VERSION ""

NS_ :

BS_:

BU_: MPAD CVADAS ADCAM ORC EVCU2 EPS ECM CVPAM CADM BSM2 BSM

BO_ 727 CVPAM_FD_Data2: 64 CVADAS
 SG_ PA_SideSensor_RearRight_Dist : 49|10@0+ (1,0) [0|1022] "cm"  MPAD,CADM
 SG_ PA_SideSensor_RearRight_Conf : 102|2@0+ (1,0) [0|3] "" MPAD,CADM
 SG_ PA_SideSensor_RearLeft_Dist : 33|10@0+ (1,0) [0|1022] "cm"  MPAD,CADM
 SG_ PA_SideSensor_RearLeft_Conf : 100|2@0+ (1,0) [0|3] "" MPAD,CADM
 SG_ PA_SideSensor_FrontRight_Dist : 1|10@0+ (1,0) [0|1022] "cm"  MPAD,CADM
 SG_ PA_SideSensor_FrontRight_Conf : 55|2@0+ (1,0) [0|3] "" MPAD,CADM
 SG_ PA_SideSensor_FrontLeft_Dist : 17|10@0+ (1,0) [0|1022] "cm"  MPAD,CADM
 SG_ PA_SideSensor_FrontLeft_Conf : 98|2@0+ (1,0) [0|3] "" MPAD,CADM
 SG_ PA_Right_Sensor_Det_Health : 23|2@0+ (1,0) [0|2] "" MPAD,CADM
 SG_ PA_Line_RM_Style : 68|4@0+ (1,0) [0|7] "" MPAD,CADM
 SG_ PA_Line_RM_Heading : 96|9@0+ (0.5,-128) [-128|127.5] "deg"  MPAD,CADM
 SG_ PA_Line_RM_Color : 87|3@0+ (1,0) [0|4] "" MPAD,CADM
 SG_ PA_Line_LM_Style : 84|4@0+ (1,0) [0|7] "" MPAD,CADM
 SG_ PA_Line_LM_Heading : 112|9@0+ (0.5,-128) [-128|127.5] "deg"  MPAD,CADM
 SG_ PA_Line_LM_Color : 71|3@0+ (1,0) [0|4] "" MPAD,CADM
 SG_ PA_Left_Sensor_Det_Health : 7|2@0+ (1,0) [0|2] "" MPAD,CADM
 SG_ PA_Lane_Dection_Health : 39|2@0+ (1,0) [0|2] "" MPAD,CADM
 SG_ MessageCounter_CVPAM_FD_Data2 : 435|4@0+ (1,0) [0|15] "-"  MPAD,CADM
 SG_ MAC_CVPAM_FD_Data2 : 471|48@0+ (1,0) [0|0] "-"  MPAD,CADM
 SG_ CRC_CVPAM_FD_Data2 : 447|8@0+ (1,0) [0|255] "-"  MPAD,CADM
 SG_ Cntr_CVPAM_FD_Data2 : 455|16@0+ (1,0) [0|65535] "-"  MPAD,CADM
 SG_ Reserved_for_Functional_Safety_ : 431|12@0+ (0,0) [0|0] "" MPAD,CADM
 SG_ PA_Line_RM_Heading_Conf : 37|4@0+ (1,0) [0|15] "" MPAD,CADM
 SG_ PA_Line_RM_Distance_Conf : 5|4@0+ (1,0) [0|15] "" MPAD,CADM
 SG_ PA_Line_RM_Distance : 64|9@0+ (1,0) [0|511] "cm"  MPAD,CADM
 SG_ PA_Line_LM_Heading_Conf : 53|4@0+ (1,0) [0|15] "" MPAD,CADM
 SG_ PA_Line_LM_Distance_Conf : 21|4@0+ (1,0) [0|15] "" MPAD,CADM
 SG_ PA_Line_LM_Distance : 80|9@0+ (1,0) [0|511] "cm"  MPAD,CADM

BO_ 726 CVPAM_FD_Data: 64 CVADAS
 SG_ PA_Obj6_Type : 372|3@0+ (1,0) [0|7] "" MPAD,CADM
 SG_ PA_Obj6_Range_2 : 401|10@0+ (1,0) [0|1023] "cm"  MPAD,CADM
 SG_ PA_Obj6_Range : 81|10@0+ (1,0) [0|1023] "cm"  MPAD,CADM
 SG_ PA_Obj6_Conf : 115|2@0+ (1,0) [0|3] "" MPAD,CADM
 SG_ PA_Obj6_Angle_2 : 208|9@0+ (1,0) [0|511] "deg"  MPAD,CADM
 SG_ PA_Obj6_Angle : 304|9@0+ (1,0) [0|511] "deg"  MPAD,CADM
 SG_ PA_Obj5_Type : 375|3@0+ (1,0) [0|7] "" MPAD,CADM
 SG_ PA_Obj5_Range_2 : 385|10@0+ (1,0) [0|1023] "cm"  MPAD,CADM
 SG_ PA_Obj5_Range : 65|10@0+ (1,0) [0|1023] "cm"  MPAD,CADM
 SG_ PA_Obj5_Conf : 117|2@0+ (1,0) [0|3] "" MPAD,CADM
 SG_ PA_Obj5_Angle_2 : 192|9@0+ (1,0) [0|511] "deg"  MPAD,CADM
 SG_ PA_Obj5_Angle : 288|9@0+ (1,0) [0|511] "deg"  MPAD,CADM
 SG_ PA_Obj4_Type : 391|3@0+ (1,0) [0|7] "" MPAD,CADM
 SG_ PA_Obj4_Range_2 : 369|10@0+ (1,0) [0|1023] "cm"  MPAD,CADM
 SG_ PA_Obj4_Range : 49|10@0+ (1,0) [0|1023] "cm"  MPAD,CADM
 SG_ PA_Obj4_Conf : 119|2@0+ (1,0) [0|3] "" MPAD,CADM
 SG_ PA_Obj4_Angle_2 : 176|9@0+ (1,0) [0|511] "deg"  MPAD,CADM
 SG_ PA_Obj4_Angle : 272|9@0+ (1,0) [0|511] "deg"  MPAD,CADM
 SG_ PA_Obj3_Type : 388|3@0+ (1,0) [0|7] "" MPAD,CADM
 SG_ PA_Obj3_Range_2 : 353|10@0+ (1,0) [0|1023] "cm"  MPAD,CADM
 SG_ PA_Obj3_Range : 33|10@0+ (1,0) [0|1023] "cm"  MPAD,CADM
 SG_ PA_Obj3_Conf : 87|2@0+ (1,0) [0|3] "" MPAD,CADM
 SG_ PA_Obj3_Angle_2 : 160|9@0+ (1,0) [0|511] "deg"  MPAD,CADM
 SG_ PA_Obj3_Angle : 256|9@0+ (1,0) [0|511] "deg"  MPAD,CADM
 SG_ PA_Obj2_Type : 404|3@0+ (1,0) [0|7] "" MPAD,CADM
 SG_ PA_Obj2_Range_2 : 337|10@0+ (1,0) [0|1023] "cm"  MPAD,CADM
 SG_ PA_Obj2_Range : 17|10@0+ (1,0) [0|1023] "cm"  MPAD,CADM
 SG_ PA_Obj2_Conf : 71|2@0+ (1,0) [0|3] "" MPAD,CADM
 SG_ PA_Obj2_Angle_2 : 144|9@0+ (1,0) [0|511] "deg"  MPAD,CADM
 SG_ PA_Obj2_Angle : 240|9@0+ (1,0) [0|511] "deg"  MPAD,CADM
 SG_ PA_Obj1_Type : 407|3@0+ (1,0) [0|7] "" MPAD,CADM
 SG_ PA_Obj1_Range_2 : 321|10@0+ (1,0) [0|1023] "cm"  MPAD,CADM
 SG_ PA_Obj1_Range : 1|10@0+ (1,0) [0|1023] "cm"  MPAD,CADM
 SG_ PA_Obj1_Conf : 55|2@0+ (1,0) [0|3] "" MPAD,CADM
 SG_ PA_Obj1_Angle_2 : 128|9@0+ (1,0) [0|511] "deg"  MPAD,CADM
 SG_ PA_Obj1_Angle : 224|9@0+ (1,0) [0|511] "deg"  MPAD,CADM
 SG_ PA_Front_Sensor_Det_Health : 437|2@0+ (1,0) [0|2] "" MPAD,CADM
 SG_ MessageCounter_CVPAM_FD_Data : 435|4@0+ (1,0) [0|15] "-"  MPAD,CADM,EPS
 SG_ MAC_CVPAM_FD_Data : 471|48@0+ (1,0) [0|0] "-"  MPAD,CADM
 SG_ CRC_CVPAM_FD_Data : 447|8@0+ (1,0) [0|255] "-"  MPAD,CADM,EPS
 SG_ Cntr_CVPAM_FD_Data : 455|16@0+ (1,0) [0|65535] "-"  MPAD,CADM
 SG_ Reserved_for_functional_safety_2D6 : 417|12@0+ (0,0) [0|0] "" MPAD,CADM

BO_ 1156 BRAKE2_FD_3: 32 BSM2
 SG_ RollsModeAct_B2 : 6|1@0+ (1,0) [0|1] "" ADCAM,MPAD,CADM
 SG_ MessageCounter_BRAKE2_3 : 179|4@0+ (1,0) [0|15] "-"  CADM,ORC
 SG_ CRC_BRAKE2_3 : 191|8@0+ (1,0) [0|255] "-"  CADM,ORC
 SG_ BSM2_FaultSts : 5|1@0+ (1,0) [0|1] "" CADM
 SG_ ABSFailSts_B2 : 7|1@0+ (1,0) [0|1] "" MPAD,CADM

BO_ 280 ADAS_FD_INFO: 32 ADCAM
 SG_ Object_Dist : 127|8@0+ (1,0) [0|255] "m"  EVCU2,BSM,ORC,ECM
 SG_ MessageCounter_ADAS_FD_INFO : 179|4@0+ (1,0) [0|15] "-"  CVADAS,EVCU2,BSM2,CVPAM,BSM,ORC,EPS,ECM
 SG_ CRC_ADAS_FD_INFO : 191|8@0+ (1,0) [0|255] "-"  CVADAS,EVCU2,BSM2,CVPAM,BSM,ORC,EPS,ECM
 SG_ ACC_DsrSpeedKPH : 119|8@0+ (1,0) [0|255] "km/h"  EVCU2,ECM
 SG_ Intervention : 163|12@0+ (0.01,-16) [-16|24.95] "m/s2"  EVCU2,BSM2,BSM,ORC
 SG_ HIS_Req : 89|1@0+ (1,0) [0|1] "-"  BSM2,BSM,ORC
 SG_ GrMax_Rq_ACC : 150|4@0+ (1,0) [0|15] "-"  BSM
 SG_ CIPV_Fused : 101|1@0+ (1,0) [0|1] "-"  ORC
 SG_ Brake_Jerk_Req : 100|1@0+ (1,0) [0|1] "-"  BSM2,BSM
 SG_ ACC_Wheel_Torque_Enabled : 93|1@0+ (1,0) [0|1] "-"  EVCU2
 SG_ ACC_Engine_Torque_Enabled : 111|1@0+ (1,0) [0|1] "-"  EVCU2,BSM
 SG_ ACC_Drive_Cmd : 151|1@0+ (1,0) [0|1] "-"  BSM
 SG_ Prefill_Req : 91|1@0+ (1,0) [0|1] "-"  BSM2,BSM
 SG_ PEB_SystemSts : 90|1@0+ (1,0) [0|1] "-"  ORC
 SG_ MRM_STATUS : 23|3@0+ (1,0) [0|6] "" CVADAS,EVCU2,BSM,ORC
 SG_ LANE_CHANGE_SIDE : 95|2@0+ (1,0) [0|2] "" ORC
 SG_ HAS_Status : 106|2@0+ (1,0) [0|3] "" CVADAS,ADCAM,BSM2,CVPAM,BSM,EPS
 SG_ HAS_OpStat_Prim : 4|3@0+ (1,0) [0|5] "" ORC
 SG_ HAS_LAT_CTRL_RequestSts : 110|2@0+ (1,0) [0|3] "-"  EPS
 SG_ ESCALATION_TYPE : 12|3@0+ (1,0) [0|4] "" ORC
 SG_ DDD_SystemSts : 103|1@0+ (1,0) [0|1] "-"  ORC
 SG_ DDD_Setting_Avail : 102|1@0+ (1,0) [0|1] "-"  Vector__XXX
 SG_ CADM_OpStat : 7|3@0+ (1,0) [0|5] "" CVADAS
 SG_ AEB_Type : 167|4@0+ (1,0) [0|14] "-"  EVCU2,BSM2,BSM,ORC
 SG_ AEB_Systemsts : 99|2@0+ (1,0) [0|2] "-"  ORC
 SG_ AEB_Sensitivity_Setting : 1|2@0+ (1,0) [0|2] "" Vector__XXX
 SG_ ACC_Wheel_Torque : 79|16@0+ (2,-36878) [-36878|94190] "-"  EVCU2
 SG_ ACC_Systemsts : 183|4@0+ (1,0) [0|14] "-"  CVADAS,ADCAM,EVCU2,BSM2,CVPAM,BSM,ORC
 SG_ ACC_StopStart : 97|2@0+ (1,0) [0|2] "-"  ECM
 SG_ SteeringVibration_Type : 67|4@0+ (1,0) [0|14] "-"  EPS
 SG_ SteeringVibration_Rq : 135|1@0+ (1,0) [0|1] "-"  EPS
 SG_ LKA_LAT_CTRL_RequestSts : 108|2@0+ (1,0) [0|3] "-"  EPS
 SG_ LANE_CHANGE_STATUS : 71|4@0+ (1,0) [0|14] "" ADCAM,ORC
 SG_ LC_Jerk : 104|1@0+ (1,0) [0|1] "-"  BSM
 SG_ CADM2_EPSSEC_FAIL : 8|1@0+ (1,0) [0|1] "" EPS
 SG_ TorqueOverlaySteeringReq : 130|11@0+ (0.0048828125,-5) [-5|4.995117188] "-"  ORC,EPS
 SG_ ESASystemSts : 31|3@0+ (1,0) [0|6] "-"  BSM,EPS
 SG_ ESA_TorqueOverlaySteeringReq : 39|32@0+ (0.0048828125,-5) [-5|20971514.9951172] "-"  EPS
 SG_ ESA_LAT_CTRL_RequestSts : 28|2@0+ (1,0) [0|2] "-"  EPS
 SG_ ESA_LaneClear_Status : 26|3@0+ (1,0) [0|6] "-"  BSM
 SG_ ESA_FailSts : 17|1@0+ (1,0) [0|1] "-"  BSM,EPS

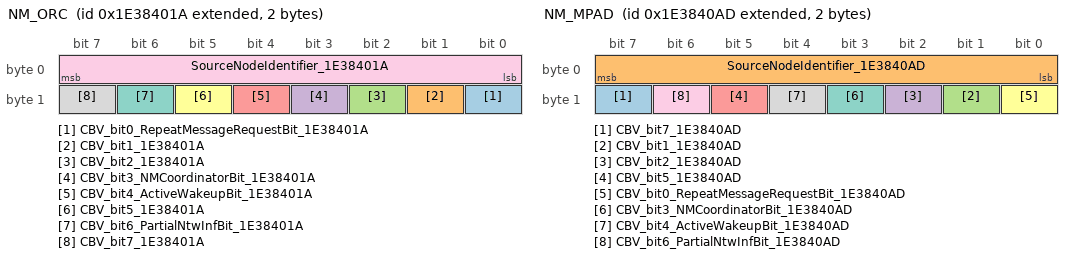
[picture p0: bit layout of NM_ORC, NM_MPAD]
BO_ 2654486554 NM_ORC: 2 ORC
 SG_ CBV_bit0_RepeatMessageRequestBit_1E38401A : 8|1@0+ (1,0) [0|1] "" CVADAS,ADCAM,MPAD,EVCU2,BSM2,CVPAM,CADM,BSM,EPS,ECM
 SG_ CBV_bit1_1E38401A : 9|1@0+ (1,0) [0|1] "" CVADAS,ADCAM,MPAD,EVCU2,BSM2,CVPAM,CADM,BSM,EPS,ECM
 SG_ CBV_bit2_1E38401A : 10|1@0+ (1,0) [0|1] "" CVADAS,ADCAM,MPAD,EVCU2,BSM2,CVPAM,CADM,BSM,EPS,ECM
 SG_ CBV_bit3_NMCoordinatorBit_1E38401A : 11|1@0+ (1,0) [0|1] "" CVADAS,ADCAM,MPAD,EVCU2,BSM2,CVPAM,CADM,BSM,EPS,ECM
 SG_ CBV_bit4_ActiveWakeupBit_1E38401A : 12|1@0+ (1,0) [0|1] "" CVADAS,ADCAM,MPAD,EVCU2,BSM2,CVPAM,CADM,BSM,EPS,ECM
 SG_ CBV_bit5_1E38401A : 13|1@0+ (1,0) [0|1] "" CVADAS,ADCAM,MPAD,EVCU2,BSM2,CVPAM,CADM,BSM,EPS,ECM
 SG_ CBV_bit6_PartialNtwInfBit_1E38401A : 14|1@0+ (1,0) [0|1] "" CVADAS,ADCAM,MPAD,EVCU2,BSM2,CVPAM,CADM,BSM,EPS,ECM
 SG_ CBV_bit7_1E38401A : 15|1@0+ (1,0) [0|1] "" CVADAS,ADCAM,MPAD,EVCU2,BSM2,CVPAM,CADM,BSM,EPS,ECM
 SG_ SourceNodeIdentifier_1E38401A : 7|8@0+ (1,0) [0|255] "-"  CVADAS,ADCAM,MPAD,EVCU2,BSM2,CVPAM,CADM,BSM,EPS,ECM

BO_ 1472 TRSCM_FD_1: 32 CVADAS
 SG_ TRSC_VehicleStop_Req : 36|2@0+ (1,0) [0|2] "" BSM
 SG_ TRSC_STAT : 7|3@0+ (1,0) [0|6] "" EVCU2,BSM,EPS,ECM
 SG_ TRSC_SpeedLimit_Req : 15|4@0+ (1,0) [0|14] "" EVCU2,BSM,ECM
 SG_ THA_STAT : 55|3@0+ (1,0) [0|6] "" EVCU2,BSM,EPS,ECM
 SG_ THA_SpeedLimit_Req : 52|2@0+ (1,0) [0|3] "" EVCU2,BSM,ECM
 SG_ THA_Speed_Limit : 85|5@0+ (1,0) [0|31] "" EVCU2,BSM,EPS,ECM
 SG_ THA_EPB_Req : 95|2@0+ (1,0) [0|3] "" BSM
 SG_ MessageCounter_TRSCM1 : 179|4@0+ (1,0) [0|15] "-"  BSM,EPS,ECM
 SG_ CRC_TRSCM1 : 191|8@0+ (1,0) [0|255] "-"  BSM,EPS,ECM
 SG_ TRSC_SteeringTorqueReq : 11|2@0+ (1,0) [0|2] "" EPS
 SG_ TRSC_SteeringTorqueInfo : 31|11@0+ (0.0078125,-8) [-8|7.9921875] "" EPS
 SG_ TRSC_SteeringDamping : 23|8@0+ (0.78125,0) [0|199.21875] "%"  EPS
 SG_ THA_SteeringTorqueReq : 87|2@0+ (1,0) [0|3] "" EPS
 SG_ THA_SteeringTorqueInfo : 63|11@0+ (0.0078125,-8) [-8|7.9921875] "" EPS
 SG_ THA_SteeringDamping : 79|8@0+ (0.78125,0) [0|199.21875] "%"  EPS

BO_ 205 BRAKE_FD_6: 64 BSM
 SG_ CRC_BRAKE_FD_6 : 447|8@0+ (1,0) [0|255] "-"  EVCU2,ECM
 SG_ MessageCounter_BRAKE_FD_6 : 435|4@0+ (1,0) [0|15] "-"  EVCU2,ECM
 SG_ RearAxle_Min_Rq_BSM : 52|1@0+ (1,0) [0|1] "" EVCU2
 SG_ RearAxle_Max_Rq_BSM : 53|1@0+ (1,0) [0|1] "" EVCU2
 SG_ FrontAxle_Min_Rq_BSM : 54|1@0+ (1,0) [0|1] "" EVCU2
 SG_ FrontAxle_Max_Rq_BSM : 55|1@0+ (1,0) [0|1] "" EVCU2
 SG_ TotalAxle_Min_Rq_BSM : 50|1@0+ (1,0) [0|1] "" ECM
 SG_ TotalAxle_Max_Rq_BSM : 51|1@0+ (1,0) [0|1] "" ECM
 SG_ DrvrIntd_TotalBrk_AxleTorq : 142|15@0+ (2,0) [0|65532] "Nm"  EVCU2
 SG_ DriverReq_AxleTrq_Enabled_BSM : 175|4@0+ (1,0) [0|15] "" CVADAS,EVCU2,ECM
 SG_ Cmnd_TotBrkFrict_AxleTorq : 126|15@0+ (2,0) [0|65532] "Nm"  EVCU2
 SG_ TotalAxle_Rq_BSM : 95|16@0+ (2,-65534) [-65534|65536] "Nm"  ECM
 SG_ DriverRequested_AxleTrq_BSM : 159|16@0+ (2,-65534) [-65534|65536] "Nm"  EVCU2,CVPAM,ECM
 SG_ RearAxle_Rq_BSM : 79|16@0+ (2,-65534) [-65534|65536] "Nm"  EVCU2
 SG_ FrontAxle_Rq_BSM : 63|16@0+ (2,-65534) [-65534|65536] "Nm"  EVCU2

BO_ 204 AXLE_TORQUE_FD_1: 48 EVCU2
 SG_ MessageCounter_AXLE_TORQUE_FD_1 : 307|4@0+ (1,0) [0|15] "-"  ADCAM,CADM,BSM
 SG_ CRC_AXLE_TORQUE_FD_1 : 319|8@0+ (1,0) [0|255] "-"  ADCAM,CADM,BSM
 SG_ Rear_Axle_Regen_Capacity : 197|14@0+ (2,0) [0|32764] "Nm"  BSM
 SG_ Rear_Axle_Est_Regen_Torq : 181|14@0+ (2,0) [0|32764] "Nm"  BSM
 SG_ Front_Axle_Regen_Capacity : 165|14@0+ (2,0) [0|32764] "Nm"  BSM
 SG_ Front_Axle_Est_Regen_Torq : 149|14@0+ (2,0) [0|32764] "Nm"  BSM
 SG_ Total_AxleTorque_Min : 23|16@0+ (2,-65534) [-65534|65536] "Nm"  ADCAM,MPAD,CADM,BSM
 SG_ Total_AxleTorque_Max : 7|16@0+ (2,-65534) [-65534|65536] "Nm"  ADCAM,MPAD,CADM
 SG_ Axle_TorqueStatic_D_TTC : 39|16@0+ (2,-65534) [-65534|65536] "Nm"  ADCAM,MPAD,CADM,BSM
 SG_ Axle_Torque_DrvReqMod : 55|16@0+ (2,-65534) [-65534|65536] "Nm"  ADCAM,MPAD,CADM,BSM
 SG_ Rear_AxleTorque_Min : 119|16@0+ (2,-65534) [-65534|65536] "Nm"  BSM
 SG_ Rear_AxleTorque_Max : 103|16@0+ (2,-65534) [-65534|65536] "Nm"  BSM
 SG_ Front_AxleTorque_Min : 87|16@0+ (2,-65534) [-65534|65536] "Nm"  BSM
 SG_ Front_AxleTorque_Max : 71|16@0+ (2,-65534) [-65534|65536] "Nm"  BSM

BO_ 292 BATTERY_HV_STATUS1: 64 EVCU2
 SG_ BPCM_HV_Trac_Main_Contac_Sts : 181|3@0+ (1,0) [0|7] "" Vector__XXX
 SG_ BPCM_HV_Trac_Bus_Sts : 36|3@0+ (1,0) [0|7] "" ORC
 SG_ BPCM_HV_SOC : 33|10@0+ (0.1,0) [0|102.3] "%"  BSM
 SG_ BPCM_HV_InternalVoltage : 133|14@0+ (0.1,90.9) [90.9|1729.2] "V"  ORC
 SG_ MessageCounter_BATT_HV_STATUS1 : 435|4@0+ (1,0) [0|15] "" ORC,BSM
 SG_ CRC_BATT_HV_STATUS1 : 447|8@0+ (1,0) [0|255] "" ORC,BSM

BO_ 2654486701 NM_MPAD: 2 MPAD
 SG_ CBV_bit7_1E3840AD : 15|1@0+ (1,0) [0|1] "" CVADAS,ADCAM,EVCU2,BSM2,BSM,ORC,EPS
 SG_ SourceNodeIdentifier_1E3840AD : 7|8@0+ (1,0) [0|255] "-"  CVADAS,ADCAM,EVCU2,BSM2,BSM,ORC,EPS
 SG_ CBV_bit1_1E3840AD : 9|1@0+ (1,0) [0|1] "" CVADAS,ADCAM,EVCU2,BSM2,BSM,ORC,EPS
 SG_ CBV_bit2_1E3840AD : 10|1@0+ (1,0) [0|1] "" CVADAS,ADCAM,EVCU2,BSM2,BSM,ORC,EPS
 SG_ CBV_bit5_1E3840AD : 13|1@0+ (1,0) [0|1] "" CVADAS,ADCAM,EVCU2,BSM2,BSM,ORC,EPS
 SG_ CBV_bit0_RepeatMessageRequestBit_1E3840AD : 8|1@0+ (1,0) [0|1] "-"  CVADAS,ADCAM,EVCU2,BSM2,BSM,ORC,EPS
 SG_ CBV_bit3_NMCoordinatorBit_1E3840AD : 11|1@0+ (1,0) [0|1] "-"  CVADAS,ADCAM,EVCU2,BSM2,BSM,ORC,EPS
 SG_ CBV_bit4_ActiveWakeupBit_1E3840AD : 12|1@0+ (1,0) [0|1] "-"  CVADAS,ADCAM,EVCU2,BSM2,BSM,ORC,EPS
 SG_ CBV_bit6_PartialNtwInfBit_1E3840AD : 14|1@0+ (1,0) [0|1] "-"  CVADAS,ADCAM,EVCU2,BSM2,BSM,ORC,EPS

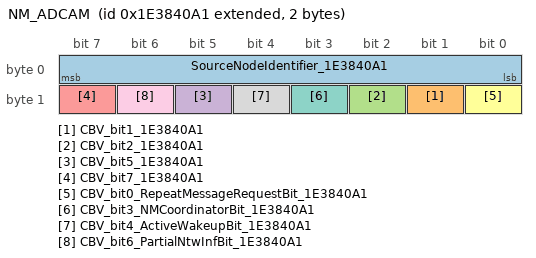
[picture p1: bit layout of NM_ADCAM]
BO_ 2654486689 NM_ADCAM: 2 ADCAM
 SG_ SourceNodeIdentifier_1E3840A1 : 7|8@0+ (1,0) [0|255] "-"  CVADAS,MPAD,EVCU2,BSM2,BSM,ORC,EPS,ECM
 SG_ CBV_bit1_1E3840A1 : 9|1@0+ (1,0) [0|1] "" CVADAS,MPAD,EVCU2,BSM2,BSM,ORC,EPS,ECM
 SG_ CBV_bit2_1E3840A1 : 10|1@0+ (1,0) [0|1] "" CVADAS,MPAD,EVCU2,BSM2,BSM,ORC,EPS,ECM
 SG_ CBV_bit5_1E3840A1 : 13|1@0+ (1,0) [0|1] "" CVADAS,MPAD,EVCU2,BSM2,BSM,ORC,EPS,ECM
 SG_ CBV_bit7_1E3840A1 : 15|1@0+ (1,0) [0|1] "" CVADAS,MPAD,EVCU2,BSM2,BSM,ORC,EPS,ECM
 SG_ CBV_bit0_RepeatMessageRequestBit_1E3840A1 : 8|1@0+ (1,0) [0|1] "-"  CVADAS,MPAD,EVCU2,BSM2,BSM,ORC,EPS,ECM
 SG_ CBV_bit3_NMCoordinatorBit_1E3840A1 : 11|1@0+ (1,0) [0|1] "-"  CVADAS,MPAD,EVCU2,BSM2,BSM,ORC,EPS,ECM
 SG_ CBV_bit4_ActiveWakeupBit_1E3840A1 : 12|1@0+ (1,0) [0|1] "-"  CVADAS,MPAD,EVCU2,BSM2,BSM,ORC,EPS,ECM
 SG_ CBV_bit6_PartialNtwInfBit_1E3840A1 : 14|1@0+ (1,0) [0|1] "-"  CVADAS,MPAD,EVCU2,BSM2,BSM,ORC,EPS,ECM

BO_TX_BU_ 727 : CVADAS,CVPAM;
BO_TX_BU_ 726 : CVADAS,CVPAM;
BO_TX_BU_ 280 : ADCAM,MPAD,CADM;
BO_TX_BU_ 1472 : CVADAS,CVPAM;
BO_TX_BU_ 204 : EVCU2,ECM;
CM_ SG_ 280 Object_Dist "It indicates the distance to the recognized object";
CM_ SG_ 280 MessageCounter_ADAS_FD_INFO "This signal is a counter used for safety checks strategies. This counter is incremented of 1 (one) unit at each frame transmission.";
CM_ SG_ 280 CRC_ADAS_FD_INFO "CRC according to SAE J1850 standard at each frame transmission.";
CM_ SG_ 280 ACC_DsrSpeedKPH "Desired speed in kilometers per hour";
CM_ SG_ 280 Intervention "Request to set target acceleration/deceleration for any feature";
CM_ SG_ 280 HIS_Req "Used to command Stop during Stop and Go ACC and FSFCW+";
CM_ SG_ 280 GrMax_Rq_ACC "Used to request Max Gear from TCM";
CM_ SG_ 280 CIPV_Fused "Closest in-path vehicle is fused True = 1";
CM_ SG_ 280 Brake_Jerk_Req "Request from DASM to perform Jerk Warning";
CM_ SG_ 280 ACC_Wheel_Torque_Enabled "An enable bit that Torque commands should be followed";
CM_ SG_ 280 ACC_Engine_Torque_Enabled "An enable bit that Torque commands should be followed";
CM_ SG_ 280 ACC_Drive_Cmd "ACC Drive Command";
CM_ SG_ 280 Prefill_Req "Prefill command of Brake System by DASM";
CM_ SG_ 280 PEB_SystemSts "PEB System Status";
CM_ SG_ 280 MRM_STATUS "Status of the minimum risk maneuver to handle system faults or driver abuse as understood by primary controller";
CM_ SG_ 280 LANE_CHANGE_SIDE "Direction of the currently in-progress lane change from a vehicle perspective";
CM_ SG_ 280 HAS_Status "Highway Assist System Status as reported by the main controller";
CM_ SG_ 280 HAS_OpStat_Prim "Capability of the primary controller to perform sensing, computing, and actuation";
CM_ SG_ 280 HAS_LAT_CTRL_RequestSts "HAS_LAT_CTRL_RequestSts";
CM_ SG_ 280 ESCALATION_TYPE "Type of HMI escalation to be provided to driver from primary controller";
CM_ SG_ 280 DDD_SystemSts "DDD System Status";
CM_ SG_ 280 DDD_Setting_Avail "DDD_Setting Av Status";
CM_ SG_ 280 CADM_OpStat "Capability of primary controller to sense and compute a valid trajectory path based on external data dependencies and internal failures";
CM_ SG_ 280 AEB_Type "AEB Type";
CM_ SG_ 280 AEB_Systemsts "AEB System Status";
CM_ SG_ 280 AEB_Sensitivity_Setting "AEB sensitivity status";
CM_ SG_ 280 ACC_Wheel_Torque "It indicates the requested wheel torque value of ACC function";
CM_ SG_ 280 ACC_Systemsts "ACC System Status";
CM_ SG_ 280 ACC_StopStart "Allows StopStart when ACC is engaged";
CM_ SG_ 727 PA_SideSensor_RearRight_Dist "PA SideSensor RearRight Dist";
CM_ SG_ 727 PA_SideSensor_RearRight_Conf "PA SideSensor RearRight Conf";
CM_ SG_ 727 PA_SideSensor_RearLeft_Dist "PA SideSensor RearLeft Dist";
CM_ SG_ 727 PA_SideSensor_RearLeft_Conf "PA SideSensor RearLeft Conf";
CM_ SG_ 727 PA_SideSensor_FrontRight_Dist "PA SideSensor FrontRight Dist";
CM_ SG_ 727 PA_SideSensor_FrontRight_Conf "PA SideSensor FrontRight Conf";
CM_ SG_ 727 PA_SideSensor_FrontLeft_Dist "PA SideSensor FrontLeft Dist";
CM_ SG_ 727 PA_SideSensor_FrontLeft_Conf "PA SideSensor FrontLeft Conf";
CM_ SG_ 727 PA_Right_Sensor_Det_Health "PA Right Sensor Det Health";
CM_ SG_ 727 PA_Line_RM_Style "PA Line RM Style";
CM_ SG_ 727 PA_Line_RM_Heading "PA Line RM Heading";
CM_ SG_ 727 PA_Line_RM_Color "PA Line RM Color";
CM_ SG_ 727 PA_Line_LM_Style "PA Line LM Style";
CM_ SG_ 727 PA_Line_LM_Heading "PA Line LM Heading";
CM_ SG_ 727 PA_Line_LM_Color "PA Line LM Color";
CM_ SG_ 727 PA_Left_Sensor_Det_Health "PA Left Sensor Det Health";
CM_ SG_ 727 PA_Lane_Dection_Health "PA Lane Dection Health";
CM_ SG_ 727 MessageCounter_CVPAM_FD_Data2 "This signal is a counter used for safety checks strategies. This counter is incremented of 1 (one) unit at each frame transmission.";
CM_ SG_ 727 MAC_CVPAM_FD_Data2 "-";
CM_ SG_ 727 CRC_CVPAM_FD_Data2 "CRC according to SAE J1850 standard at each frame transmission.";
CM_ SG_ 726 PA_Obj6_Type "PA Obj5 Type";
CM_ SG_ 726 PA_Obj6_Range_2 "PA Obj6 Range_2";
CM_ SG_ 726 PA_Obj6_Range "PA Obj6 Range";
CM_ SG_ 726 PA_Obj6_Conf "PA Obj6 Conf";
CM_ SG_ 726 PA_Obj6_Angle_2 "PA Obj6 Angle_2";
CM_ SG_ 726 PA_Obj6_Angle "PA Obj6 Angle";
CM_ SG_ 726 PA_Obj5_Type "PA Obj5 Type";
CM_ SG_ 726 PA_Obj5_Range_2 "PA Obj5 Range_2";
CM_ SG_ 726 PA_Obj5_Range "PA Obj5 Range";
CM_ SG_ 726 PA_Obj5_Conf "PA Obj5 Conf";
CM_ SG_ 726 PA_Obj5_Angle_2 "PA Obj5 Angle_2";
CM_ SG_ 726 PA_Obj5_Angle "PA Obj5 Angle";
CM_ SG_ 726 PA_Obj4_Type "PA Obj4 Type";
CM_ SG_ 726 PA_Obj4_Range_2 "PA Obj4 Range_2";
CM_ SG_ 726 PA_Obj4_Range "PA Obj4 Range";
CM_ SG_ 726 PA_Obj4_Conf "PA Obj4 Conf";
CM_ SG_ 726 PA_Obj4_Angle_2 "PA Obj4 Angle_2";
CM_ SG_ 726 PA_Obj4_Angle "PA Obj4 Angle";
CM_ SG_ 726 PA_Obj3_Type "PA Obj3 Type";
CM_ SG_ 726 PA_Obj3_Range_2 "PA Obj3 Range_2";
CM_ SG_ 726 PA_Obj3_Range "PA Obj3 Range";
CM_ SG_ 726 PA_Obj3_Conf "PA Obj3 Conf";
CM_ SG_ 726 PA_Obj3_Angle_2 "PA Obj3 Angle_2";
CM_ SG_ 726 PA_Obj3_Angle "PA Obj3 Angle";
CM_ SG_ 726 PA_Obj2_Type "PA Obj2 Type";
CM_ SG_ 726 PA_Obj2_Range_2 "PA Obj2 Range_2";
CM_ SG_ 726 PA_Obj2_Range "PA Obj2 Range";
CM_ SG_ 726 PA_Obj2_Conf "PA Obj2 Conf";
CM_ SG_ 726 PA_Obj2_Angle_2 "PA Obj2 Angle_2";
CM_ SG_ 726 PA_Obj2_Angle "PA Obj2 Angle";
CM_ SG_ 726 PA_Obj1_Type "PA Obj1 Type";
CM_ SG_ 726 PA_Obj1_Range_2 "PA Obj1 Range_2";
CM_ SG_ 726 PA_Obj1_Range "PA Obj1 Range";
CM_ SG_ 726 PA_Obj1_Conf "PA Obj1 Conf";
CM_ SG_ 726 PA_Obj1_Angle_2 "PA Obj1 Angle_2";
CM_ SG_ 726 PA_Obj1_Angle "PA Obj1 Angle";
CM_ SG_ 726 PA_Front_Sensor_Det_Health "PA Front Sensor Det Health";
CM_ SG_ 726 MessageCounter_CVPAM_FD_Data "This signal is a counter used for safety checks strategies. This counter is incremented of 1 (one) unit at each frame transmission.";
CM_ SG_ 726 MAC_CVPAM_FD_Data "-";
CM_ SG_ 726 CRC_CVPAM_FD_Data "CRC according to SAE J1850 standard at each frame transmission.";
CM_ SG_ 1156 RollsModeAct_B2 "RollsModeAct_B2";
CM_ SG_ 1156 MessageCounter_BRAKE2_3 "This signal is a counter used for safety checks strategies. This counter is incremented of 1 (one) unit at each frame transmission.";
CM_ SG_ 1156 CRC_BRAKE2_3 "CRC according to SAE J1850 standard at each frame transmission.";
CM_ SG_ 1156 BSM2_FaultSts "BSM2 FaultSts";
CM_ SG_ 1156 ABSFailSts_B2 "ABSFailSts_B2";
CM_ SG_ 280 SteeringVibration_Type "Type of Steering Wheel Vibration Request";
CM_ SG_ 280 SteeringVibration_Rq "Request to activate Steering Wheel Vibration";
CM_ SG_ 280 LKA_LAT_CTRL_RequestSts "LKA_LAT_CTRL_RequestSts";
CM_ SG_ 280 LANE_CHANGE_STATUS "Status of assisted lane change maneuver";
CM_ SG_ 280 LC_Jerk "Lane Centering request for brake jerk";
CM_ SG_ 280 CADM2_EPSSEC_FAIL "CADM2 detection of failure to communicate to EPS";
CM_ SG_ 1472 TRSC_VehicleStop_Req "TRSC break activation request";
CM_ SG_ 1472 TRSC_STAT "Trailer Reverse steering status signal";
CM_ SG_ 1472 TRSC_SpeedLimit_Req "TRSC ECM Speed limit request";
CM_ SG_ 1472 THA_STAT "Current trailer hitch assist maneuver state";
CM_ SG_ 205 CRC_BRAKE_FD_6 "CRC according to SAE J1850 standard at each frame transmission.";
CM_ SG_ 205 MessageCounter_BRAKE_FD_6 "This signal is a counter used for safety checks strategies. This counter is incremented of 1 (one) unit at each frame transmission.";
CM_ SG_ 205 RearAxle_Min_Rq_BSM "Rear axle traction torque min limit  flag. Active = [1]";
CM_ SG_ 205 RearAxle_Max_Rq_BSM "Rear axle traction torque max limit  flag. Active = [1]";
CM_ SG_ 205 FrontAxle_Min_Rq_BSM "Front axle traction torque min limit flag. Active = [1]";
CM_ SG_ 205 FrontAxle_Max_Rq_BSM "Front axle traction torque max limit flag. Active = [1]";
CM_ SG_ 205 TotalAxle_Min_Rq_BSM "Combined axle traction torque min limit flag. Active = [1]";
CM_ SG_ 205 TotalAxle_Max_Rq_BSM "Combined axle traction torque max limit flag. Active = [1]";
CM_ SG_ 205 DrvrIntd_TotalBrk_AxleTorq "Total Brake Torque in Axle domain";
CM_ SG_ 205 DriverReq_AxleTrq_Enabled_BSM "It indicates the request to enable virtual driver torque interface for BSM driver functions";
CM_ SG_ 205 Cmnd_TotBrkFrict_AxleTorq "Commanded Total Brake Friction torque in Axle domain";
CM_ SG_ 204 MessageCounter_AXLE_TORQUE_FD_1 "This signal is a counter used for safety checks strategies. This counter is incremented of 1 (one) unit at each frame transmission.";
CM_ SG_ 204 CRC_AXLE_TORQUE_FD_1 "CRC according to SAE J1850 standard at each frame transmission.";
CM_ SG_ 204 Rear_Axle_Regen_Capacity "Regenerative Braking rear Axle Torque Capability";
CM_ SG_ 204 Rear_Axle_Est_Regen_Torq "Estimated regen Braking Torque at the Rear axle";
CM_ SG_ 204 Front_Axle_Regen_Capacity "Regenerative Braking front Axle Torque Capability";
CM_ SG_ 204 Front_Axle_Est_Regen_Torq "Estimated regen Braking Torque at the Front axle";
CM_ SG_ 292 BPCM_HV_Trac_Main_Contac_Sts "Traction main contactor physical relay status";
CM_ SG_ 1472 THA_SpeedLimit_Req "THA requested speed limit";
CM_ SG_ 1472 THA_Speed_Limit "THA Speed Limiter Threshold";
CM_ SG_ 1472 THA_EPB_Req "THA EPB securement request";
CM_ SG_ 1472 MessageCounter_TRSCM1 "This signal is a counter used for safety checks strategies. This counter is incremented of 1 (one) unit at each frame transmission.";
CM_ SG_ 1472 CRC_TRSCM1 "CRC according to SAE J1850 standard at each frame transmission.";
CM_ SG_ 205 TotalAxle_Rq_BSM "Combined axle traction torque request";
CM_ SG_ 205 DriverRequested_AxleTrq_BSM "Virtual driver torque request from BSM";
CM_ SG_ 204 Total_AxleTorque_Min "Minimum total Axle torque";
CM_ SG_ 204 Total_AxleTorque_Max "Maximum total Axle torque";
CM_ SG_ 204 Axle_TorqueStatic_D_TTC "Driver requested Axle torque (filtered/ torque shaped)";
CM_ SG_ 204 Axle_Torque_DrvReqMod "Driver requested Axle torque raw (no torque shaping)";
CM_ SG_ 280 TorqueOverlaySteeringReq "TorqueOverlaySteeringReq";
CM_ SG_ 292 BPCM_HV_SOC "State of Charge";
CM_ SG_ 292 BPCM_HV_InternalVoltage "Battery internal voltage.";
CM_ SG_ 292 CRC_BATT_HV_STATUS1 "CRC according to SAE J1850 standard at each frame transmission.";
CM_ SG_ 292 MessageCounter_BATT_HV_STATUS1 "This signal is a counter used for safety checks strategies. This counter is incremented of 1 (one) unit at each frame transmission.";
CM_ SG_ 205 RearAxle_Rq_BSM "Rear axle traction control torque request";
CM_ SG_ 205 FrontAxle_Rq_BSM "Front axle traction control torque request";
CM_ SG_ 204 Rear_AxleTorque_Min "Minimum rear Axle torque";
CM_ SG_ 204 Rear_AxleTorque_Max "Maximum rear Axle torque";
CM_ SG_ 204 Front_AxleTorque_Min "Minimum front Axle torque";
CM_ SG_ 204 Front_AxleTorque_Max "Maximum front Axle torque";
CM_ SG_ 280 ESASystemSts "ESA System Status";
CM_ SG_ 280 ESA_TorqueOverlaySteeringReq "ESA Steering Torque Overlay Request";
CM_ SG_ 280 ESA_LAT_CTRL_RequestSts "ESA Lateral Control Request Status";
CM_ SG_ 280 ESA_LaneClear_Status "Lane Clear Information";
CM_ SG_ 280 ESA_FailSts "ESA Failure Status";
CM_ SG_ 1472 TRSC_SteeringTorqueReq "TRSC steering torque overlay activation request";
CM_ SG_ 1472 TRSC_SteeringTorqueInfo "TRSC Steering Torque";
CM_ SG_ 1472 TRSC_SteeringDamping "TRSC Steering damping percentage";
CM_ SG_ 727 PA_Line_RM_Heading_Conf "PA Line RM Heading Conf";
CM_ SG_ 727 PA_Line_RM_Distance_Conf "PA Line RM Distance Conf";
CM_ SG_ 727 PA_Line_RM_Distance "PA Line RM Distance";
CM_ SG_ 727 PA_Line_LM_Heading_Conf "PA Line LM Heading Conf";
CM_ SG_ 727 PA_Line_LM_Distance_Conf "PA Line LM Distance Conf";
CM_ SG_ 727 PA_Line_LM_Distance "PA Line LM Distance";
CM_ SG_ 1472 THA_SteeringTorqueReq "Trailer Hitch Assist steering torque request";
CM_ SG_ 1472 THA_SteeringTorqueInfo "THA Steering Torque";
CM_ SG_ 1472 THA_SteeringDamping "THA Steering Damping";
CM_ SG_ 2654486701 SourceNodeIdentifier_1E3840AD "Source Node Identifier";
CM_ SG_ 2654486701 CBV_bit0_RepeatMessageRequestBit_1E3840AD "Repeat Message Request Bit";
CM_ SG_ 2654486701 CBV_bit3_NMCoordinatorBit_1E3840AD "NM Coordinator Sleep Bit";
CM_ SG_ 2654486701 CBV_bit4_ActiveWakeupBit_1E3840AD "Active Wakeup Bit";
CM_ SG_ 2654486701 CBV_bit6_PartialNtwInfBit_1E3840AD "Partial Network Information Bit (PNI)";
CM_ SG_ 2654486689 SourceNodeIdentifier_1E3840A1 "Source Node Identifier";
CM_ SG_ 2654486689 CBV_bit0_RepeatMessageRequestBit_1E3840A1 "Repeat Message Request Bit";
CM_ SG_ 2654486689 CBV_bit3_NMCoordinatorBit_1E3840A1 "NM Coordinator Sleep Bit";
CM_ SG_ 2654486689 CBV_bit4_ActiveWakeupBit_1E3840A1 "Active Wakeup Bit";
CM_ SG_ 2654486689 CBV_bit6_PartialNtwInfBit_1E3840A1 "Partial Network Information Bit (PNI)";
CM_ SG_ 2654486554 CBV_bit0_RepeatMessageRequestBit_1E38401A "Repeat Message Request Bit";
CM_ SG_ 2654486554 CBV_bit3_NMCoordinatorBit_1E38401A "NM Coordinator Sleep Bit";
CM_ SG_ 2654486554 CBV_bit4_ActiveWakeupBit_1E38401A "Active Wakeup Bit";
CM_ SG_ 2654486554 CBV_bit6_PartialNtwInfBit_1E38401A "Partial Network Information Bit (PNI)";
CM_ SG_ 2654486554 SourceNodeIdentifier_1E38401A "Source Node Identifier";
BA_DEF_ SG_ "GenSigTimeoutTime_MPAD" INT 0 65535;
BA_DEF_ SG_ "GenSigTimeoutTime_ADCAM" INT 0 65535;
BA_DEF_ SG_ "GenSigTimeoutTime_CVADAS" INT 0 65535;
BA_DEF_ SG_ "GenSigTimeoutTime_VDCM" INT 0 65535;
BA_DEF_ SG_ "GenSigStartValue" INT 0 2147483647;
BA_DEF_ SG_ "GenSigInactiveValue" INT 0 2147483647;
BA_DEF_ SG_ "GenSigSendType" ENUM "NotUsed","OnWrite","OnWriteWithRepetition","OnChange","OnChangeWithRepetition","IfActive","IfActiveWithRepetition","NoSigSendType";
BA_DEF_ SG_ "SystemSignalLongSymbol" STRING ;
BA_DEF_ SG_ "GenSigTimeoutTime_BSM" INT 0 65535;
BA_DEF_ SG_ "GenSigTimeoutTime_BSM2" INT 0 65535;
BA_DEF_ SG_ "GenSigTimeoutTime_CADM" INT 0 65535;
BA_DEF_ SG_ "GenSigTimeoutTime_CVPAM" INT 0 65535;
BA_DEF_ SG_ "GenSigTimeoutTime_ECM" INT 0 65535;
BA_DEF_ SG_ "GenSigTimeoutTime_EPS" INT 0 65535;
BA_DEF_ SG_ "GenSigTimeoutTime_EVCU2" INT 0 65535;
BA_DEF_ SG_ "GenSigTimeoutTime_ORC" INT 0 65535;
BA_DEF_ BO_ "DiagRequest" ENUM "No","Yes";
BA_DEF_ BO_ "Type" ENUM "P","C","PE","COC","PE_Cntrl","E","E_Cntrl","OC","S","BAF","DC","EM","MM","ISO-TP","-";
BA_DEF_ BO_ "DiagResponse" ENUM "No","Yes";
BA_DEF_ BO_ "NmMessage" ENUM "No","Yes";
BA_DEF_ BO_ "GenMsgSendType" ENUM "Cyclic","NotUsed","NotUsed","NotUsed","NotUsed","NotUsed","NotUsed","NotUsed","NoMsgSendType";
BA_DEF_ BO_ "GenMsgNrOfRepetition" INT 0 255;
BA_DEF_ BO_ "GenMsgILSupport" ENUM "No","Yes";
BA_DEF_ BO_ "GenMsgStartDelayTime" INT 0 65535;
BA_DEF_ BO_ "GenMsgCycleTimeFast" INT 0 65535;
BA_DEF_ BO_ "GenMsgCycleTime" INT 0 65535;
BA_DEF_ BO_ "GenMsgDelayTime" INT 0 65535;
BA_DEF_ BO_ "NmAsrMessage" ENUM "No","Yes";
BA_DEF_ BO_ "DiagState" ENUM "No","Yes";
BA_DEF_ BO_ "DiagConnection" HEX 0 65535;
BA_DEF_ BO_ "VFrameFormat" ENUM "StandardCAN","ExtendedCAN","reserved","reserved","reserved","reserved","reserved","reserved","reserved","reserved","reserved","reserved","reserved","reserved","StandardCAN_FD","ExtendedCAN_FD";
BA_DEF_ BO_ "CANFD_BRS" ENUM "0","1";
BA_DEF_DEF_ "GenSigTimeoutTime_MPAD" 2500;
BA_DEF_DEF_ "GenSigTimeoutTime_ADCAM" 2500;
BA_DEF_DEF_ "GenSigTimeoutTime_CVADAS" 2500;
BA_DEF_DEF_ "GenSigTimeoutTime_VDCM" 2500;
BA_DEF_DEF_ "GenSigStartValue" 0;
BA_DEF_DEF_ "GenSigInactiveValue" 0;
BA_DEF_DEF_ "GenSigSendType" "NoSigSendType";
BA_DEF_DEF_ "SystemSignalLongSymbol" "";
BA_DEF_DEF_ "GenSigTimeoutTime_BSM" 2500;
BA_DEF_DEF_ "GenSigTimeoutTime_BSM2" 2500;
BA_DEF_DEF_ "GenSigTimeoutTime_CADM" 2500;
BA_DEF_DEF_ "GenSigTimeoutTime_CVPAM" 2500;
BA_DEF_DEF_ "GenSigTimeoutTime_ECM" 2500;
BA_DEF_DEF_ "GenSigTimeoutTime_EPS" 2500;
BA_DEF_DEF_ "GenSigTimeoutTime_EVCU2" 2500;
BA_DEF_DEF_ "GenSigTimeoutTime_ORC" 2500;
BA_DEF_DEF_ "DiagRequest" "No";
BA_DEF_DEF_ "Type" "-";
BA_DEF_DEF_ "DiagResponse" "No";
BA_DEF_DEF_ "NmMessage" "No";
BA_DEF_DEF_ "GenMsgSendType" "NoMsgSendType";
BA_DEF_DEF_ "GenMsgNrOfRepetition" 0;
BA_DEF_DEF_ "GenMsgILSupport" "No";
BA_DEF_DEF_ "GenMsgStartDelayTime" 0;
BA_DEF_DEF_ "GenMsgCycleTimeFast" 0;
BA_DEF_DEF_ "GenMsgCycleTime" 0;
BA_DEF_DEF_ "GenMsgDelayTime" 0;
BA_DEF_DEF_ "NmAsrMessage" "No";
BA_DEF_DEF_ "DiagState" "No";
BA_DEF_DEF_ "DiagConnection" 0;
BA_DEF_DEF_ "VFrameFormat" "StandardCAN_FD";
BA_DEF_DEF_ "CANFD_BRS" "0";
BA_ "Type" BO_ 727 1;
BA_ "GenMsgSendType" BO_ 727 0;
BA_ "GenMsgILSupport" BO_ 727 1;
BA_ "GenMsgCycleTime" BO_ 727 40;
BA_ "CANFD_BRS" BO_ 727 1;
BA_ "GenMsgSendType" BO_ 726 0;
BA_ "GenMsgILSupport" BO_ 726 1;
BA_ "GenMsgCycleTime" BO_ 726 40;
BA_ "CANFD_BRS" BO_ 726 1;
BA_ "Type" BO_ 726 1;
BA_ "Type" BO_ 1156 3;
BA_ "GenMsgSendType" BO_ 1156 0;
BA_ "GenMsgNrOfRepetition" BO_ 1156 2;
BA_ "GenMsgILSupport" BO_ 1156 1;
BA_ "GenMsgCycleTimeFast" BO_ 1156 20;
BA_ "GenMsgCycleTime" BO_ 1156 500;
BA_ "GenMsgDelayTime" BO_ 1156 20;
BA_ "CANFD_BRS" BO_ 1156 1;
BA_ "Type" BO_ 280 1;
BA_ "GenMsgSendType" BO_ 280 0;
BA_ "GenMsgILSupport" BO_ 280 1;
BA_ "GenMsgCycleTime" BO_ 280 10;
BA_ "CANFD_BRS" BO_ 280 1;
BA_ "Type" BO_ 2654486554 8;
BA_ "NmMessage" BO_ 2654486554 1;
BA_ "NmAsrMessage" BO_ 2654486554 1;
BA_ "VFrameFormat" BO_ 2654486554 15;
BA_ "CANFD_BRS" BO_ 2654486554 1;
BA_ "Type" BO_ 1472 3;
BA_ "GenMsgSendType" BO_ 1472 0;
BA_ "GenMsgILSupport" BO_ 1472 1;
BA_ "GenMsgCycleTime" BO_ 1472 1000;
BA_ "GenMsgDelayTime" BO_ 1472 20;
BA_ "CANFD_BRS" BO_ 1472 1;
BA_ "Type" BO_ 205 1;
BA_ "GenMsgSendType" BO_ 205 0;
BA_ "GenMsgILSupport" BO_ 205 1;
BA_ "GenMsgCycleTime" BO_ 205 10;
BA_ "CANFD_BRS" BO_ 205 1;
BA_ "Type" BO_ 204 1;
BA_ "GenMsgSendType" BO_ 204 0;
BA_ "GenMsgILSupport" BO_ 204 1;
BA_ "GenMsgCycleTime" BO_ 204 10;
BA_ "CANFD_BRS" BO_ 204 1;
BA_ "Type" BO_ 292 1;
BA_ "GenMsgSendType" BO_ 292 0;
BA_ "GenMsgILSupport" BO_ 292 1;
BA_ "GenMsgCycleTime" BO_ 292 10;
BA_ "CANFD_BRS" BO_ 292 1;
BA_ "Type" BO_ 2654486701 8;
BA_ "NmMessage" BO_ 2654486701 1;
BA_ "NmAsrMessage" BO_ 2654486701 1;
BA_ "VFrameFormat" BO_ 2654486701 15;
BA_ "CANFD_BRS" BO_ 2654486701 1;
BA_ "Type" BO_ 2654486689 8;
BA_ "NmMessage" BO_ 2654486689 1;
BA_ "NmAsrMessage" BO_ 2654486689 1;
BA_ "VFrameFormat" BO_ 2654486689 15;
BA_ "CANFD_BRS" BO_ 2654486689 1;
BA_ "GenSigTimeoutTime_ADCAM" SG_ 727 PA_SideSensor_RearRight_Dist 0;
BA_ "GenSigTimeoutTime_CVADAS" SG_ 727 PA_SideSensor_RearRight_Dist 0;
BA_ "GenSigTimeoutTime_ADCAM" SG_ 727 PA_SideSensor_RearRight_Conf 0;
BA_ "GenSigTimeoutTime_CVADAS" SG_ 727 PA_SideSensor_RearRight_Conf 0;
BA_ "GenSigTimeoutTime_ADCAM" SG_ 727 PA_SideSensor_RearLeft_Dist 0;
BA_ "GenSigTimeoutTime_CVADAS" SG_ 727 PA_SideSensor_RearLeft_Dist 0;
BA_ "GenSigTimeoutTime_ADCAM" SG_ 727 PA_SideSensor_RearLeft_Conf 0;
BA_ "GenSigTimeoutTime_CVADAS" SG_ 727 PA_SideSensor_RearLeft_Conf 0;
BA_ "GenSigTimeoutTime_ADCAM" SG_ 727 PA_SideSensor_FrontRight_Dist 0;
BA_ "GenSigTimeoutTime_CVADAS" SG_ 727 PA_SideSensor_FrontRight_Dist 0;
BA_ "GenSigTimeoutTime_BSM" SG_ 727 PA_SideSensor_FrontRight_Conf 0;
BA_ "GenSigTimeoutTime_BSM2" SG_ 727 PA_SideSensor_FrontRight_Conf 0;
BA_ "GenSigTimeoutTime_CVPAM" SG_ 727 PA_SideSensor_FrontRight_Conf 0;
BA_ "GenSigTimeoutTime_ECM" SG_ 727 PA_SideSensor_FrontRight_Conf 0;
BA_ "GenSigTimeoutTime_EPS" SG_ 727 PA_SideSensor_FrontRight_Conf 0;
BA_ "GenSigTimeoutTime_ADCAM" SG_ 727 PA_SideSensor_FrontRight_Conf 0;
BA_ "GenSigTimeoutTime_CVADAS" SG_ 727 PA_SideSensor_FrontRight_Conf 0;
BA_ "GenSigTimeoutTime_ADCAM" SG_ 727 PA_SideSensor_FrontLeft_Dist 0;
BA_ "GenSigTimeoutTime_CVADAS" SG_ 727 PA_SideSensor_FrontLeft_Dist 0;
BA_ "GenSigStartValue" SG_ 727 PA_SideSensor_FrontLeft_Dist 1023;
BA_ "GenSigTimeoutTime_BSM" SG_ 727 PA_SideSensor_FrontLeft_Dist 0;
BA_ "GenSigTimeoutTime_BSM2" SG_ 727 PA_SideSensor_FrontLeft_Dist 0;
BA_ "GenSigTimeoutTime_CVPAM" SG_ 727 PA_SideSensor_FrontLeft_Dist 0;
BA_ "GenSigTimeoutTime_ECM" SG_ 727 PA_SideSensor_FrontLeft_Dist 0;
BA_ "GenSigTimeoutTime_EPS" SG_ 727 PA_SideSensor_FrontLeft_Dist 0;
BA_ "GenSigTimeoutTime_EVCU2" SG_ 727 PA_SideSensor_FrontLeft_Dist 0;
BA_ "GenSigTimeoutTime_ORC" SG_ 727 PA_SideSensor_FrontLeft_Dist 0;
BA_ "GenSigTimeoutTime_ADCAM" SG_ 727 PA_SideSensor_FrontLeft_Conf 0;
BA_ "GenSigTimeoutTime_CVADAS" SG_ 727 PA_SideSensor_FrontLeft_Conf 0;
BA_ "GenSigTimeoutTime_BSM" SG_ 727 PA_SideSensor_FrontLeft_Conf 0;
BA_ "GenSigTimeoutTime_BSM2" SG_ 727 PA_SideSensor_FrontLeft_Conf 0;
BA_ "GenSigTimeoutTime_CVPAM" SG_ 727 PA_SideSensor_FrontLeft_Conf 0;
BA_ "GenSigTimeoutTime_ECM" SG_ 727 PA_SideSensor_FrontLeft_Conf 0;
BA_ "GenSigTimeoutTime_EPS" SG_ 727 PA_SideSensor_FrontLeft_Conf 0;
BA_ "GenSigTimeoutTime_EVCU2" SG_ 727 PA_SideSensor_FrontLeft_Conf 0;
BA_ "GenSigTimeoutTime_ORC" SG_ 727 PA_SideSensor_FrontLeft_Conf 0;
BA_ "GenSigTimeoutTime_ADCAM" SG_ 727 PA_Right_Sensor_Det_Health 0;
BA_ "GenSigTimeoutTime_CVADAS" SG_ 727 PA_Right_Sensor_Det_Health 0;
BA_ "GenSigTimeoutTime_BSM" SG_ 727 PA_Right_Sensor_Det_Health 0;
BA_ "GenSigTimeoutTime_BSM2" SG_ 727 PA_Right_Sensor_Det_Health 0;
BA_ "GenSigTimeoutTime_CVPAM" SG_ 727 PA_Right_Sensor_Det_Health 0;
BA_ "GenSigTimeoutTime_ECM" SG_ 727 PA_Right_Sensor_Det_Health 0;
BA_ "GenSigTimeoutTime_EPS" SG_ 727 PA_Right_Sensor_Det_Health 0;
BA_ "GenSigTimeoutTime_EVCU2" SG_ 727 PA_Right_Sensor_Det_Health 0;
BA_ "GenSigTimeoutTime_ORC" SG_ 727 PA_Right_Sensor_Det_Health 0;
BA_ "GenSigTimeoutTime_ADCAM" SG_ 727 PA_Line_RM_Style 0;
BA_ "GenSigTimeoutTime_CVADAS" SG_ 727 PA_Line_RM_Style 0;
BA_ "GenSigTimeoutTime_BSM" SG_ 727 PA_Line_RM_Style 0;
BA_ "GenSigTimeoutTime_BSM2" SG_ 727 PA_Line_RM_Style 0;
BA_ "GenSigTimeoutTime_CVPAM" SG_ 727 PA_Line_RM_Style 0;
BA_ "GenSigTimeoutTime_ECM" SG_ 727 PA_Line_RM_Style 0;
BA_ "GenSigTimeoutTime_EPS" SG_ 727 PA_Line_RM_Style 0;
BA_ "GenSigTimeoutTime_EVCU2" SG_ 727 PA_Line_RM_Style 0;
BA_ "GenSigTimeoutTime_ORC" SG_ 727 PA_Line_RM_Style 0;
BA_ "GenSigTimeoutTime_ADCAM" SG_ 727 PA_Line_RM_Heading 0;
BA_ "GenSigTimeoutTime_CVADAS" SG_ 727 PA_Line_RM_Heading 0;
BA_ "GenSigTimeoutTime_BSM" SG_ 727 PA_Line_RM_Heading 0;
BA_ "GenSigTimeoutTime_BSM2" SG_ 727 PA_Line_RM_Heading 0;
BA_ "GenSigTimeoutTime_CVPAM" SG_ 727 PA_Line_RM_Heading 0;
BA_ "GenSigTimeoutTime_ECM" SG_ 727 PA_Line_RM_Heading 0;
BA_ "GenSigTimeoutTime_EPS" SG_ 727 PA_Line_RM_Heading 0;
BA_ "GenSigTimeoutTime_EVCU2" SG_ 727 PA_Line_RM_Heading 0;
BA_ "GenSigTimeoutTime_ORC" SG_ 727 PA_Line_RM_Heading 0;
BA_ "GenSigTimeoutTime_ADCAM" SG_ 727 PA_Line_RM_Color 0;
BA_ "GenSigTimeoutTime_CVADAS" SG_ 727 PA_Line_RM_Color 0;
BA_ "GenSigTimeoutTime_BSM" SG_ 727 PA_Line_RM_Color 0;
BA_ "GenSigTimeoutTime_BSM2" SG_ 727 PA_Line_RM_Color 0;
BA_ "GenSigTimeoutTime_CVPAM" SG_ 727 PA_Line_RM_Color 0;
BA_ "GenSigTimeoutTime_ECM" SG_ 727 PA_Line_RM_Color 0;
BA_ "GenSigTimeoutTime_EPS" SG_ 727 PA_Line_RM_Color 0;
BA_ "GenSigTimeoutTime_EVCU2" SG_ 727 PA_Line_RM_Color 0;
BA_ "GenSigTimeoutTime_ORC" SG_ 727 PA_Line_RM_Color 0;
BA_ "GenSigTimeoutTime_ADCAM" SG_ 727 PA_Line_LM_Style 0;
BA_ "GenSigTimeoutTime_CVADAS" SG_ 727 PA_Line_LM_Style 0;
BA_ "GenSigTimeoutTime_BSM" SG_ 727 PA_Line_LM_Style 0;
BA_ "GenSigTimeoutTime_BSM2" SG_ 727 PA_Line_LM_Style 0;
BA_ "GenSigTimeoutTime_CVPAM" SG_ 727 PA_Line_LM_Style 0;
BA_ "GenSigTimeoutTime_ECM" SG_ 727 PA_Line_LM_Style 0;
BA_ "GenSigTimeoutTime_EPS" SG_ 727 PA_Line_LM_Style 0;
BA_ "GenSigTimeoutTime_EVCU2" SG_ 727 PA_Line_LM_Style 0;
BA_ "GenSigTimeoutTime_ORC" SG_ 727 PA_Line_LM_Style 0;
BA_ "GenSigTimeoutTime_ADCAM" SG_ 727 PA_Line_LM_Heading 0;
BA_ "GenSigTimeoutTime_CVADAS" SG_ 727 PA_Line_LM_Heading 0;
BA_ "GenSigTimeoutTime_BSM" SG_ 727 PA_Line_LM_Heading 0;
BA_ "GenSigTimeoutTime_BSM2" SG_ 727 PA_Line_LM_Heading 0;
BA_ "GenSigTimeoutTime_CVPAM" SG_ 727 PA_Line_LM_Heading 0;
BA_ "GenSigTimeoutTime_ECM" SG_ 727 PA_Line_LM_Heading 0;
BA_ "GenSigTimeoutTime_EPS" SG_ 727 PA_Line_LM_Heading 0;
BA_ "GenSigTimeoutTime_EVCU2" SG_ 727 PA_Line_LM_Heading 0;
BA_ "GenSigTimeoutTime_ORC" SG_ 727 PA_Line_LM_Heading 0;
BA_ "GenSigTimeoutTime_ADCAM" SG_ 727 PA_Line_LM_Color 0;
BA_ "GenSigTimeoutTime_CVADAS" SG_ 727 PA_Line_LM_Color 0;
BA_ "GenSigTimeoutTime_BSM" SG_ 727 PA_Line_LM_Color 0;
BA_ "GenSigTimeoutTime_BSM2" SG_ 727 PA_Line_LM_Color 0;
BA_ "GenSigTimeoutTime_CVPAM" SG_ 727 PA_Line_LM_Color 0;
BA_ "GenSigTimeoutTime_ECM" SG_ 727 PA_Line_LM_Color 0;
BA_ "GenSigTimeoutTime_EPS" SG_ 727 PA_Line_LM_Color 0;
BA_ "GenSigTimeoutTime_EVCU2" SG_ 727 PA_Line_LM_Color 0;
BA_ "GenSigTimeoutTime_ORC" SG_ 727 PA_Line_LM_Color 0;
BA_ "GenSigTimeoutTime_ADCAM" SG_ 727 PA_Left_Sensor_Det_Health 0;
BA_ "GenSigTimeoutTime_CVADAS" SG_ 727 PA_Left_Sensor_Det_Health 0;
BA_ "GenSigTimeoutTime_BSM" SG_ 727 PA_Left_Sensor_Det_Health 0;
BA_ "GenSigTimeoutTime_BSM2" SG_ 727 PA_Left_Sensor_Det_Health 0;
BA_ "GenSigTimeoutTime_CVPAM" SG_ 727 PA_Left_Sensor_Det_Health 0;
BA_ "GenSigTimeoutTime_ECM" SG_ 727 PA_Left_Sensor_Det_Health 0;
BA_ "GenSigTimeoutTime_EPS" SG_ 727 PA_Left_Sensor_Det_Health 0;
BA_ "GenSigTimeoutTime_EVCU2" SG_ 727 PA_Left_Sensor_Det_Health 0;
BA_ "GenSigTimeoutTime_ORC" SG_ 727 PA_Left_Sensor_Det_Health 0;
BA_ "GenSigTimeoutTime_ADCAM" SG_ 727 PA_Lane_Dection_Health 0;
BA_ "GenSigTimeoutTime_CVADAS" SG_ 727 PA_Lane_Dection_Health 0;
BA_ "GenSigTimeoutTime_BSM" SG_ 727 PA_Lane_Dection_Health 0;
BA_ "GenSigTimeoutTime_BSM2" SG_ 727 PA_Lane_Dection_Health 0;
BA_ "GenSigTimeoutTime_CVPAM" SG_ 727 PA_Lane_Dection_Health 0;
BA_ "GenSigTimeoutTime_ECM" SG_ 727 PA_Lane_Dection_Health 0;
BA_ "GenSigTimeoutTime_EPS" SG_ 727 PA_Lane_Dection_Health 0;
BA_ "GenSigTimeoutTime_EVCU2" SG_ 727 PA_Lane_Dection_Health 0;
BA_ "GenSigTimeoutTime_ORC" SG_ 727 PA_Lane_Dection_Health 0;
BA_ "GenSigTimeoutTime_ADCAM" SG_ 727 MessageCounter_CVPAM_FD_Data2 0;
BA_ "GenSigTimeoutTime_CVADAS" SG_ 727 MessageCounter_CVPAM_FD_Data2 0;
BA_ "GenSigTimeoutTime_BSM" SG_ 727 MessageCounter_CVPAM_FD_Data2 0;
BA_ "GenSigTimeoutTime_BSM2" SG_ 727 MessageCounter_CVPAM_FD_Data2 0;
BA_ "GenSigTimeoutTime_CVPAM" SG_ 727 MessageCounter_CVPAM_FD_Data2 0;
BA_ "GenSigTimeoutTime_ECM" SG_ 727 MessageCounter_CVPAM_FD_Data2 0;
BA_ "GenSigTimeoutTime_EPS" SG_ 727 MessageCounter_CVPAM_FD_Data2 0;
BA_ "GenSigTimeoutTime_EVCU2" SG_ 727 MessageCounter_CVPAM_FD_Data2 0;
BA_ "GenSigTimeoutTime_ORC" SG_ 727 MessageCounter_CVPAM_FD_Data2 0;
BA_ "GenSigTimeoutTime_ADCAM" SG_ 727 MAC_CVPAM_FD_Data2 0;
BA_ "GenSigTimeoutTime_CVADAS" SG_ 727 MAC_CVPAM_FD_Data2 0;
BA_ "GenSigTimeoutTime_BSM" SG_ 727 MAC_CVPAM_FD_Data2 0;
BA_ "GenSigTimeoutTime_BSM2" SG_ 727 MAC_CVPAM_FD_Data2 0;
BA_ "GenSigTimeoutTime_CVPAM" SG_ 727 MAC_CVPAM_FD_Data2 0;
BA_ "GenSigTimeoutTime_ECM" SG_ 727 MAC_CVPAM_FD_Data2 0;
BA_ "GenSigTimeoutTime_EPS" SG_ 727 MAC_CVPAM_FD_Data2 0;
BA_ "GenSigTimeoutTime_EVCU2" SG_ 727 MAC_CVPAM_FD_Data2 0;
BA_ "GenSigTimeoutTime_ORC" SG_ 727 MAC_CVPAM_FD_Data2 0;
BA_ "GenSigTimeoutTime_ADCAM" SG_ 727 CRC_CVPAM_FD_Data2 0;
BA_ "GenSigTimeoutTime_CVADAS" SG_ 727 CRC_CVPAM_FD_Data2 0;
BA_ "GenSigTimeoutTime_BSM" SG_ 727 CRC_CVPAM_FD_Data2 0;
BA_ "GenSigTimeoutTime_BSM2" SG_ 727 CRC_CVPAM_FD_Data2 0;
BA_ "GenSigTimeoutTime_CVPAM" SG_ 727 CRC_CVPAM_FD_Data2 0;
BA_ "GenSigTimeoutTime_ECM" SG_ 727 CRC_CVPAM_FD_Data2 0;
BA_ "GenSigTimeoutTime_EPS" SG_ 727 CRC_CVPAM_FD_Data2 0;
BA_ "GenSigTimeoutTime_EVCU2" SG_ 727 CRC_CVPAM_FD_Data2 0;
BA_ "GenSigTimeoutTime_ORC" SG_ 727 CRC_CVPAM_FD_Data2 0;
BA_ "GenSigTimeoutTime_BSM" SG_ 726 PA_Obj6_Type 0;
BA_ "GenSigTimeoutTime_BSM2" SG_ 726 PA_Obj6_Type 0;
BA_ "GenSigTimeoutTime_CVPAM" SG_ 726 PA_Obj6_Type 0;
BA_ "GenSigTimeoutTime_ECM" SG_ 726 PA_Obj6_Type 0;
BA_ "GenSigTimeoutTime_EPS" SG_ 726 PA_Obj6_Type 0;
BA_ "GenSigTimeoutTime_EVCU2" SG_ 726 PA_Obj6_Type 0;
BA_ "GenSigTimeoutTime_ORC" SG_ 726 PA_Obj6_Type 0;
BA_ "GenSigTimeoutTime_ADCAM" SG_ 727 Cntr_CVPAM_FD_Data2 0;
BA_ "GenSigTimeoutTime_CVADAS" SG_ 727 Cntr_CVPAM_FD_Data2 0;
BA_ "GenSigTimeoutTime_BSM" SG_ 727 Cntr_CVPAM_FD_Data2 0;
BA_ "GenSigTimeoutTime_BSM2" SG_ 727 Cntr_CVPAM_FD_Data2 0;
BA_ "GenSigTimeoutTime_CVPAM" SG_ 727 Cntr_CVPAM_FD_Data2 0;
BA_ "GenSigTimeoutTime_ECM" SG_ 727 Cntr_CVPAM_FD_Data2 0;
BA_ "GenSigTimeoutTime_EPS" SG_ 727 Cntr_CVPAM_FD_Data2 0;
BA_ "GenSigTimeoutTime_EVCU2" SG_ 727 Cntr_CVPAM_FD_Data2 0;
BA_ "GenSigTimeoutTime_ORC" SG_ 727 Cntr_CVPAM_FD_Data2 0;
BA_ "GenSigTimeoutTime_ADCAM" SG_ 727 Reserved_for_Functional_Safety_ 0;
BA_ "GenSigTimeoutTime_CVADAS" SG_ 727 Reserved_for_Functional_Safety_ 0;
BA_ "SystemSignalLongSymbol" SG_ 727 Reserved_for_Functional_Safety_ "Reserved_for_Functional_Safety_CRC";
BA_ "GenSigTimeoutTime_BSM" SG_ 727 Reserved_for_Functional_Safety_ 0;
BA_ "GenSigTimeoutTime_BSM2" SG_ 727 Reserved_for_Functional_Safety_ 0;
BA_ "GenSigTimeoutTime_CVPAM" SG_ 727 Reserved_for_Functional_Safety_ 0;
BA_ "GenSigTimeoutTime_ECM" SG_ 727 Reserved_for_Functional_Safety_ 0;
BA_ "GenSigTimeoutTime_EPS" SG_ 727 Reserved_for_Functional_Safety_ 0;
BA_ "GenSigTimeoutTime_EVCU2" SG_ 727 Reserved_for_Functional_Safety_ 0;
BA_ "GenSigTimeoutTime_ORC" SG_ 727 Reserved_for_Functional_Safety_ 0;
BA_ "GenSigTimeoutTime_ADCAM" SG_ 727 PA_Line_RM_Heading_Conf 0;
BA_ "GenSigTimeoutTime_CVADAS" SG_ 727 PA_Line_RM_Heading_Conf 0;
BA_ "GenSigTimeoutTime_BSM" SG_ 727 PA_Line_RM_Heading_Conf 0;
BA_ "GenSigTimeoutTime_BSM2" SG_ 727 PA_Line_RM_Heading_Conf 0;
BA_ "GenSigTimeoutTime_CVPAM" SG_ 727 PA_Line_RM_Heading_Conf 0;
BA_ "GenSigTimeoutTime_ECM" SG_ 727 PA_Line_RM_Heading_Conf 0;
BA_ "GenSigTimeoutTime_EPS" SG_ 727 PA_Line_RM_Heading_Conf 0;
BA_ "GenSigTimeoutTime_EVCU2" SG_ 727 PA_Line_RM_Heading_Conf 0;
BA_ "GenSigTimeoutTime_ORC" SG_ 727 PA_Line_RM_Heading_Conf 0;
BA_ "GenSigTimeoutTime_ADCAM" SG_ 727 PA_Line_RM_Distance_Conf 0;
BA_ "GenSigTimeoutTime_CVADAS" SG_ 727 PA_Line_RM_Distance_Conf 0;
BA_ "GenSigTimeoutTime_BSM" SG_ 727 PA_Line_RM_Distance_Conf 0;
BA_ "GenSigTimeoutTime_BSM2" SG_ 727 PA_Line_RM_Distance_Conf 0;
BA_ "GenSigTimeoutTime_CVPAM" SG_ 727 PA_Line_RM_Distance_Conf 0;
BA_ "GenSigTimeoutTime_ECM" SG_ 727 PA_Line_RM_Distance_Conf 0;
BA_ "GenSigTimeoutTime_EPS" SG_ 727 PA_Line_RM_Distance_Conf 0;
BA_ "GenSigTimeoutTime_EVCU2" SG_ 727 PA_Line_RM_Distance_Conf 0;
BA_ "GenSigTimeoutTime_ORC" SG_ 727 PA_Line_RM_Distance_Conf 0;
BA_ "GenSigTimeoutTime_BSM" SG_ 727 PA_Line_RM_Distance 0;
BA_ "GenSigTimeoutTime_BSM2" SG_ 727 PA_Line_RM_Distance 0;
BA_ "GenSigTimeoutTime_CVPAM" SG_ 727 PA_Line_RM_Distance 0;
BA_ "GenSigTimeoutTime_ECM" SG_ 727 PA_Line_RM_Distance 0;
BA_ "GenSigTimeoutTime_EPS" SG_ 727 PA_Line_RM_Distance 0;
BA_ "GenSigTimeoutTime_EVCU2" SG_ 727 PA_Line_RM_Distance 0;
BA_ "GenSigTimeoutTime_ORC" SG_ 727 PA_Line_RM_Distance 0;
BA_ "GenSigTimeoutTime_ADCAM" SG_ 727 PA_Line_RM_Distance 0;
BA_ "GenSigTimeoutTime_CVADAS" SG_ 727 PA_Line_RM_Distance 0;
BA_ "GenSigTimeoutTime_BSM" SG_ 727 PA_Line_LM_Heading_Conf 0;
BA_ "GenSigTimeoutTime_BSM2" SG_ 727 PA_Line_LM_Heading_Conf 0;
BA_ "GenSigTimeoutTime_CVPAM" SG_ 727 PA_Line_LM_Heading_Conf 0;
BA_ "GenSigTimeoutTime_ECM" SG_ 727 PA_Line_LM_Heading_Conf 0;
BA_ "GenSigTimeoutTime_EPS" SG_ 727 PA_Line_LM_Heading_Conf 0;
BA_ "GenSigTimeoutTime_EVCU2" SG_ 727 PA_Line_LM_Heading_Conf 0;
BA_ "GenSigTimeoutTime_ORC" SG_ 727 PA_Line_LM_Heading_Conf 0;
BA_ "GenSigTimeoutTime_ADCAM" SG_ 727 PA_Line_LM_Heading_Conf 0;
BA_ "GenSigTimeoutTime_CVADAS" SG_ 727 PA_Line_LM_Heading_Conf 0;
BA_ "GenSigTimeoutTime_BSM" SG_ 727 PA_Line_LM_Distance_Conf 0;
BA_ "GenSigTimeoutTime_BSM2" SG_ 727 PA_Line_LM_Distance_Conf 0;
BA_ "GenSigTimeoutTime_CVPAM" SG_ 727 PA_Line_LM_Distance_Conf 0;
BA_ "GenSigTimeoutTime_ECM" SG_ 727 PA_Line_LM_Distance_Conf 0;
BA_ "GenSigTimeoutTime_EPS" SG_ 727 PA_Line_LM_Distance_Conf 0;
BA_ "GenSigTimeoutTime_EVCU2" SG_ 727 PA_Line_LM_Distance_Conf 0;
BA_ "GenSigTimeoutTime_ORC" SG_ 727 PA_Line_LM_Distance_Conf 0;
BA_ "GenSigTimeoutTime_ADCAM" SG_ 727 PA_Line_LM_Distance_Conf 0;
BA_ "GenSigTimeoutTime_CVADAS" SG_ 727 PA_Line_LM_Distance_Conf 0;
BA_ "GenSigTimeoutTime_ORC" SG_ 727 PA_Line_LM_Distance 0;
BA_ "GenSigTimeoutTime_ADCAM" SG_ 727 PA_Line_LM_Distance 0;
BA_ "GenSigTimeoutTime_CVADAS" SG_ 727 PA_Line_LM_Distance 0;
BA_ "GenSigTimeoutTime_BSM" SG_ 727 PA_Line_LM_Distance 0;
BA_ "GenSigTimeoutTime_BSM2" SG_ 727 PA_Line_LM_Distance 0;
BA_ "GenSigTimeoutTime_CVPAM" SG_ 727 PA_Line_LM_Distance 0;
BA_ "GenSigTimeoutTime_ECM" SG_ 727 PA_Line_LM_Distance 0;
BA_ "GenSigTimeoutTime_EPS" SG_ 727 PA_Line_LM_Distance 0;
BA_ "GenSigTimeoutTime_EVCU2" SG_ 727 PA_Line_LM_Distance 0;
BA_ "GenSigTimeoutTime_MPAD" SG_ 2654486554 CBV_bit7_1E38401A 0;
BA_ "GenSigTimeoutTime_ADCAM" SG_ 2654486554 CBV_bit7_1E38401A 0;
BA_ "GenSigTimeoutTime_CVADAS" SG_ 2654486554 CBV_bit7_1E38401A 0;
BA_ "GenSigTimeoutTime_VDCM" SG_ 2654486554 CBV_bit7_1E38401A 0;
BA_ "GenSigTimeoutTime_BSM" SG_ 2654486554 CBV_bit7_1E38401A 0;
BA_ "GenSigTimeoutTime_BSM2" SG_ 2654486554 CBV_bit7_1E38401A 0;
BA_ "GenSigTimeoutTime_CADM" SG_ 2654486554 CBV_bit7_1E38401A 0;
BA_ "GenSigTimeoutTime_CVPAM" SG_ 2654486554 CBV_bit7_1E38401A 0;
BA_ "GenSigTimeoutTime_ECM" SG_ 2654486554 CBV_bit7_1E38401A 0;
BA_ "GenSigTimeoutTime_EPS" SG_ 2654486554 CBV_bit7_1E38401A 0;
BA_ "GenSigTimeoutTime_EVCU2" SG_ 2654486554 CBV_bit7_1E38401A 0;
BA_ "GenSigTimeoutTime_ORC" SG_ 2654486554 CBV_bit7_1E38401A 0;
BA_ "GenSigTimeoutTime_MPAD" SG_ 2654486554 SourceNodeIdentifier_1E38401A 0;
BA_ "GenSigTimeoutTime_ADCAM" SG_ 2654486554 SourceNodeIdentifier_1E38401A 0;
BA_ "GenSigTimeoutTime_CVADAS" SG_ 2654486554 SourceNodeIdentifier_1E38401A 0;
BA_ "GenSigTimeoutTime_VDCM" SG_ 2654486554 SourceNodeIdentifier_1E38401A 0;
BA_ "GenSigTimeoutTime_BSM" SG_ 2654486554 SourceNodeIdentifier_1E38401A 0;
BA_ "GenSigTimeoutTime_BSM2" SG_ 2654486554 SourceNodeIdentifier_1E38401A 0;
BA_ "GenSigTimeoutTime_CADM" SG_ 2654486554 SourceNodeIdentifier_1E38401A 0;
BA_ "GenSigTimeoutTime_CVPAM" SG_ 2654486554 SourceNodeIdentifier_1E38401A 0;
BA_ "GenSigTimeoutTime_ECM" SG_ 2654486554 SourceNodeIdentifier_1E38401A 0;
BA_ "GenSigTimeoutTime_EPS" SG_ 2654486554 SourceNodeIdentifier_1E38401A 0;
BA_ "GenSigTimeoutTime_EVCU2" SG_ 2654486554 SourceNodeIdentifier_1E38401A 0;
BA_ "GenSigTimeoutTime_ORC" SG_ 2654486554 SourceNodeIdentifier_1E38401A 0;
BA_ "GenSigTimeoutTime_BSM" SG_ 2654486554 CBV_bit0_RepeatMessageRequestBit_1E38401A 0;
BA_ "GenSigTimeoutTime_BSM2" SG_ 2654486554 CBV_bit0_RepeatMessageRequestBit_1E38401A 0;
BA_ "GenSigTimeoutTime_CADM" SG_ 2654486554 CBV_bit0_RepeatMessageRequestBit_1E38401A 0;
BA_ "GenSigTimeoutTime_CVPAM" SG_ 2654486554 CBV_bit0_RepeatMessageRequestBit_1E38401A 0;
BA_ "GenSigTimeoutTime_ECM" SG_ 2654486554 CBV_bit0_RepeatMessageRequestBit_1E38401A 0;
BA_ "GenSigTimeoutTime_EPS" SG_ 2654486554 CBV_bit0_RepeatMessageRequestBit_1E38401A 0;
BA_ "GenSigTimeoutTime_EVCU2" SG_ 2654486554 CBV_bit0_RepeatMessageRequestBit_1E38401A 0;
BA_ "GenSigTimeoutTime_ORC" SG_ 2654486554 CBV_bit0_RepeatMessageRequestBit_1E38401A 0;
BA_ "GenSigTimeoutTime_BSM" SG_ 2654486554 CBV_bit1_1E38401A 0;
BA_ "GenSigTimeoutTime_BSM2" SG_ 2654486554 CBV_bit1_1E38401A 0;
BA_ "GenSigTimeoutTime_CADM" SG_ 2654486554 CBV_bit1_1E38401A 0;
BA_ "GenSigTimeoutTime_CVPAM" SG_ 2654486554 CBV_bit1_1E38401A 0;
BA_ "GenSigTimeoutTime_ECM" SG_ 2654486554 CBV_bit1_1E38401A 0;
BA_ "GenSigTimeoutTime_EPS" SG_ 2654486554 CBV_bit1_1E38401A 0;
BA_ "GenSigTimeoutTime_EVCU2" SG_ 2654486554 CBV_bit1_1E38401A 0;
BA_ "GenSigTimeoutTime_ORC" SG_ 2654486554 CBV_bit1_1E38401A 0;
BA_ "GenSigTimeoutTime_BSM" SG_ 2654486554 CBV_bit2_1E38401A 0;
BA_ "GenSigTimeoutTime_BSM2" SG_ 2654486554 CBV_bit2_1E38401A 0;
BA_ "GenSigTimeoutTime_CADM" SG_ 2654486554 CBV_bit2_1E38401A 0;
BA_ "GenSigTimeoutTime_CVPAM" SG_ 2654486554 CBV_bit2_1E38401A 0;
BA_ "GenSigTimeoutTime_ECM" SG_ 2654486554 CBV_bit2_1E38401A 0;
BA_ "GenSigTimeoutTime_EPS" SG_ 2654486554 CBV_bit2_1E38401A 0;
BA_ "GenSigTimeoutTime_EVCU2" SG_ 2654486554 CBV_bit2_1E38401A 0;
BA_ "GenSigTimeoutTime_ORC" SG_ 2654486554 CBV_bit2_1E38401A 0;
BA_ "GenSigTimeoutTime_BSM" SG_ 2654486554 CBV_bit3_NMCoordinatorBit_1E38401A 0;
BA_ "GenSigTimeoutTime_BSM2" SG_ 2654486554 CBV_bit3_NMCoordinatorBit_1E38401A 0;
BA_ "GenSigTimeoutTime_CADM" SG_ 2654486554 CBV_bit3_NMCoordinatorBit_1E38401A 0;
BA_ "GenSigTimeoutTime_CVPAM" SG_ 2654486554 CBV_bit3_NMCoordinatorBit_1E38401A 0;
BA_ "GenSigTimeoutTime_ECM" SG_ 2654486554 CBV_bit3_NMCoordinatorBit_1E38401A 0;
BA_ "GenSigTimeoutTime_EPS" SG_ 2654486554 CBV_bit3_NMCoordinatorBit_1E38401A 0;
BA_ "GenSigTimeoutTime_EVCU2" SG_ 2654486554 CBV_bit3_NMCoordinatorBit_1E38401A 0;
BA_ "GenSigTimeoutTime_ORC" SG_ 2654486554 CBV_bit3_NMCoordinatorBit_1E38401A 0;
BA_ "GenSigTimeoutTime_BSM" SG_ 2654486554 CBV_bit4_ActiveWakeupBit_1E38401A 0;
BA_ "GenSigTimeoutTime_BSM2" SG_ 2654486554 CBV_bit4_ActiveWakeupBit_1E38401A 0;
BA_ "GenSigTimeoutTime_CADM" SG_ 2654486554 CBV_bit4_ActiveWakeupBit_1E38401A 0;
BA_ "GenSigTimeoutTime_CVPAM" SG_ 2654486554 CBV_bit4_ActiveWakeupBit_1E38401A 0;
BA_ "GenSigTimeoutTime_ECM" SG_ 2654486554 CBV_bit4_ActiveWakeupBit_1E38401A 0;
BA_ "GenSigTimeoutTime_EPS" SG_ 2654486554 CBV_bit4_ActiveWakeupBit_1E38401A 0;
BA_ "GenSigTimeoutTime_EVCU2" SG_ 2654486554 CBV_bit4_ActiveWakeupBit_1E38401A 0;
BA_ "GenSigTimeoutTime_ORC" SG_ 2654486554 CBV_bit4_ActiveWakeupBit_1E38401A 0;
BA_ "GenSigTimeoutTime_MPAD" SG_ 2654486554 CBV_bit5_1E38401A 0;
BA_ "GenSigTimeoutTime_ADCAM" SG_ 2654486554 CBV_bit5_1E38401A 0;
BA_ "GenSigTimeoutTime_CVADAS" SG_ 2654486554 CBV_bit5_1E38401A 0;
BA_ "GenSigTimeoutTime_VDCM" SG_ 2654486554 CBV_bit5_1E38401A 0;
BA_ "GenSigTimeoutTime_BSM" SG_ 2654486554 CBV_bit5_1E38401A 0;
BA_ "GenSigTimeoutTime_BSM2" SG_ 2654486554 CBV_bit5_1E38401A 0;
BA_ "GenSigTimeoutTime_CADM" SG_ 2654486554 CBV_bit5_1E38401A 0;
BA_ "GenSigTimeoutTime_CVPAM" SG_ 2654486554 CBV_bit5_1E38401A 0;
BA_ "GenSigTimeoutTime_ECM" SG_ 2654486554 CBV_bit5_1E38401A 0;
BA_ "GenSigTimeoutTime_EPS" SG_ 2654486554 CBV_bit5_1E38401A 0;
BA_ "GenSigTimeoutTime_EVCU2" SG_ 2654486554 CBV_bit5_1E38401A 0;
BA_ "GenSigTimeoutTime_ORC" SG_ 2654486554 CBV_bit5_1E38401A 0;
BA_ "GenSigTimeoutTime_MPAD" SG_ 2654486554 CBV_bit6_PartialNtwInfBit_1E38401A 0;
BA_ "GenSigTimeoutTime_ADCAM" SG_ 2654486554 CBV_bit6_PartialNtwInfBit_1E38401A 0;
BA_ "GenSigTimeoutTime_CVADAS" SG_ 2654486554 CBV_bit6_PartialNtwInfBit_1E38401A 0;
BA_ "GenSigTimeoutTime_VDCM" SG_ 2654486554 CBV_bit6_PartialNtwInfBit_1E38401A 0;
BA_ "GenSigTimeoutTime_BSM" SG_ 2654486554 CBV_bit6_PartialNtwInfBit_1E38401A 0;
BA_ "GenSigTimeoutTime_BSM2" SG_ 2654486554 CBV_bit6_PartialNtwInfBit_1E38401A 0;
BA_ "GenSigTimeoutTime_CADM" SG_ 2654486554 CBV_bit6_PartialNtwInfBit_1E38401A 0;
BA_ "GenSigTimeoutTime_CVPAM" SG_ 2654486554 CBV_bit6_PartialNtwInfBit_1E38401A 0;
BA_ "GenSigTimeoutTime_ECM" SG_ 2654486554 CBV_bit6_PartialNtwInfBit_1E38401A 0;
BA_ "GenSigTimeoutTime_EPS" SG_ 2654486554 CBV_bit6_PartialNtwInfBit_1E38401A 0;
BA_ "GenSigTimeoutTime_EVCU2" SG_ 2654486554 CBV_bit6_PartialNtwInfBit_1E38401A 0;
BA_ "GenSigTimeoutTime_ORC" SG_ 2654486554 CBV_bit6_PartialNtwInfBit_1E38401A 0;
BA_ "GenSigTimeoutTime_CVADAS" SG_ 280 ESASystemSts 0;
BA_ "GenSigTimeoutTime_BSM2" SG_ 280 ESASystemSts 0;
BA_ "GenSigTimeoutTime_CADM" SG_ 280 ESASystemSts 0;
BA_ "GenSigTimeoutTime_ECM" SG_ 280 ESASystemSts 0;
BA_ "GenSigTimeoutTime_EVCU2" SG_ 280 ESASystemSts 0;
BA_ "GenSigTimeoutTime_ORC" SG_ 280 ESASystemSts 0;
BA_ "GenSigTimeoutTime_MPAD" SG_ 280 TorqueOverlaySteeringReq 0;
BA_ "GenSigTimeoutTime_ADCAM" SG_ 280 TorqueOverlaySteeringReq 0;
BA_ "GenSigTimeoutTime_CVADAS" SG_ 280 TorqueOverlaySteeringReq 0;
BA_ "GenSigTimeoutTime_VDCM" SG_ 280 TorqueOverlaySteeringReq 0;
BA_ "GenSigTimeoutTime_CVADAS" SG_ 280 ESA_TorqueOverlaySteeringReq 0;
BA_ "GenSigStartValue" SG_ 280 ESA_TorqueOverlaySteeringReq 1024;
BA_ "GenSigTimeoutTime_BSM" SG_ 280 ESA_TorqueOverlaySteeringReq 0;
BA_ "GenSigTimeoutTime_BSM2" SG_ 280 ESA_TorqueOverlaySteeringReq 0;
BA_ "GenSigTimeoutTime_CADM" SG_ 280 ESA_TorqueOverlaySteeringReq 0;
BA_ "GenSigTimeoutTime_ECM" SG_ 280 ESA_TorqueOverlaySteeringReq 0;
BA_ "GenSigTimeoutTime_EVCU2" SG_ 280 ESA_TorqueOverlaySteeringReq 0;
BA_ "GenSigTimeoutTime_ORC" SG_ 280 ESA_TorqueOverlaySteeringReq 0;
BA_ "GenSigTimeoutTime_CVADAS" SG_ 280 ESA_LAT_CTRL_RequestSts 0;
BA_ "GenSigTimeoutTime_BSM" SG_ 280 ESA_LAT_CTRL_RequestSts 0;
BA_ "GenSigTimeoutTime_BSM2" SG_ 280 ESA_LAT_CTRL_RequestSts 0;
BA_ "GenSigTimeoutTime_CADM" SG_ 280 ESA_LAT_CTRL_RequestSts 0;
BA_ "GenSigTimeoutTime_ECM" SG_ 280 ESA_LAT_CTRL_RequestSts 0;
BA_ "GenSigTimeoutTime_EVCU2" SG_ 280 ESA_LAT_CTRL_RequestSts 0;
BA_ "GenSigTimeoutTime_ORC" SG_ 280 ESA_LAT_CTRL_RequestSts 0;
BA_ "GenSigTimeoutTime_CVADAS" SG_ 280 ESA_FailSts 0;
BA_ "GenSigTimeoutTime_BSM2" SG_ 280 ESA_FailSts 0;
BA_ "GenSigTimeoutTime_CADM" SG_ 280 ESA_FailSts 0;
BA_ "GenSigTimeoutTime_ECM" SG_ 280 ESA_FailSts 0;
BA_ "GenSigTimeoutTime_EVCU2" SG_ 280 ESA_FailSts 0;
BA_ "GenSigTimeoutTime_ORC" SG_ 280 ESA_FailSts 0;
BA_ "GenSigTimeoutTime_CVADAS" SG_ 280 ESA_LaneClear_Status 0;
BA_ "GenSigSendType" SG_ 280 ESA_LaneClear_Status 3;
BA_ "GenSigTimeoutTime_BSM2" SG_ 280 ESA_LaneClear_Status 0;
BA_ "GenSigTimeoutTime_CADM" SG_ 280 ESA_LaneClear_Status 0;
BA_ "GenSigTimeoutTime_ECM" SG_ 280 ESA_LaneClear_Status 0;
BA_ "GenSigTimeoutTime_EPS" SG_ 280 ESA_LaneClear_Status 0;
BA_ "GenSigTimeoutTime_EVCU2" SG_ 280 ESA_LaneClear_Status 0;
BA_ "GenSigTimeoutTime_ORC" SG_ 280 ESA_LaneClear_Status 0;
BA_ "GenSigTimeoutTime_ADCAM" SG_ 280 ACC_StopStart 0;
BA_ "GenSigTimeoutTime_CVADAS" SG_ 280 ACC_StopStart 0;
BA_ "GenSigTimeoutTime_VDCM" SG_ 280 ACC_StopStart 0;
BA_ "GenSigTimeoutTime_MPAD" SG_ 280 Prefill_Req 0;
BA_ "GenSigTimeoutTime_ADCAM" SG_ 280 Prefill_Req 0;
BA_ "GenSigTimeoutTime_CVADAS" SG_ 280 Prefill_Req 0;
BA_ "GenSigTimeoutTime_VDCM" SG_ 280 Prefill_Req 0;
BA_ "GenSigTimeoutTime_BSM2" SG_ 280 Prefill_Req 0;
BA_ "GenSigTimeoutTime_MPAD" SG_ 280 MRM_STATUS 0;
BA_ "GenSigTimeoutTime_ADCAM" SG_ 280 MRM_STATUS 0;
BA_ "GenSigTimeoutTime_CVADAS" SG_ 280 MRM_STATUS 0;
BA_ "GenSigTimeoutTime_VDCM" SG_ 280 MRM_STATUS 0;
BA_ "GenSigTimeoutTime_EVCU2" SG_ 280 MRM_STATUS 0;
BA_ "GenSigTimeoutTime_MPAD" SG_ 280 PEB_SystemSts 0;
BA_ "GenSigTimeoutTime_ADCAM" SG_ 280 PEB_SystemSts 0;
BA_ "GenSigTimeoutTime_CVADAS" SG_ 280 PEB_SystemSts 0;
BA_ "GenSigTimeoutTime_VDCM" SG_ 280 PEB_SystemSts 0;
BA_ "GenSigTimeoutTime_MPAD" SG_ 280 LANE_CHANGE_SIDE 0;
BA_ "GenSigTimeoutTime_ADCAM" SG_ 280 LANE_CHANGE_SIDE 0;
BA_ "GenSigTimeoutTime_CVADAS" SG_ 280 LANE_CHANGE_SIDE 0;
BA_ "GenSigTimeoutTime_MPAD" SG_ 280 HAS_Status 0;
BA_ "GenSigTimeoutTime_ADCAM" SG_ 280 HAS_Status 0;
BA_ "GenSigTimeoutTime_CVADAS" SG_ 280 HAS_Status 0;
BA_ "GenSigTimeoutTime_VDCM" SG_ 280 HAS_Status 0;
BA_ "GenSigTimeoutTime_BSM" SG_ 280 HAS_Status 0;
BA_ "GenSigTimeoutTime_EPS" SG_ 280 HAS_Status 0;
BA_ "GenSigTimeoutTime_MPAD" SG_ 280 HAS_OpStat_Prim 0;
BA_ "GenSigTimeoutTime_ADCAM" SG_ 280 HAS_OpStat_Prim 0;
BA_ "GenSigTimeoutTime_CVADAS" SG_ 280 HAS_OpStat_Prim 0;
BA_ "GenSigTimeoutTime_MPAD" SG_ 280 HAS_LAT_CTRL_RequestSts 0;
BA_ "GenSigTimeoutTime_ADCAM" SG_ 280 HAS_LAT_CTRL_RequestSts 0;
BA_ "GenSigTimeoutTime_CVADAS" SG_ 280 HAS_LAT_CTRL_RequestSts 0;
BA_ "GenSigTimeoutTime_VDCM" SG_ 280 HAS_LAT_CTRL_RequestSts 0;
BA_ "GenSigTimeoutTime_MPAD" SG_ 280 DDD_SystemSts 0;
BA_ "GenSigTimeoutTime_ADCAM" SG_ 280 DDD_SystemSts 0;
BA_ "GenSigTimeoutTime_CVADAS" SG_ 280 DDD_SystemSts 0;
BA_ "GenSigTimeoutTime_VDCM" SG_ 280 DDD_SystemSts 0;
BA_ "GenSigTimeoutTime_MPAD" SG_ 280 DDD_Setting_Avail 0;
BA_ "GenSigTimeoutTime_ADCAM" SG_ 280 DDD_Setting_Avail 0;
BA_ "GenSigTimeoutTime_CVADAS" SG_ 280 DDD_Setting_Avail 0;
BA_ "GenSigTimeoutTime_VDCM" SG_ 280 DDD_Setting_Avail 0;
BA_ "GenSigTimeoutTime_MPAD" SG_ 280 ESCALATION_TYPE 0;
BA_ "GenSigTimeoutTime_ADCAM" SG_ 280 ESCALATION_TYPE 0;
BA_ "GenSigTimeoutTime_CVADAS" SG_ 280 ESCALATION_TYPE 0;
BA_ "GenSigTimeoutTime_ADCAM" SG_ 280 CADM_OpStat 0;
BA_ "GenSigTimeoutTime_CVADAS" SG_ 280 CADM_OpStat 0;
BA_ "GenSigTimeoutTime_MPAD" SG_ 280 CADM_OpStat 0;
BA_ "GenSigTimeoutTime_MPAD" SG_ 280 AEB_Systemsts 0;
BA_ "GenSigTimeoutTime_ADCAM" SG_ 280 AEB_Systemsts 0;
BA_ "GenSigTimeoutTime_CVADAS" SG_ 280 AEB_Systemsts 0;
BA_ "GenSigTimeoutTime_VDCM" SG_ 280 AEB_Systemsts 0;
BA_ "GenSigTimeoutTime_MPAD" SG_ 280 ACC_Wheel_Torque 0;
BA_ "GenSigTimeoutTime_ADCAM" SG_ 280 ACC_Wheel_Torque 0;
BA_ "GenSigTimeoutTime_CVADAS" SG_ 280 ACC_Wheel_Torque 0;
BA_ "GenSigTimeoutTime_BSM" SG_ 280 ACC_Wheel_Torque 0;
BA_ "GenSigTimeoutTime_BSM2" SG_ 280 ACC_Wheel_Torque 0;
BA_ "GenSigTimeoutTime_EPS" SG_ 280 ACC_Wheel_Torque 0;
BA_ "GenSigTimeoutTime_ORC" SG_ 280 ACC_Wheel_Torque 0;
BA_ "GenSigTimeoutTime_MPAD" SG_ 280 AEB_Type 0;
BA_ "GenSigTimeoutTime_ADCAM" SG_ 280 AEB_Type 0;
BA_ "GenSigTimeoutTime_CVADAS" SG_ 280 AEB_Type 0;
BA_ "GenSigTimeoutTime_VDCM" SG_ 280 AEB_Type 0;
BA_ "GenSigTimeoutTime_MPAD" SG_ 280 ACC_Systemsts 0;
BA_ "GenSigTimeoutTime_ADCAM" SG_ 280 ACC_Systemsts 0;
BA_ "GenSigTimeoutTime_CVADAS" SG_ 280 ACC_Systemsts 0;
BA_ "GenSigTimeoutTime_VDCM" SG_ 280 ACC_Systemsts 0;
BA_ "GenSigTimeoutTime_MPAD" SG_ 280 ACC_Wheel_Torque_Enabled 0;
BA_ "GenSigTimeoutTime_ADCAM" SG_ 280 ACC_Wheel_Torque_Enabled 0;
BA_ "GenSigTimeoutTime_CVADAS" SG_ 280 ACC_Wheel_Torque_Enabled 0;
BA_ "GenSigTimeoutTime_BSM" SG_ 280 ACC_Wheel_Torque_Enabled 0;
BA_ "GenSigTimeoutTime_BSM2" SG_ 280 ACC_Wheel_Torque_Enabled 0;
BA_ "GenSigTimeoutTime_EPS" SG_ 280 ACC_Wheel_Torque_Enabled 0;
BA_ "GenSigTimeoutTime_ORC" SG_ 280 ACC_Wheel_Torque_Enabled 0;
BA_ "GenSigTimeoutTime_MPAD" SG_ 280 GrMax_Rq_ACC 0;
BA_ "GenSigTimeoutTime_ADCAM" SG_ 280 GrMax_Rq_ACC 0;
BA_ "GenSigTimeoutTime_CVADAS" SG_ 280 GrMax_Rq_ACC 0;
BA_ "GenSigTimeoutTime_VDCM" SG_ 280 GrMax_Rq_ACC 0;
BA_ "GenSigTimeoutTime_MPAD" SG_ 280 CIPV_Fused 0;
BA_ "GenSigTimeoutTime_ADCAM" SG_ 280 CIPV_Fused 0;
BA_ "GenSigTimeoutTime_CVADAS" SG_ 280 CIPV_Fused 0;
BA_ "GenSigTimeoutTime_VDCM" SG_ 280 CIPV_Fused 0;
BA_ "GenSigTimeoutTime_MPAD" SG_ 280 Brake_Jerk_Req 0;
BA_ "GenSigTimeoutTime_ADCAM" SG_ 280 Brake_Jerk_Req 0;
BA_ "GenSigTimeoutTime_CVADAS" SG_ 280 Brake_Jerk_Req 0;
BA_ "GenSigTimeoutTime_VDCM" SG_ 280 Brake_Jerk_Req 0;
BA_ "GenSigTimeoutTime_BSM2" SG_ 280 Brake_Jerk_Req 0;
BA_ "GenSigTimeoutTime_MPAD" SG_ 280 ACC_Engine_Torque_Enabled 0;
BA_ "GenSigTimeoutTime_ADCAM" SG_ 280 ACC_Engine_Torque_Enabled 0;
BA_ "GenSigTimeoutTime_CVADAS" SG_ 280 ACC_Engine_Torque_Enabled 0;
BA_ "GenSigTimeoutTime_BSM2" SG_ 280 ACC_Engine_Torque_Enabled 0;
BA_ "GenSigTimeoutTime_EPS" SG_ 280 ACC_Engine_Torque_Enabled 0;
BA_ "GenSigTimeoutTime_EVCU2" SG_ 280 ACC_Engine_Torque_Enabled 0;
BA_ "GenSigTimeoutTime_ORC" SG_ 280 ACC_Engine_Torque_Enabled 0;
BA_ "GenSigTimeoutTime_MPAD" SG_ 280 ACC_Drive_Cmd 0;
BA_ "GenSigTimeoutTime_ADCAM" SG_ 280 ACC_Drive_Cmd 0;
BA_ "GenSigTimeoutTime_CVADAS" SG_ 280 ACC_Drive_Cmd 0;
BA_ "GenSigTimeoutTime_VDCM" SG_ 280 ACC_Drive_Cmd 0;
BA_ "GenSigTimeoutTime_MPAD" SG_ 280 LKA_LAT_CTRL_RequestSts 0;
BA_ "GenSigTimeoutTime_ADCAM" SG_ 280 LKA_LAT_CTRL_RequestSts 0;
BA_ "GenSigTimeoutTime_CVADAS" SG_ 280 LKA_LAT_CTRL_RequestSts 0;
BA_ "GenSigTimeoutTime_VDCM" SG_ 280 LKA_LAT_CTRL_RequestSts 0;
BA_ "GenSigTimeoutTime_MPAD" SG_ 280 SteeringVibration_Type 0;
BA_ "GenSigTimeoutTime_ADCAM" SG_ 280 SteeringVibration_Type 0;
BA_ "GenSigTimeoutTime_CVADAS" SG_ 280 SteeringVibration_Type 0;
BA_ "GenSigTimeoutTime_VDCM" SG_ 280 SteeringVibration_Type 0;
BA_ "GenSigTimeoutTime_MPAD" SG_ 280 SteeringVibration_Rq 0;
BA_ "GenSigTimeoutTime_ADCAM" SG_ 280 SteeringVibration_Rq 0;
BA_ "GenSigTimeoutTime_CVADAS" SG_ 280 SteeringVibration_Rq 0;
BA_ "GenSigTimeoutTime_VDCM" SG_ 280 SteeringVibration_Rq 0;
BA_ "GenSigTimeoutTime_MPAD" SG_ 280 AEB_Sensitivity_Setting 0;
BA_ "GenSigTimeoutTime_ADCAM" SG_ 280 AEB_Sensitivity_Setting 0;
BA_ "GenSigTimeoutTime_CVADAS" SG_ 280 AEB_Sensitivity_Setting 0;
BA_ "GenSigTimeoutTime_VDCM" SG_ 280 AEB_Sensitivity_Setting 0;
BA_ "GenSigTimeoutTime_MPAD" SG_ 280 LC_Jerk 0;
BA_ "GenSigTimeoutTime_MPAD" SG_ 280 LANE_CHANGE_STATUS 0;
BA_ "GenSigTimeoutTime_ADCAM" SG_ 280 LANE_CHANGE_STATUS 0;
BA_ "GenSigTimeoutTime_CVADAS" SG_ 280 LANE_CHANGE_STATUS 0;
BA_ "GenSigTimeoutTime_MPAD" SG_ 280 CADM2_EPSSEC_FAIL 0;
BA_ "GenSigTimeoutTime_ADCAM" SG_ 280 CADM2_EPSSEC_FAIL 0;
BA_ "GenSigTimeoutTime_CVADAS" SG_ 280 CADM2_EPSSEC_FAIL 0;
BA_ "GenSigTimeoutTime_MPAD" SG_ 2654486689 CBV_bit0_RepeatMessageRequestBit_1E3840A1 0;
BA_ "GenSigTimeoutTime_BSM2" SG_ 2654486689 CBV_bit0_RepeatMessageRequestBit_1E3840A1 0;
BA_ "GenSigTimeoutTime_ADCAM" SG_ 2654486689 CBV_bit0_RepeatMessageRequestBit_1E3840A1 0;
BA_ "GenSigTimeoutTime_CVADAS" SG_ 2654486689 CBV_bit0_RepeatMessageRequestBit_1E3840A1 0;
BA_ "GenSigTimeoutTime_MPAD" SG_ 2654486701 CBV_bit6_PartialNtwInfBit_1E3840AD 0;
BA_ "GenSigTimeoutTime_ADCAM" SG_ 2654486701 CBV_bit6_PartialNtwInfBit_1E3840AD 0;
BA_ "GenSigTimeoutTime_CVADAS" SG_ 2654486701 CBV_bit6_PartialNtwInfBit_1E3840AD 0;
BA_ "GenSigTimeoutTime_BSM" SG_ 2654486701 CBV_bit6_PartialNtwInfBit_1E3840AD 0;
BA_ "GenSigTimeoutTime_BSM2" SG_ 2654486701 CBV_bit6_PartialNtwInfBit_1E3840AD 0;
BA_ "GenSigTimeoutTime_EPS" SG_ 2654486701 CBV_bit6_PartialNtwInfBit_1E3840AD 0;
BA_ "GenSigTimeoutTime_EVCU2" SG_ 2654486701 CBV_bit6_PartialNtwInfBit_1E3840AD 0;
BA_ "GenSigTimeoutTime_ORC" SG_ 2654486701 CBV_bit6_PartialNtwInfBit_1E3840AD 0;
BA_ "GenSigTimeoutTime_MPAD" SG_ 2654486701 CBV_bit4_ActiveWakeupBit_1E3840AD 0;
BA_ "GenSigTimeoutTime_ADCAM" SG_ 2654486701 CBV_bit4_ActiveWakeupBit_1E3840AD 0;
BA_ "GenSigTimeoutTime_CVADAS" SG_ 2654486701 CBV_bit4_ActiveWakeupBit_1E3840AD 0;
BA_ "GenSigTimeoutTime_BSM" SG_ 2654486701 CBV_bit4_ActiveWakeupBit_1E3840AD 0;
BA_ "GenSigTimeoutTime_BSM2" SG_ 2654486701 CBV_bit4_ActiveWakeupBit_1E3840AD 0;
BA_ "GenSigTimeoutTime_EPS" SG_ 2654486701 CBV_bit4_ActiveWakeupBit_1E3840AD 0;
BA_ "GenSigTimeoutTime_EVCU2" SG_ 2654486701 CBV_bit4_ActiveWakeupBit_1E3840AD 0;
BA_ "GenSigTimeoutTime_ORC" SG_ 2654486701 CBV_bit4_ActiveWakeupBit_1E3840AD 0;
BA_ "GenSigTimeoutTime_MPAD" SG_ 2654486701 CBV_bit7_1E3840AD 0;
BA_ "GenSigTimeoutTime_ADCAM" SG_ 2654486701 CBV_bit7_1E3840AD 0;
BA_ "GenSigTimeoutTime_CVADAS" SG_ 2654486701 CBV_bit7_1E3840AD 0;
BA_ "GenSigTimeoutTime_BSM" SG_ 2654486701 CBV_bit7_1E3840AD 0;
BA_ "GenSigTimeoutTime_BSM2" SG_ 2654486701 CBV_bit7_1E3840AD 0;
BA_ "GenSigTimeoutTime_EPS" SG_ 2654486701 CBV_bit7_1E3840AD 0;
BA_ "GenSigTimeoutTime_EVCU2" SG_ 2654486701 CBV_bit7_1E3840AD 0;
BA_ "GenSigTimeoutTime_ORC" SG_ 2654486701 CBV_bit7_1E3840AD 0;
BA_ "GenSigTimeoutTime_MPAD" SG_ 2654486701 CBV_bit1_1E3840AD 0;
BA_ "GenSigTimeoutTime_ADCAM" SG_ 2654486701 CBV_bit1_1E3840AD 0;
BA_ "GenSigTimeoutTime_CVADAS" SG_ 2654486701 CBV_bit1_1E3840AD 0;
BA_ "GenSigTimeoutTime_BSM" SG_ 2654486701 CBV_bit1_1E3840AD 0;
BA_ "GenSigTimeoutTime_BSM2" SG_ 2654486701 CBV_bit1_1E3840AD 0;
BA_ "GenSigTimeoutTime_EPS" SG_ 2654486701 CBV_bit1_1E3840AD 0;
BA_ "GenSigTimeoutTime_EVCU2" SG_ 2654486701 CBV_bit1_1E3840AD 0;
BA_ "GenSigTimeoutTime_ORC" SG_ 2654486701 CBV_bit1_1E3840AD 0;
BA_ "GenSigTimeoutTime_MPAD" SG_ 2654486701 SourceNodeIdentifier_1E3840AD 0;
BA_ "GenSigTimeoutTime_ADCAM" SG_ 2654486701 SourceNodeIdentifier_1E3840AD 0;
BA_ "GenSigTimeoutTime_CVADAS" SG_ 2654486701 SourceNodeIdentifier_1E3840AD 0;
BA_ "GenSigTimeoutTime_BSM" SG_ 2654486701 SourceNodeIdentifier_1E3840AD 0;
BA_ "GenSigTimeoutTime_BSM2" SG_ 2654486701 SourceNodeIdentifier_1E3840AD 0;
BA_ "GenSigTimeoutTime_EPS" SG_ 2654486701 SourceNodeIdentifier_1E3840AD 0;
BA_ "GenSigTimeoutTime_EVCU2" SG_ 2654486701 SourceNodeIdentifier_1E3840AD 0;
BA_ "GenSigTimeoutTime_ORC" SG_ 2654486701 SourceNodeIdentifier_1E3840AD 0;
BA_ "GenSigTimeoutTime_MPAD" SG_ 2654486701 CBV_bit3_NMCoordinatorBit_1E3840AD 0;
BA_ "GenSigTimeoutTime_ADCAM" SG_ 2654486701 CBV_bit3_NMCoordinatorBit_1E3840AD 0;
BA_ "GenSigTimeoutTime_CVADAS" SG_ 2654486701 CBV_bit3_NMCoordinatorBit_1E3840AD 0;
BA_ "GenSigTimeoutTime_BSM" SG_ 2654486701 CBV_bit3_NMCoordinatorBit_1E3840AD 0;
BA_ "GenSigTimeoutTime_BSM2" SG_ 2654486701 CBV_bit3_NMCoordinatorBit_1E3840AD 0;
BA_ "GenSigTimeoutTime_EPS" SG_ 2654486701 CBV_bit3_NMCoordinatorBit_1E3840AD 0;
BA_ "GenSigTimeoutTime_EVCU2" SG_ 2654486701 CBV_bit3_NMCoordinatorBit_1E3840AD 0;
BA_ "GenSigTimeoutTime_ORC" SG_ 2654486701 CBV_bit3_NMCoordinatorBit_1E3840AD 0;
BA_ "GenSigTimeoutTime_MPAD" SG_ 2654486701 CBV_bit0_RepeatMessageRequestBit_1E3840AD 0;
BA_ "GenSigTimeoutTime_ADCAM" SG_ 2654486701 CBV_bit0_RepeatMessageRequestBit_1E3840AD 0;
BA_ "GenSigTimeoutTime_CVADAS" SG_ 2654486701 CBV_bit0_RepeatMessageRequestBit_1E3840AD 0;
BA_ "GenSigTimeoutTime_BSM" SG_ 2654486701 CBV_bit0_RepeatMessageRequestBit_1E3840AD 0;
BA_ "GenSigTimeoutTime_BSM2" SG_ 2654486701 CBV_bit0_RepeatMessageRequestBit_1E3840AD 0;
BA_ "GenSigTimeoutTime_EPS" SG_ 2654486701 CBV_bit0_RepeatMessageRequestBit_1E3840AD 0;
BA_ "GenSigTimeoutTime_EVCU2" SG_ 2654486701 CBV_bit0_RepeatMessageRequestBit_1E3840AD 0;
BA_ "GenSigTimeoutTime_ORC" SG_ 2654486701 CBV_bit0_RepeatMessageRequestBit_1E3840AD 0;
BA_ "GenSigTimeoutTime_MPAD" SG_ 2654486701 CBV_bit5_1E3840AD 0;
BA_ "GenSigTimeoutTime_ADCAM" SG_ 2654486701 CBV_bit5_1E3840AD 0;
BA_ "GenSigTimeoutTime_CVADAS" SG_ 2654486701 CBV_bit5_1E3840AD 0;
BA_ "GenSigTimeoutTime_BSM" SG_ 2654486701 CBV_bit5_1E3840AD 0;
BA_ "GenSigTimeoutTime_BSM2" SG_ 2654486701 CBV_bit5_1E3840AD 0;
BA_ "GenSigTimeoutTime_EPS" SG_ 2654486701 CBV_bit5_1E3840AD 0;
BA_ "GenSigTimeoutTime_EVCU2" SG_ 2654486701 CBV_bit5_1E3840AD 0;
BA_ "GenSigTimeoutTime_ORC" SG_ 2654486701 CBV_bit5_1E3840AD 0;
BA_ "GenSigTimeoutTime_EPS" SG_ 2654486701 CBV_bit2_1E3840AD 0;
BA_ "GenSigTimeoutTime_EVCU2" SG_ 2654486701 CBV_bit2_1E3840AD 0;
BA_ "GenSigTimeoutTime_ORC" SG_ 2654486701 CBV_bit2_1E3840AD 0;
BA_ "GenSigTimeoutTime_MPAD" SG_ 2654486701 CBV_bit2_1E3840AD 0;
BA_ "GenSigTimeoutTime_ADCAM" SG_ 2654486701 CBV_bit2_1E3840AD 0;
BA_ "GenSigTimeoutTime_CVADAS" SG_ 2654486701 CBV_bit2_1E3840AD 0;
BA_ "GenSigTimeoutTime_BSM" SG_ 2654486701 CBV_bit2_1E3840AD 0;
BA_ "GenSigTimeoutTime_BSM2" SG_ 2654486701 CBV_bit2_1E3840AD 0;
BA_ "GenSigTimeoutTime_VDCM" SG_ 2654486689 CBV_bit0_RepeatMessageRequestBit_1E3840A1 0;
BA_ "GenSigTimeoutTime_BSM" SG_ 2654486689 CBV_bit0_RepeatMessageRequestBit_1E3840A1 0;
BA_ "GenSigTimeoutTime_ECM" SG_ 2654486689 CBV_bit0_RepeatMessageRequestBit_1E3840A1 0;
BA_ "GenSigTimeoutTime_EPS" SG_ 2654486689 CBV_bit0_RepeatMessageRequestBit_1E3840A1 0;
BA_ "GenSigTimeoutTime_EVCU2" SG_ 2654486689 CBV_bit0_RepeatMessageRequestBit_1E3840A1 0;
BA_ "GenSigTimeoutTime_ORC" SG_ 2654486689 CBV_bit0_RepeatMessageRequestBit_1E3840A1 0;
BA_ "GenSigTimeoutTime_MPAD" SG_ 2654486689 CBV_bit7_1E3840A1 0;
BA_ "GenSigTimeoutTime_BSM2" SG_ 2654486689 CBV_bit7_1E3840A1 0;
BA_ "GenSigTimeoutTime_ADCAM" SG_ 2654486689 CBV_bit7_1E3840A1 0;
BA_ "GenSigTimeoutTime_CVADAS" SG_ 2654486689 CBV_bit7_1E3840A1 0;
BA_ "GenSigTimeoutTime_VDCM" SG_ 2654486689 CBV_bit7_1E3840A1 0;
BA_ "GenSigTimeoutTime_BSM" SG_ 2654486689 CBV_bit7_1E3840A1 0;
BA_ "GenSigTimeoutTime_ECM" SG_ 2654486689 CBV_bit7_1E3840A1 0;
BA_ "GenSigTimeoutTime_EPS" SG_ 2654486689 CBV_bit7_1E3840A1 0;
BA_ "GenSigTimeoutTime_EVCU2" SG_ 2654486689 CBV_bit7_1E3840A1 0;
BA_ "GenSigTimeoutTime_ORC" SG_ 2654486689 CBV_bit7_1E3840A1 0;
BA_ "GenSigTimeoutTime_MPAD" SG_ 2654486689 CBV_bit4_ActiveWakeupBit_1E3840A1 0;
BA_ "GenSigTimeoutTime_BSM2" SG_ 2654486689 CBV_bit4_ActiveWakeupBit_1E3840A1 0;
BA_ "GenSigTimeoutTime_ADCAM" SG_ 2654486689 CBV_bit4_ActiveWakeupBit_1E3840A1 0;
BA_ "GenSigTimeoutTime_CVADAS" SG_ 2654486689 CBV_bit4_ActiveWakeupBit_1E3840A1 0;
BA_ "GenSigTimeoutTime_VDCM" SG_ 2654486689 CBV_bit4_ActiveWakeupBit_1E3840A1 0;
BA_ "GenSigTimeoutTime_BSM" SG_ 2654486689 CBV_bit4_ActiveWakeupBit_1E3840A1 0;
BA_ "GenSigTimeoutTime_ECM" SG_ 2654486689 CBV_bit4_ActiveWakeupBit_1E3840A1 0;
BA_ "GenSigTimeoutTime_EPS" SG_ 2654486689 CBV_bit4_ActiveWakeupBit_1E3840A1 0;
BA_ "GenSigTimeoutTime_EVCU2" SG_ 2654486689 CBV_bit4_ActiveWakeupBit_1E3840A1 0;
BA_ "GenSigTimeoutTime_ORC" SG_ 2654486689 CBV_bit4_ActiveWakeupBit_1E3840A1 0;
BA_ "GenSigTimeoutTime_MPAD" SG_ 2654486689 CBV_bit3_NMCoordinatorBit_1E3840A1 0;
BA_ "GenSigTimeoutTime_BSM2" SG_ 2654486689 CBV_bit3_NMCoordinatorBit_1E3840A1 0;
BA_ "GenSigTimeoutTime_ADCAM" SG_ 2654486689 CBV_bit3_NMCoordinatorBit_1E3840A1 0;
BA_ "GenSigTimeoutTime_CVADAS" SG_ 2654486689 CBV_bit3_NMCoordinatorBit_1E3840A1 0;
BA_ "GenSigTimeoutTime_VDCM" SG_ 2654486689 CBV_bit3_NMCoordinatorBit_1E3840A1 0;
BA_ "GenSigTimeoutTime_BSM" SG_ 2654486689 CBV_bit3_NMCoordinatorBit_1E3840A1 0;
BA_ "GenSigTimeoutTime_ECM" SG_ 2654486689 CBV_bit3_NMCoordinatorBit_1E3840A1 0;
BA_ "GenSigTimeoutTime_EPS" SG_ 2654486689 CBV_bit3_NMCoordinatorBit_1E3840A1 0;
BA_ "GenSigTimeoutTime_EVCU2" SG_ 2654486689 CBV_bit3_NMCoordinatorBit_1E3840A1 0;
BA_ "GenSigTimeoutTime_ORC" SG_ 2654486689 CBV_bit3_NMCoordinatorBit_1E3840A1 0;
BA_ "GenSigTimeoutTime_MPAD" SG_ 2654486689 CBV_bit6_PartialNtwInfBit_1E3840A1 0;
BA_ "GenSigTimeoutTime_BSM2" SG_ 2654486689 CBV_bit6_PartialNtwInfBit_1E3840A1 0;
BA_ "GenSigTimeoutTime_ADCAM" SG_ 2654486689 CBV_bit6_PartialNtwInfBit_1E3840A1 0;
BA_ "GenSigTimeoutTime_CVADAS" SG_ 2654486689 CBV_bit6_PartialNtwInfBit_1E3840A1 0;
BA_ "GenSigTimeoutTime_VDCM" SG_ 2654486689 CBV_bit6_PartialNtwInfBit_1E3840A1 0;
BA_ "GenSigTimeoutTime_BSM" SG_ 2654486689 CBV_bit6_PartialNtwInfBit_1E3840A1 0;
BA_ "GenSigTimeoutTime_ECM" SG_ 2654486689 CBV_bit6_PartialNtwInfBit_1E3840A1 0;
BA_ "GenSigTimeoutTime_EPS" SG_ 2654486689 CBV_bit6_PartialNtwInfBit_1E3840A1 0;
BA_ "GenSigTimeoutTime_EVCU2" SG_ 2654486689 CBV_bit6_PartialNtwInfBit_1E3840A1 0;
BA_ "GenSigTimeoutTime_ORC" SG_ 2654486689 CBV_bit6_PartialNtwInfBit_1E3840A1 0;
BA_ "GenSigTimeoutTime_MPAD" SG_ 2654486689 SourceNodeIdentifier_1E3840A1 0;
BA_ "GenSigTimeoutTime_BSM2" SG_ 2654486689 SourceNodeIdentifier_1E3840A1 0;
BA_ "GenSigTimeoutTime_ADCAM" SG_ 2654486689 SourceNodeIdentifier_1E3840A1 0;
BA_ "GenSigTimeoutTime_CVADAS" SG_ 2654486689 SourceNodeIdentifier_1E3840A1 0;
BA_ "GenSigTimeoutTime_VDCM" SG_ 2654486689 SourceNodeIdentifier_1E3840A1 0;
BA_ "GenSigTimeoutTime_BSM" SG_ 2654486689 SourceNodeIdentifier_1E3840A1 0;
BA_ "GenSigTimeoutTime_ECM" SG_ 2654486689 SourceNodeIdentifier_1E3840A1 0;
BA_ "GenSigTimeoutTime_EPS" SG_ 2654486689 SourceNodeIdentifier_1E3840A1 0;
BA_ "GenSigTimeoutTime_EVCU2" SG_ 2654486689 SourceNodeIdentifier_1E3840A1 0;
BA_ "GenSigTimeoutTime_ORC" SG_ 2654486689 SourceNodeIdentifier_1E3840A1 0;
BA_ "GenSigTimeoutTime_MPAD" SG_ 2654486689 CBV_bit1_1E3840A1 0;
BA_ "GenSigTimeoutTime_BSM2" SG_ 2654486689 CBV_bit1_1E3840A1 0;
BA_ "GenSigTimeoutTime_ADCAM" SG_ 2654486689 CBV_bit1_1E3840A1 0;
BA_ "GenSigTimeoutTime_CVADAS" SG_ 2654486689 CBV_bit1_1E3840A1 0;
BA_ "GenSigTimeoutTime_VDCM" SG_ 2654486689 CBV_bit1_1E3840A1 0;
BA_ "GenSigTimeoutTime_BSM" SG_ 2654486689 CBV_bit1_1E3840A1 0;
BA_ "GenSigTimeoutTime_ECM" SG_ 2654486689 CBV_bit1_1E3840A1 0;
BA_ "GenSigTimeoutTime_EPS" SG_ 2654486689 CBV_bit1_1E3840A1 0;
BA_ "GenSigTimeoutTime_EVCU2" SG_ 2654486689 CBV_bit1_1E3840A1 0;
BA_ "GenSigTimeoutTime_ORC" SG_ 2654486689 CBV_bit1_1E3840A1 0;
BA_ "GenSigTimeoutTime_MPAD" SG_ 2654486689 CBV_bit5_1E3840A1 0;
BA_ "GenSigTimeoutTime_BSM2" SG_ 2654486689 CBV_bit5_1E3840A1 0;
BA_ "GenSigTimeoutTime_ADCAM" SG_ 2654486689 CBV_bit5_1E3840A1 0;
BA_ "GenSigTimeoutTime_CVADAS" SG_ 2654486689 CBV_bit5_1E3840A1 0;
BA_ "GenSigTimeoutTime_VDCM" SG_ 2654486689 CBV_bit5_1E3840A1 0;
BA_ "GenSigTimeoutTime_BSM" SG_ 2654486689 CBV_bit5_1E3840A1 0;
BA_ "GenSigTimeoutTime_ECM" SG_ 2654486689 CBV_bit5_1E3840A1 0;
BA_ "GenSigTimeoutTime_EPS" SG_ 2654486689 CBV_bit5_1E3840A1 0;
BA_ "GenSigTimeoutTime_EVCU2" SG_ 2654486689 CBV_bit5_1E3840A1 0;
BA_ "GenSigTimeoutTime_ORC" SG_ 2654486689 CBV_bit5_1E3840A1 0;
BA_ "GenSigTimeoutTime_MPAD" SG_ 2654486689 CBV_bit2_1E3840A1 0;
BA_ "GenSigTimeoutTime_BSM2" SG_ 2654486689 CBV_bit2_1E3840A1 0;
BA_ "GenSigTimeoutTime_ADCAM" SG_ 2654486689 CBV_bit2_1E3840A1 0;
BA_ "GenSigTimeoutTime_CVADAS" SG_ 2654486689 CBV_bit2_1E3840A1 0;
BA_ "GenSigTimeoutTime_VDCM" SG_ 2654486689 CBV_bit2_1E3840A1 0;
BA_ "GenSigTimeoutTime_BSM" SG_ 2654486689 CBV_bit2_1E3840A1 0;
BA_ "GenSigTimeoutTime_ECM" SG_ 2654486689 CBV_bit2_1E3840A1 0;
BA_ "GenSigTimeoutTime_EPS" SG_ 2654486689 CBV_bit2_1E3840A1 0;
BA_ "GenSigTimeoutTime_EVCU2" SG_ 2654486689 CBV_bit2_1E3840A1 0;
BA_ "GenSigTimeoutTime_ORC" SG_ 2654486689 CBV_bit2_1E3840A1 0;
BA_ "GenSigTimeoutTime_MPAD" SG_ 292 BPCM_HV_Trac_Main_Contac_Sts 0;
BA_ "GenSigTimeoutTime_ADCAM" SG_ 292 BPCM_HV_Trac_Main_Contac_Sts 0;
BA_ "GenSigTimeoutTime_CVADAS" SG_ 292 BPCM_HV_Trac_Main_Contac_Sts 0;
BA_ "GenSigTimeoutTime_VDCM" SG_ 292 BPCM_HV_Trac_Main_Contac_Sts 0;
BA_ "GenSigTimeoutTime_MPAD" SG_ 292 BPCM_HV_Trac_Bus_Sts 0;
BA_ "GenSigTimeoutTime_ADCAM" SG_ 292 BPCM_HV_Trac_Bus_Sts 0;
BA_ "GenSigTimeoutTime_CVADAS" SG_ 292 BPCM_HV_Trac_Bus_Sts 0;
BA_ "GenSigTimeoutTime_VDCM" SG_ 292 BPCM_HV_Trac_Bus_Sts 0;
BA_ "GenSigTimeoutTime_MPAD" SG_ 292 BPCM_HV_InternalVoltage 0;
BA_ "GenSigTimeoutTime_ADCAM" SG_ 292 BPCM_HV_InternalVoltage 0;
BA_ "GenSigTimeoutTime_CVADAS" SG_ 292 BPCM_HV_InternalVoltage 0;
BA_ "GenSigTimeoutTime_VDCM" SG_ 292 BPCM_HV_InternalVoltage 0;
BA_ "GenSigTimeoutTime_BSM" SG_ 292 BPCM_HV_InternalVoltage 0;
BA_ "GenSigTimeoutTime_BSM2" SG_ 292 BPCM_HV_InternalVoltage 0;
BA_ "GenSigTimeoutTime_CADM" SG_ 292 BPCM_HV_InternalVoltage 0;
BA_ "GenSigTimeoutTime_CVPAM" SG_ 292 BPCM_HV_InternalVoltage 0;
BA_ "GenSigTimeoutTime_ECM" SG_ 292 BPCM_HV_InternalVoltage 0;
BA_ "GenSigTimeoutTime_EPS" SG_ 292 BPCM_HV_InternalVoltage 0;
BA_ "GenSigTimeoutTime_EVCU2" SG_ 292 BPCM_HV_InternalVoltage 0;
BA_ "GenSigTimeoutTime_ORC" SG_ 292 BPCM_HV_InternalVoltage 0;
BA_ "GenSigTimeoutTime_MPAD" SG_ 292 BPCM_HV_SOC 0;
BA_ "GenSigTimeoutTime_ADCAM" SG_ 292 BPCM_HV_SOC 0;
BA_ "GenSigTimeoutTime_CVADAS" SG_ 292 BPCM_HV_SOC 0;
BA_ "GenSigTimeoutTime_VDCM" SG_ 292 BPCM_HV_SOC 0;
BA_ "GenSigTimeoutTime_BSM2" SG_ 292 BPCM_HV_SOC 0;
BA_ "GenSigTimeoutTime_CADM" SG_ 292 BPCM_HV_SOC 0;
BA_ "GenSigTimeoutTime_CVPAM" SG_ 292 BPCM_HV_SOC 0;
BA_ "GenSigTimeoutTime_ECM" SG_ 292 BPCM_HV_SOC 0;
BA_ "GenSigTimeoutTime_EPS" SG_ 292 BPCM_HV_SOC 0;
BA_ "GenSigTimeoutTime_EVCU2" SG_ 292 BPCM_HV_SOC 0;
BA_ "GenSigTimeoutTime_ORC" SG_ 292 BPCM_HV_SOC 0;
BA_ "GenSigTimeoutTime_CVADAS" SG_ 204 Axle_TorqueStatic_D_TTC 0;
BA_ "GenSigTimeoutTime_VDCM" SG_ 204 Axle_TorqueStatic_D_TTC 0;
BA_ "GenSigStartValue" SG_ 204 Axle_TorqueStatic_D_TTC 32767;
BA_ "GenSigTimeoutTime_BSM" SG_ 204 Axle_TorqueStatic_D_TTC 0;
BA_ "GenSigTimeoutTime_BSM2" SG_ 204 Axle_TorqueStatic_D_TTC 0;
BA_ "GenSigTimeoutTime_CVPAM" SG_ 204 Axle_TorqueStatic_D_TTC 0;
BA_ "GenSigTimeoutTime_ECM" SG_ 204 Axle_TorqueStatic_D_TTC 0;
BA_ "GenSigTimeoutTime_EPS" SG_ 204 Axle_TorqueStatic_D_TTC 0;
BA_ "GenSigTimeoutTime_EVCU2" SG_ 204 Axle_TorqueStatic_D_TTC 0;
BA_ "GenSigTimeoutTime_ORC" SG_ 204 Axle_TorqueStatic_D_TTC 0;
BA_ "GenSigTimeoutTime_CVADAS" SG_ 204 Axle_Torque_DrvReqMod 0;
BA_ "GenSigTimeoutTime_VDCM" SG_ 204 Axle_Torque_DrvReqMod 0;
BA_ "GenSigStartValue" SG_ 204 Axle_Torque_DrvReqMod 32768;
BA_ "GenSigTimeoutTime_BSM" SG_ 204 Axle_Torque_DrvReqMod 0;
BA_ "GenSigTimeoutTime_BSM2" SG_ 204 Axle_Torque_DrvReqMod 0;
BA_ "GenSigTimeoutTime_CVPAM" SG_ 204 Axle_Torque_DrvReqMod 0;
BA_ "GenSigTimeoutTime_ECM" SG_ 204 Axle_Torque_DrvReqMod 0;
BA_ "GenSigTimeoutTime_EPS" SG_ 204 Axle_Torque_DrvReqMod 0;
BA_ "GenSigTimeoutTime_EVCU2" SG_ 204 Axle_Torque_DrvReqMod 0;
BA_ "GenSigTimeoutTime_ORC" SG_ 204 Axle_Torque_DrvReqMod 0;
BA_ "GenSigTimeoutTime_CVADAS" SG_ 204 Total_AxleTorque_Max 0;
BA_ "GenSigTimeoutTime_VDCM" SG_ 204 Total_AxleTorque_Max 0;
BA_ "GenSigStartValue" SG_ 204 Total_AxleTorque_Max 32767;
BA_ "GenSigTimeoutTime_BSM" SG_ 204 Total_AxleTorque_Max 0;
BA_ "GenSigTimeoutTime_BSM2" SG_ 204 Total_AxleTorque_Max 0;
BA_ "GenSigTimeoutTime_CVPAM" SG_ 204 Total_AxleTorque_Max 0;
BA_ "GenSigTimeoutTime_ECM" SG_ 204 Total_AxleTorque_Max 0;
BA_ "GenSigTimeoutTime_EPS" SG_ 204 Total_AxleTorque_Max 0;
BA_ "GenSigTimeoutTime_EVCU2" SG_ 204 Total_AxleTorque_Max 0;
BA_ "GenSigTimeoutTime_ORC" SG_ 204 Total_AxleTorque_Max 0;
BA_ "GenSigTimeoutTime_CVADAS" SG_ 204 Total_AxleTorque_Min 0;
BA_ "GenSigTimeoutTime_VDCM" SG_ 204 Total_AxleTorque_Min 0;
BA_ "GenSigStartValue" SG_ 204 Total_AxleTorque_Min 32767;
BA_ "GenSigTimeoutTime_BSM" SG_ 204 Total_AxleTorque_Min 0;
BA_ "GenSigTimeoutTime_BSM2" SG_ 204 Total_AxleTorque_Min 0;
BA_ "GenSigTimeoutTime_CVPAM" SG_ 204 Total_AxleTorque_Min 0;
BA_ "GenSigTimeoutTime_ECM" SG_ 204 Total_AxleTorque_Min 0;
BA_ "GenSigTimeoutTime_EPS" SG_ 204 Total_AxleTorque_Min 0;
BA_ "GenSigTimeoutTime_EVCU2" SG_ 204 Total_AxleTorque_Min 0;
BA_ "GenSigTimeoutTime_ORC" SG_ 204 Total_AxleTorque_Min 0;
BA_ "GenSigTimeoutTime_MPAD" SG_ 205 DriverRequested_AxleTrq_BSM 0;
BA_ "GenSigTimeoutTime_ADCAM" SG_ 205 DriverRequested_AxleTrq_BSM 0;
BA_ "GenSigTimeoutTime_CVADAS" SG_ 205 DriverRequested_AxleTrq_BSM 0;
BA_ "GenSigTimeoutTime_VDCM" SG_ 205 DriverRequested_AxleTrq_BSM 0;
BA_ "GenSigStartValue" SG_ 205 TotalAxle_Rq_BSM 32767;
BA_ "GenSigTimeoutTime_BSM" SG_ 205 TotalAxle_Rq_BSM 0;
BA_ "GenSigTimeoutTime_BSM2" SG_ 205 TotalAxle_Rq_BSM 0;
BA_ "GenSigTimeoutTime_CADM" SG_ 205 TotalAxle_Rq_BSM 0;
BA_ "GenSigTimeoutTime_CVPAM" SG_ 205 TotalAxle_Rq_BSM 0;
BA_ "GenSigTimeoutTime_EPS" SG_ 205 TotalAxle_Rq_BSM 0;
BA_ "GenSigTimeoutTime_EVCU2" SG_ 205 TotalAxle_Rq_BSM 0;
BA_ "GenSigTimeoutTime_ORC" SG_ 205 TotalAxle_Rq_BSM 0;
BA_ "GenSigTimeoutTime_MPAD" SG_ 205 TotalAxle_Rq_BSM 0;
BA_ "GenSigTimeoutTime_ADCAM" SG_ 205 TotalAxle_Rq_BSM 0;
BA_ "GenSigTimeoutTime_CVADAS" SG_ 205 TotalAxle_Rq_BSM 0;
BA_ "GenSigTimeoutTime_VDCM" SG_ 205 TotalAxle_Rq_BSM 0;
BA_ "GenSigTimeoutTime_BSM" SG_ 292 BPCM_HV_Trac_Bus_Sts 0;
BA_ "GenSigTimeoutTime_BSM2" SG_ 292 BPCM_HV_Trac_Bus_Sts 0;
BA_ "GenSigTimeoutTime_CADM" SG_ 292 BPCM_HV_Trac_Bus_Sts 0;
BA_ "GenSigTimeoutTime_CVPAM" SG_ 292 BPCM_HV_Trac_Bus_Sts 0;
BA_ "GenSigTimeoutTime_ECM" SG_ 292 BPCM_HV_Trac_Bus_Sts 0;
BA_ "GenSigTimeoutTime_EPS" SG_ 292 BPCM_HV_Trac_Bus_Sts 0;
BA_ "GenSigTimeoutTime_EVCU2" SG_ 292 BPCM_HV_Trac_Bus_Sts 0;
BA_ "GenSigTimeoutTime_ORC" SG_ 292 BPCM_HV_Trac_Bus_Sts 0;
BA_ "GenSigTimeoutTime_BSM" SG_ 292 BPCM_HV_Trac_Main_Contac_Sts 0;
BA_ "GenSigTimeoutTime_BSM2" SG_ 292 BPCM_HV_Trac_Main_Contac_Sts 0;
BA_ "GenSigTimeoutTime_CADM" SG_ 292 BPCM_HV_Trac_Main_Contac_Sts 0;
BA_ "GenSigTimeoutTime_CVPAM" SG_ 292 BPCM_HV_Trac_Main_Contac_Sts 0;
BA_ "GenSigTimeoutTime_ECM" SG_ 292 BPCM_HV_Trac_Main_Contac_Sts 0;
BA_ "GenSigTimeoutTime_EPS" SG_ 292 BPCM_HV_Trac_Main_Contac_Sts 0;
BA_ "GenSigTimeoutTime_EVCU2" SG_ 292 BPCM_HV_Trac_Main_Contac_Sts 0;
BA_ "GenSigTimeoutTime_ORC" SG_ 292 BPCM_HV_Trac_Main_Contac_Sts 0;
BA_ "GenSigTimeoutTime_MPAD" SG_ 204 Front_Axle_Regen_Capacity 0;
BA_ "GenSigTimeoutTime_ADCAM" SG_ 204 Front_Axle_Regen_Capacity 0;
BA_ "GenSigTimeoutTime_CVADAS" SG_ 204 Front_Axle_Regen_Capacity 0;
BA_ "GenSigTimeoutTime_VDCM" SG_ 204 Front_Axle_Regen_Capacity 0;
BA_ "GenSigTimeoutTime_BSM2" SG_ 204 Front_Axle_Regen_Capacity 0;
BA_ "GenSigTimeoutTime_CADM" SG_ 204 Front_Axle_Regen_Capacity 0;
BA_ "GenSigTimeoutTime_CVPAM" SG_ 204 Front_Axle_Regen_Capacity 0;
BA_ "GenSigTimeoutTime_ECM" SG_ 204 Front_Axle_Regen_Capacity 0;
BA_ "GenSigTimeoutTime_EPS" SG_ 204 Front_Axle_Regen_Capacity 0;
BA_ "GenSigTimeoutTime_EVCU2" SG_ 204 Front_Axle_Regen_Capacity 0;
BA_ "GenSigTimeoutTime_ORC" SG_ 204 Front_Axle_Regen_Capacity 0;
BA_ "GenSigTimeoutTime_MPAD" SG_ 204 Front_Axle_Est_Regen_Torq 0;
BA_ "GenSigTimeoutTime_ADCAM" SG_ 204 Front_Axle_Est_Regen_Torq 0;
BA_ "GenSigTimeoutTime_CVADAS" SG_ 204 Front_Axle_Est_Regen_Torq 0;
BA_ "GenSigTimeoutTime_VDCM" SG_ 204 Front_Axle_Est_Regen_Torq 0;
BA_ "GenSigTimeoutTime_BSM2" SG_ 204 Front_Axle_Est_Regen_Torq 0;
BA_ "GenSigTimeoutTime_CADM" SG_ 204 Front_Axle_Est_Regen_Torq 0;
BA_ "GenSigTimeoutTime_CVPAM" SG_ 204 Front_Axle_Est_Regen_Torq 0;
BA_ "GenSigTimeoutTime_ECM" SG_ 204 Front_Axle_Est_Regen_Torq 0;
BA_ "GenSigTimeoutTime_EPS" SG_ 204 Front_Axle_Est_Regen_Torq 0;
BA_ "GenSigTimeoutTime_EVCU2" SG_ 204 Front_Axle_Est_Regen_Torq 0;
BA_ "GenSigTimeoutTime_ORC" SG_ 204 Front_Axle_Est_Regen_Torq 0;
BA_ "GenSigTimeoutTime_MPAD" SG_ 204 Rear_Axle_Est_Regen_Torq 0;
BA_ "GenSigTimeoutTime_ADCAM" SG_ 204 Rear_Axle_Est_Regen_Torq 0;
BA_ "GenSigTimeoutTime_CVADAS" SG_ 204 Rear_Axle_Est_Regen_Torq 0;
BA_ "GenSigTimeoutTime_VDCM" SG_ 204 Rear_Axle_Est_Regen_Torq 0;
BA_ "GenSigTimeoutTime_BSM2" SG_ 204 Rear_Axle_Est_Regen_Torq 0;
BA_ "GenSigTimeoutTime_CADM" SG_ 204 Rear_Axle_Est_Regen_Torq 0;
BA_ "GenSigTimeoutTime_CVPAM" SG_ 204 Rear_Axle_Est_Regen_Torq 0;
BA_ "GenSigTimeoutTime_ECM" SG_ 204 Rear_Axle_Est_Regen_Torq 0;
BA_ "GenSigTimeoutTime_EPS" SG_ 204 Rear_Axle_Est_Regen_Torq 0;
BA_ "GenSigTimeoutTime_EVCU2" SG_ 204 Rear_Axle_Est_Regen_Torq 0;
BA_ "GenSigTimeoutTime_ORC" SG_ 204 Rear_Axle_Est_Regen_Torq 0;
BA_ "GenSigTimeoutTime_MPAD" SG_ 204 Rear_Axle_Regen_Capacity 0;
BA_ "GenSigTimeoutTime_ADCAM" SG_ 204 Rear_Axle_Regen_Capacity 0;
BA_ "GenSigTimeoutTime_CVADAS" SG_ 204 Rear_Axle_Regen_Capacity 0;
BA_ "GenSigTimeoutTime_VDCM" SG_ 204 Rear_Axle_Regen_Capacity 0;
BA_ "GenSigTimeoutTime_BSM2" SG_ 204 Rear_Axle_Regen_Capacity 0;
BA_ "GenSigTimeoutTime_CADM" SG_ 204 Rear_Axle_Regen_Capacity 0;
BA_ "GenSigTimeoutTime_CVPAM" SG_ 204 Rear_Axle_Regen_Capacity 0;
BA_ "GenSigTimeoutTime_ECM" SG_ 204 Rear_Axle_Regen_Capacity 0;
BA_ "GenSigTimeoutTime_EPS" SG_ 204 Rear_Axle_Regen_Capacity 0;
BA_ "GenSigTimeoutTime_EVCU2" SG_ 204 Rear_Axle_Regen_Capacity 0;
BA_ "GenSigTimeoutTime_ORC" SG_ 204 Rear_Axle_Regen_Capacity 0;
BA_ "GenSigTimeoutTime_ADCAM" SG_ 205 CRC_BRAKE_FD_6 0;
BA_ "GenSigTimeoutTime_CVADAS" SG_ 205 CRC_BRAKE_FD_6 0;
BA_ "GenSigTimeoutTime_VDCM" SG_ 205 CRC_BRAKE_FD_6 0;
BA_ "GenSigTimeoutTime_MPAD" SG_ 205 RearAxle_Min_Rq_BSM 0;
BA_ "GenSigTimeoutTime_ADCAM" SG_ 205 RearAxle_Min_Rq_BSM 0;
BA_ "GenSigTimeoutTime_CVADAS" SG_ 205 RearAxle_Min_Rq_BSM 0;
BA_ "GenSigTimeoutTime_VDCM" SG_ 205 RearAxle_Min_Rq_BSM 0;
BA_ "GenSigTimeoutTime_ADCAM" SG_ 205 MessageCounter_BRAKE_FD_6 0;
BA_ "GenSigTimeoutTime_CVADAS" SG_ 205 MessageCounter_BRAKE_FD_6 0;
BA_ "GenSigTimeoutTime_VDCM" SG_ 205 MessageCounter_BRAKE_FD_6 0;
BA_ "GenSigTimeoutTime_MPAD" SG_ 205 TotalAxle_Min_Rq_BSM 0;
BA_ "GenSigTimeoutTime_ADCAM" SG_ 205 TotalAxle_Min_Rq_BSM 0;
BA_ "GenSigTimeoutTime_CVADAS" SG_ 205 TotalAxle_Min_Rq_BSM 0;
BA_ "GenSigTimeoutTime_VDCM" SG_ 205 TotalAxle_Min_Rq_BSM 0;
BA_ "GenSigTimeoutTime_MPAD" SG_ 205 FrontAxle_Max_Rq_BSM 0;
BA_ "GenSigTimeoutTime_ADCAM" SG_ 205 FrontAxle_Max_Rq_BSM 0;
BA_ "GenSigTimeoutTime_CVADAS" SG_ 205 FrontAxle_Max_Rq_BSM 0;
BA_ "GenSigTimeoutTime_VDCM" SG_ 205 FrontAxle_Max_Rq_BSM 0;
BA_ "GenSigTimeoutTime_MPAD" SG_ 205 FrontAxle_Min_Rq_BSM 0;
BA_ "GenSigTimeoutTime_ADCAM" SG_ 205 FrontAxle_Min_Rq_BSM 0;
BA_ "GenSigTimeoutTime_CVADAS" SG_ 205 FrontAxle_Min_Rq_BSM 0;
BA_ "GenSigTimeoutTime_VDCM" SG_ 205 FrontAxle_Min_Rq_BSM 0;
BA_ "GenSigTimeoutTime_MPAD" SG_ 205 RearAxle_Max_Rq_BSM 0;
BA_ "GenSigTimeoutTime_ADCAM" SG_ 205 RearAxle_Max_Rq_BSM 0;
BA_ "GenSigTimeoutTime_CVADAS" SG_ 205 RearAxle_Max_Rq_BSM 0;
BA_ "GenSigTimeoutTime_VDCM" SG_ 205 RearAxle_Max_Rq_BSM 0;
BA_ "GenSigTimeoutTime_MPAD" SG_ 204 CRC_AXLE_TORQUE_FD_1 0;
BA_ "GenSigTimeoutTime_ADCAM" SG_ 204 CRC_AXLE_TORQUE_FD_1 0;
BA_ "GenSigTimeoutTime_CVADAS" SG_ 204 CRC_AXLE_TORQUE_FD_1 0;
BA_ "GenSigTimeoutTime_VDCM" SG_ 204 CRC_AXLE_TORQUE_FD_1 0;
BA_ "GenSigTimeoutTime_BSM" SG_ 204 CRC_AXLE_TORQUE_FD_1 0;
BA_ "GenSigTimeoutTime_BSM2" SG_ 204 CRC_AXLE_TORQUE_FD_1 0;
BA_ "GenSigTimeoutTime_CADM" SG_ 204 CRC_AXLE_TORQUE_FD_1 0;
BA_ "GenSigTimeoutTime_CVPAM" SG_ 204 CRC_AXLE_TORQUE_FD_1 0;
BA_ "GenSigTimeoutTime_ECM" SG_ 204 CRC_AXLE_TORQUE_FD_1 0;
BA_ "GenSigTimeoutTime_EPS" SG_ 204 CRC_AXLE_TORQUE_FD_1 0;
BA_ "GenSigTimeoutTime_EVCU2" SG_ 204 CRC_AXLE_TORQUE_FD_1 0;
BA_ "GenSigTimeoutTime_ORC" SG_ 204 CRC_AXLE_TORQUE_FD_1 0;
BA_ "GenSigTimeoutTime_MPAD" SG_ 204 MessageCounter_AXLE_TORQUE_FD_1 0;
BA_ "GenSigTimeoutTime_ADCAM" SG_ 204 MessageCounter_AXLE_TORQUE_FD_1 0;
BA_ "GenSigTimeoutTime_CVADAS" SG_ 204 MessageCounter_AXLE_TORQUE_FD_1 0;
BA_ "GenSigTimeoutTime_VDCM" SG_ 204 MessageCounter_AXLE_TORQUE_FD_1 0;
BA_ "GenSigTimeoutTime_BSM" SG_ 204 MessageCounter_AXLE_TORQUE_FD_1 0;
BA_ "GenSigTimeoutTime_BSM2" SG_ 204 MessageCounter_AXLE_TORQUE_FD_1 0;
BA_ "GenSigTimeoutTime_CADM" SG_ 204 MessageCounter_AXLE_TORQUE_FD_1 0;
BA_ "GenSigTimeoutTime_CVPAM" SG_ 204 MessageCounter_AXLE_TORQUE_FD_1 0;
BA_ "GenSigTimeoutTime_ECM" SG_ 204 MessageCounter_AXLE_TORQUE_FD_1 0;
BA_ "GenSigTimeoutTime_EPS" SG_ 204 MessageCounter_AXLE_TORQUE_FD_1 0;
BA_ "GenSigTimeoutTime_EVCU2" SG_ 204 MessageCounter_AXLE_TORQUE_FD_1 0;
BA_ "GenSigTimeoutTime_ORC" SG_ 204 MessageCounter_AXLE_TORQUE_FD_1 0;
BA_ "GenSigTimeoutTime_MPAD" SG_ 205 Cmnd_TotBrkFrict_AxleTorq 0;
BA_ "GenSigTimeoutTime_ADCAM" SG_ 205 Cmnd_TotBrkFrict_AxleTorq 0;
BA_ "GenSigTimeoutTime_CVADAS" SG_ 205 Cmnd_TotBrkFrict_AxleTorq 0;
BA_ "GenSigTimeoutTime_VDCM" SG_ 205 Cmnd_TotBrkFrict_AxleTorq 0;
BA_ "GenSigTimeoutTime_MPAD" SG_ 205 DriverReq_AxleTrq_Enabled_BSM 0;
BA_ "GenSigTimeoutTime_ADCAM" SG_ 205 DriverReq_AxleTrq_Enabled_BSM 0;
BA_ "GenSigTimeoutTime_CVADAS" SG_ 205 DriverReq_AxleTrq_Enabled_BSM 0;
BA_ "GenSigTimeoutTime_VDCM" SG_ 205 DriverReq_AxleTrq_Enabled_BSM 0;
BA_ "GenSigTimeoutTime_MPAD" SG_ 205 DrvrIntd_TotalBrk_AxleTorq 0;
BA_ "GenSigTimeoutTime_ADCAM" SG_ 205 DrvrIntd_TotalBrk_AxleTorq 0;
BA_ "GenSigTimeoutTime_CVADAS" SG_ 205 DrvrIntd_TotalBrk_AxleTorq 0;
BA_ "GenSigTimeoutTime_VDCM" SG_ 205 DrvrIntd_TotalBrk_AxleTorq 0;
BA_ "GenSigTimeoutTime_ADCAM" SG_ 205 TotalAxle_Max_Rq_BSM 0;
BA_ "GenSigTimeoutTime_CVADAS" SG_ 205 TotalAxle_Max_Rq_BSM 0;
BA_ "GenSigTimeoutTime_VDCM" SG_ 205 TotalAxle_Max_Rq_BSM 0;
BA_ "GenSigTimeoutTime_MPAD" SG_ 204 Front_AxleTorque_Max 0;
BA_ "GenSigTimeoutTime_ADCAM" SG_ 204 Front_AxleTorque_Max 0;
BA_ "GenSigTimeoutTime_CVADAS" SG_ 204 Front_AxleTorque_Max 0;
BA_ "GenSigTimeoutTime_VDCM" SG_ 204 Front_AxleTorque_Max 0;
BA_ "GenSigStartValue" SG_ 204 Front_AxleTorque_Max 32767;
BA_ "GenSigTimeoutTime_BSM" SG_ 204 Front_AxleTorque_Max 0;
BA_ "GenSigTimeoutTime_BSM2" SG_ 204 Front_AxleTorque_Max 0;
BA_ "GenSigTimeoutTime_CADM" SG_ 204 Front_AxleTorque_Max 0;
BA_ "GenSigTimeoutTime_CVPAM" SG_ 204 Front_AxleTorque_Max 0;
BA_ "GenSigTimeoutTime_ECM" SG_ 204 Front_AxleTorque_Max 0;
BA_ "GenSigTimeoutTime_EPS" SG_ 204 Front_AxleTorque_Max 0;
BA_ "GenSigTimeoutTime_EVCU2" SG_ 204 Front_AxleTorque_Max 0;
BA_ "GenSigTimeoutTime_ORC" SG_ 204 Front_AxleTorque_Max 0;
BA_ "GenSigTimeoutTime_MPAD" SG_ 204 Front_AxleTorque_Min 0;
BA_ "GenSigTimeoutTime_ADCAM" SG_ 204 Front_AxleTorque_Min 0;
BA_ "GenSigTimeoutTime_CVADAS" SG_ 204 Front_AxleTorque_Min 0;
BA_ "GenSigTimeoutTime_VDCM" SG_ 204 Front_AxleTorque_Min 0;
BA_ "GenSigStartValue" SG_ 204 Front_AxleTorque_Min 32767;
BA_ "GenSigTimeoutTime_BSM" SG_ 204 Front_AxleTorque_Min 0;
BA_ "GenSigTimeoutTime_BSM2" SG_ 204 Front_AxleTorque_Min 0;
BA_ "GenSigTimeoutTime_CADM" SG_ 204 Front_AxleTorque_Min 0;
BA_ "GenSigTimeoutTime_CVPAM" SG_ 204 Front_AxleTorque_Min 0;
BA_ "GenSigTimeoutTime_ECM" SG_ 204 Front_AxleTorque_Min 0;
BA_ "GenSigTimeoutTime_EPS" SG_ 204 Front_AxleTorque_Min 0;
BA_ "GenSigTimeoutTime_EVCU2" SG_ 204 Front_AxleTorque_Min 0;
BA_ "GenSigTimeoutTime_ORC" SG_ 204 Front_AxleTorque_Min 0;
BA_ "GenSigTimeoutTime_MPAD" SG_ 204 Rear_AxleTorque_Max 0;
BA_ "GenSigTimeoutTime_ADCAM" SG_ 204 Rear_AxleTorque_Max 0;
BA_ "GenSigTimeoutTime_CVADAS" SG_ 204 Rear_AxleTorque_Max 0;
BA_ "GenSigTimeoutTime_VDCM" SG_ 204 Rear_AxleTorque_Max 0;
BA_ "GenSigStartValue" SG_ 204 Rear_AxleTorque_Max 32767;
BA_ "GenSigTimeoutTime_BSM" SG_ 204 Rear_AxleTorque_Max 0;
BA_ "GenSigTimeoutTime_BSM2" SG_ 204 Rear_AxleTorque_Max 0;
BA_ "GenSigTimeoutTime_CADM" SG_ 204 Rear_AxleTorque_Max 0;
BA_ "GenSigTimeoutTime_CVPAM" SG_ 204 Rear_AxleTorque_Max 0;
BA_ "GenSigTimeoutTime_ECM" SG_ 204 Rear_AxleTorque_Max 0;
BA_ "GenSigTimeoutTime_EPS" SG_ 204 Rear_AxleTorque_Max 0;
BA_ "GenSigTimeoutTime_EVCU2" SG_ 204 Rear_AxleTorque_Max 0;
BA_ "GenSigTimeoutTime_ORC" SG_ 204 Rear_AxleTorque_Max 0;
BA_ "GenSigTimeoutTime_MPAD" SG_ 204 Rear_AxleTorque_Min 0;
BA_ "GenSigTimeoutTime_ADCAM" SG_ 204 Rear_AxleTorque_Min 0;
BA_ "GenSigTimeoutTime_CVADAS" SG_ 204 Rear_AxleTorque_Min 0;
BA_ "GenSigTimeoutTime_VDCM" SG_ 204 Rear_AxleTorque_Min 0;
BA_ "GenSigStartValue" SG_ 204 Rear_AxleTorque_Min 32767;
BA_ "GenSigTimeoutTime_BSM" SG_ 204 Rear_AxleTorque_Min 0;
BA_ "GenSigTimeoutTime_BSM2" SG_ 204 Rear_AxleTorque_Min 0;
BA_ "GenSigTimeoutTime_CADM" SG_ 204 Rear_AxleTorque_Min 0;
BA_ "GenSigTimeoutTime_CVPAM" SG_ 204 Rear_AxleTorque_Min 0;
BA_ "GenSigTimeoutTime_ECM" SG_ 204 Rear_AxleTorque_Min 0;
BA_ "GenSigTimeoutTime_EPS" SG_ 204 Rear_AxleTorque_Min 0;
BA_ "GenSigTimeoutTime_EVCU2" SG_ 204 Rear_AxleTorque_Min 0;
BA_ "GenSigTimeoutTime_ORC" SG_ 204 Rear_AxleTorque_Min 0;
BA_ "GenSigTimeoutTime_MPAD" SG_ 205 FrontAxle_Rq_BSM 0;
BA_ "GenSigTimeoutTime_ADCAM" SG_ 205 FrontAxle_Rq_BSM 0;
BA_ "GenSigTimeoutTime_CVADAS" SG_ 205 FrontAxle_Rq_BSM 0;
BA_ "GenSigTimeoutTime_VDCM" SG_ 205 FrontAxle_Rq_BSM 0;
BA_ "GenSigTimeoutTime_VDCM" SG_ 205 RearAxle_Rq_BSM 0;
BA_ "GenSigTimeoutTime_MPAD" SG_ 205 RearAxle_Rq_BSM 0;
BA_ "GenSigTimeoutTime_ADCAM" SG_ 205 RearAxle_Rq_BSM 0;
BA_ "GenSigTimeoutTime_CVADAS" SG_ 205 RearAxle_Rq_BSM 0;
BA_ "GenSigStartValue" SG_ 205 RearAxle_Rq_BSM 32767;
BA_ "GenSigTimeoutTime_BSM" SG_ 205 RearAxle_Rq_BSM 0;
BA_ "GenSigTimeoutTime_BSM2" SG_ 205 RearAxle_Rq_BSM 0;
BA_ "GenSigTimeoutTime_CADM" SG_ 205 RearAxle_Rq_BSM 0;
BA_ "GenSigTimeoutTime_CVPAM" SG_ 205 RearAxle_Rq_BSM 0;
BA_ "GenSigTimeoutTime_ECM" SG_ 205 RearAxle_Rq_BSM 0;
BA_ "GenSigTimeoutTime_EPS" SG_ 205 RearAxle_Rq_BSM 0;
BA_ "GenSigTimeoutTime_ORC" SG_ 205 RearAxle_Rq_BSM 0;
BA_ "GenSigStartValue" SG_ 205 FrontAxle_Rq_BSM 32767;
BA_ "GenSigTimeoutTime_BSM" SG_ 205 FrontAxle_Rq_BSM 0;
BA_ "GenSigTimeoutTime_BSM2" SG_ 205 FrontAxle_Rq_BSM 0;
BA_ "GenSigTimeoutTime_CADM" SG_ 205 FrontAxle_Rq_BSM 0;
BA_ "GenSigTimeoutTime_CVPAM" SG_ 205 FrontAxle_Rq_BSM 0;
BA_ "GenSigTimeoutTime_ECM" SG_ 205 FrontAxle_Rq_BSM 0;
BA_ "GenSigTimeoutTime_EPS" SG_ 205 FrontAxle_Rq_BSM 0;
BA_ "GenSigTimeoutTime_ORC" SG_ 205 FrontAxle_Rq_BSM 0;
BA_ "GenSigTimeoutTime_CVADAS" SG_ 1472 TRSC_SteeringDamping 0;
BA_ "GenSigStartValue" SG_ 1472 TRSC_SteeringDamping 100;
BA_ "GenSigTimeoutTime_BSM" SG_ 1472 TRSC_SteeringDamping 0;
BA_ "GenSigTimeoutTime_BSM2" SG_ 1472 TRSC_SteeringDamping 0;
BA_ "GenSigTimeoutTime_CADM" SG_ 1472 TRSC_SteeringDamping 0;
BA_ "GenSigTimeoutTime_CVPAM" SG_ 1472 TRSC_SteeringDamping 0;
BA_ "GenSigTimeoutTime_ECM" SG_ 1472 TRSC_SteeringDamping 0;
BA_ "GenSigTimeoutTime_EVCU2" SG_ 1472 TRSC_SteeringDamping 0;
BA_ "GenSigTimeoutTime_ORC" SG_ 1472 TRSC_SteeringDamping 0;
BA_ "GenSigTimeoutTime_CVADAS" SG_ 1472 TRSC_SteeringTorqueReq 0;
BA_ "GenSigSendType" SG_ 1472 TRSC_SteeringTorqueReq 3;
BA_ "GenSigTimeoutTime_BSM" SG_ 1472 TRSC_SteeringTorqueReq 0;
BA_ "GenSigTimeoutTime_BSM2" SG_ 1472 TRSC_SteeringTorqueReq 0;
BA_ "GenSigTimeoutTime_CADM" SG_ 1472 TRSC_SteeringTorqueReq 0;
BA_ "GenSigTimeoutTime_CVPAM" SG_ 1472 TRSC_SteeringTorqueReq 0;
BA_ "GenSigTimeoutTime_ECM" SG_ 1472 TRSC_SteeringTorqueReq 0;
BA_ "GenSigTimeoutTime_EVCU2" SG_ 1472 TRSC_SteeringTorqueReq 0;
BA_ "GenSigTimeoutTime_ORC" SG_ 1472 TRSC_SteeringTorqueReq 0;
BA_ "GenSigTimeoutTime_CVADAS" SG_ 1472 TRSC_SteeringTorqueInfo 0;
BA_ "GenSigStartValue" SG_ 1472 TRSC_SteeringTorqueInfo 1024;
BA_ "GenSigSendType" SG_ 1472 TRSC_SteeringTorqueInfo 3;
BA_ "GenSigTimeoutTime_BSM" SG_ 1472 TRSC_SteeringTorqueInfo 0;
BA_ "GenSigTimeoutTime_BSM2" SG_ 1472 TRSC_SteeringTorqueInfo 0;
BA_ "GenSigTimeoutTime_CADM" SG_ 1472 TRSC_SteeringTorqueInfo 0;
BA_ "GenSigTimeoutTime_CVPAM" SG_ 1472 TRSC_SteeringTorqueInfo 0;
BA_ "GenSigTimeoutTime_ECM" SG_ 1472 TRSC_SteeringTorqueInfo 0;
BA_ "GenSigTimeoutTime_EVCU2" SG_ 1472 TRSC_SteeringTorqueInfo 0;
BA_ "GenSigTimeoutTime_ORC" SG_ 1472 TRSC_SteeringTorqueInfo 0;
BA_ "GenSigTimeoutTime_CVADAS" SG_ 1472 THA_SteeringTorqueInfo 0;
BA_ "GenSigStartValue" SG_ 1472 THA_SteeringTorqueInfo 1024;
BA_ "GenSigSendType" SG_ 1472 THA_SteeringTorqueInfo 3;
BA_ "GenSigTimeoutTime_BSM" SG_ 1472 THA_SteeringTorqueInfo 0;
BA_ "GenSigTimeoutTime_BSM2" SG_ 1472 THA_SteeringTorqueInfo 0;
BA_ "GenSigTimeoutTime_CADM" SG_ 1472 THA_SteeringTorqueInfo 0;
BA_ "GenSigTimeoutTime_ECM" SG_ 1472 THA_SteeringTorqueInfo 0;
BA_ "GenSigTimeoutTime_EVCU2" SG_ 1472 THA_SteeringTorqueInfo 0;
BA_ "GenSigTimeoutTime_ORC" SG_ 1472 THA_SteeringTorqueInfo 0;
BA_ "GenSigTimeoutTime_CVADAS" SG_ 1472 THA_SteeringTorqueReq 0;
BA_ "GenSigSendType" SG_ 1472 THA_SteeringTorqueReq 4;
BA_ "GenSigTimeoutTime_BSM" SG_ 1472 THA_SteeringTorqueReq 0;
BA_ "GenSigTimeoutTime_BSM2" SG_ 1472 THA_SteeringTorqueReq 0;
BA_ "GenSigTimeoutTime_CADM" SG_ 1472 THA_SteeringTorqueReq 0;
BA_ "GenSigTimeoutTime_ECM" SG_ 1472 THA_SteeringTorqueReq 0;
BA_ "GenSigTimeoutTime_EVCU2" SG_ 1472 THA_SteeringTorqueReq 0;
BA_ "GenSigTimeoutTime_ORC" SG_ 1472 THA_SteeringTorqueReq 0;
BA_ "GenSigTimeoutTime_CVADAS" SG_ 1472 THA_SteeringDamping 0;
BA_ "GenSigStartValue" SG_ 1472 THA_SteeringDamping 100;
BA_ "GenSigSendType" SG_ 1472 THA_SteeringDamping 3;
BA_ "GenSigTimeoutTime_BSM" SG_ 1472 THA_SteeringDamping 0;
BA_ "GenSigTimeoutTime_BSM2" SG_ 1472 THA_SteeringDamping 0;
BA_ "GenSigTimeoutTime_CADM" SG_ 1472 THA_SteeringDamping 0;
BA_ "GenSigTimeoutTime_ECM" SG_ 1472 THA_SteeringDamping 0;
BA_ "GenSigTimeoutTime_EVCU2" SG_ 1472 THA_SteeringDamping 0;
BA_ "GenSigTimeoutTime_ORC" SG_ 1472 THA_SteeringDamping 0;
BA_ "GenSigTimeoutTime_MPAD" SG_ 2654486554 CBV_bit0_RepeatMessageRequestBit_1E38401A 0;
BA_ "GenSigTimeoutTime_ADCAM" SG_ 2654486554 CBV_bit0_RepeatMessageRequestBit_1E38401A 0;
BA_ "GenSigTimeoutTime_CVADAS" SG_ 2654486554 CBV_bit0_RepeatMessageRequestBit_1E38401A 0;
BA_ "GenSigTimeoutTime_VDCM" SG_ 2654486554 CBV_bit0_RepeatMessageRequestBit_1E38401A 0;
BA_ "GenSigTimeoutTime_MPAD" SG_ 2654486554 CBV_bit1_1E38401A 0;
BA_ "GenSigTimeoutTime_ADCAM" SG_ 2654486554 CBV_bit1_1E38401A 0;
BA_ "GenSigTimeoutTime_CVADAS" SG_ 2654486554 CBV_bit1_1E38401A 0;
BA_ "GenSigTimeoutTime_VDCM" SG_ 2654486554 CBV_bit1_1E38401A 0;
BA_ "GenSigTimeoutTime_MPAD" SG_ 2654486554 CBV_bit2_1E38401A 0;
BA_ "GenSigTimeoutTime_ADCAM" SG_ 2654486554 CBV_bit2_1E38401A 0;
BA_ "GenSigTimeoutTime_CVADAS" SG_ 2654486554 CBV_bit2_1E38401A 0;
BA_ "GenSigTimeoutTime_VDCM" SG_ 2654486554 CBV_bit2_1E38401A 0;
BA_ "GenSigTimeoutTime_MPAD" SG_ 2654486554 CBV_bit3_NMCoordinatorBit_1E38401A 0;
BA_ "GenSigTimeoutTime_ADCAM" SG_ 2654486554 CBV_bit3_NMCoordinatorBit_1E38401A 0;
BA_ "GenSigTimeoutTime_CVADAS" SG_ 2654486554 CBV_bit3_NMCoordinatorBit_1E38401A 0;
BA_ "GenSigTimeoutTime_VDCM" SG_ 2654486554 CBV_bit3_NMCoordinatorBit_1E38401A 0;
BA_ "GenSigTimeoutTime_MPAD" SG_ 2654486554 CBV_bit4_ActiveWakeupBit_1E38401A 0;
BA_ "GenSigTimeoutTime_ADCAM" SG_ 2654486554 CBV_bit4_ActiveWakeupBit_1E38401A 0;
BA_ "GenSigTimeoutTime_CVADAS" SG_ 2654486554 CBV_bit4_ActiveWakeupBit_1E38401A 0;
BA_ "GenSigTimeoutTime_VDCM" SG_ 2654486554 CBV_bit4_ActiveWakeupBit_1E38401A 0;
BA_ "GenSigTimeoutTime_BSM" SG_ 205 TotalAxle_Max_Rq_BSM 0;
BA_ "GenSigTimeoutTime_BSM2" SG_ 205 TotalAxle_Max_Rq_BSM 0;
BA_ "GenSigTimeoutTime_CADM" SG_ 205 TotalAxle_Max_Rq_BSM 0;
BA_ "GenSigTimeoutTime_CVPAM" SG_ 205 TotalAxle_Max_Rq_BSM 0;
BA_ "GenSigTimeoutTime_EPS" SG_ 205 TotalAxle_Max_Rq_BSM 0;
BA_ "GenSigTimeoutTime_EVCU2" SG_ 205 TotalAxle_Max_Rq_BSM 0;
BA_ "GenSigTimeoutTime_ORC" SG_ 205 TotalAxle_Max_Rq_BSM 0;
BA_ "GenSigTimeoutTime_BSM" SG_ 205 DrvrIntd_TotalBrk_AxleTorq 0;
BA_ "GenSigTimeoutTime_BSM2" SG_ 205 DrvrIntd_TotalBrk_AxleTorq 0;
BA_ "GenSigTimeoutTime_CADM" SG_ 205 DrvrIntd_TotalBrk_AxleTorq 0;
BA_ "GenSigTimeoutTime_CVPAM" SG_ 205 DrvrIntd_TotalBrk_AxleTorq 0;
BA_ "GenSigTimeoutTime_ECM" SG_ 205 DrvrIntd_TotalBrk_AxleTorq 0;
BA_ "GenSigTimeoutTime_EPS" SG_ 205 DrvrIntd_TotalBrk_AxleTorq 0;
BA_ "GenSigTimeoutTime_ORC" SG_ 205 DrvrIntd_TotalBrk_AxleTorq 0;
BA_ "GenSigTimeoutTime_BSM" SG_ 205 DriverReq_AxleTrq_Enabled_BSM 0;
BA_ "GenSigTimeoutTime_BSM2" SG_ 205 DriverReq_AxleTrq_Enabled_BSM 0;
BA_ "GenSigTimeoutTime_CADM" SG_ 205 DriverReq_AxleTrq_Enabled_BSM 0;
BA_ "GenSigTimeoutTime_CVPAM" SG_ 205 DriverReq_AxleTrq_Enabled_BSM 0;
BA_ "GenSigTimeoutTime_EPS" SG_ 205 DriverReq_AxleTrq_Enabled_BSM 0;
BA_ "GenSigTimeoutTime_ORC" SG_ 205 DriverReq_AxleTrq_Enabled_BSM 0;
BA_ "GenSigTimeoutTime_BSM" SG_ 205 Cmnd_TotBrkFrict_AxleTorq 0;
BA_ "GenSigTimeoutTime_BSM2" SG_ 205 Cmnd_TotBrkFrict_AxleTorq 0;
BA_ "GenSigTimeoutTime_CADM" SG_ 205 Cmnd_TotBrkFrict_AxleTorq 0;
BA_ "GenSigTimeoutTime_CVPAM" SG_ 205 Cmnd_TotBrkFrict_AxleTorq 0;
BA_ "GenSigTimeoutTime_ECM" SG_ 205 Cmnd_TotBrkFrict_AxleTorq 0;
BA_ "GenSigTimeoutTime_EPS" SG_ 205 Cmnd_TotBrkFrict_AxleTorq 0;
BA_ "GenSigTimeoutTime_ORC" SG_ 205 Cmnd_TotBrkFrict_AxleTorq 0;
BA_ "GenSigTimeoutTime_BSM" SG_ 205 RearAxle_Max_Rq_BSM 0;
BA_ "GenSigTimeoutTime_BSM2" SG_ 205 RearAxle_Max_Rq_BSM 0;
BA_ "GenSigTimeoutTime_CADM" SG_ 205 RearAxle_Max_Rq_BSM 0;
BA_ "GenSigTimeoutTime_CVPAM" SG_ 205 RearAxle_Max_Rq_BSM 0;
BA_ "GenSigTimeoutTime_ECM" SG_ 205 RearAxle_Max_Rq_BSM 0;
BA_ "GenSigTimeoutTime_EPS" SG_ 205 RearAxle_Max_Rq_BSM 0;
BA_ "GenSigTimeoutTime_ORC" SG_ 205 RearAxle_Max_Rq_BSM 0;
BA_ "GenSigTimeoutTime_BSM" SG_ 205 FrontAxle_Min_Rq_BSM 0;
BA_ "GenSigTimeoutTime_BSM2" SG_ 205 FrontAxle_Min_Rq_BSM 0;
BA_ "GenSigTimeoutTime_CADM" SG_ 205 FrontAxle_Min_Rq_BSM 0;
BA_ "GenSigTimeoutTime_CVPAM" SG_ 205 FrontAxle_Min_Rq_BSM 0;
BA_ "GenSigTimeoutTime_ECM" SG_ 205 FrontAxle_Min_Rq_BSM 0;
BA_ "GenSigTimeoutTime_EPS" SG_ 205 FrontAxle_Min_Rq_BSM 0;
BA_ "GenSigTimeoutTime_ORC" SG_ 205 FrontAxle_Min_Rq_BSM 0;
BA_ "GenSigTimeoutTime_BSM" SG_ 205 FrontAxle_Max_Rq_BSM 0;
BA_ "GenSigTimeoutTime_BSM2" SG_ 205 FrontAxle_Max_Rq_BSM 0;
BA_ "GenSigTimeoutTime_CADM" SG_ 205 FrontAxle_Max_Rq_BSM 0;
BA_ "GenSigTimeoutTime_CVPAM" SG_ 205 FrontAxle_Max_Rq_BSM 0;
BA_ "GenSigTimeoutTime_ECM" SG_ 205 FrontAxle_Max_Rq_BSM 0;
BA_ "GenSigTimeoutTime_EPS" SG_ 205 FrontAxle_Max_Rq_BSM 0;
BA_ "GenSigTimeoutTime_ORC" SG_ 205 FrontAxle_Max_Rq_BSM 0;
BA_ "GenSigTimeoutTime_BSM" SG_ 205 TotalAxle_Min_Rq_BSM 0;
BA_ "GenSigTimeoutTime_BSM2" SG_ 205 TotalAxle_Min_Rq_BSM 0;
BA_ "GenSigTimeoutTime_CADM" SG_ 205 TotalAxle_Min_Rq_BSM 0;
BA_ "GenSigTimeoutTime_CVPAM" SG_ 205 TotalAxle_Min_Rq_BSM 0;
BA_ "GenSigTimeoutTime_EPS" SG_ 205 TotalAxle_Min_Rq_BSM 0;
BA_ "GenSigTimeoutTime_EVCU2" SG_ 205 TotalAxle_Min_Rq_BSM 0;
BA_ "GenSigTimeoutTime_ORC" SG_ 205 TotalAxle_Min_Rq_BSM 0;
BA_ "GenSigTimeoutTime_BSM" SG_ 205 MessageCounter_BRAKE_FD_6 0;
BA_ "GenSigTimeoutTime_BSM2" SG_ 205 MessageCounter_BRAKE_FD_6 0;
BA_ "GenSigTimeoutTime_CADM" SG_ 205 MessageCounter_BRAKE_FD_6 0;
BA_ "GenSigTimeoutTime_CVPAM" SG_ 205 MessageCounter_BRAKE_FD_6 0;
BA_ "GenSigTimeoutTime_EPS" SG_ 205 MessageCounter_BRAKE_FD_6 0;
BA_ "GenSigTimeoutTime_ORC" SG_ 205 MessageCounter_BRAKE_FD_6 0;
BA_ "GenSigTimeoutTime_BSM" SG_ 205 RearAxle_Min_Rq_BSM 0;
BA_ "GenSigTimeoutTime_BSM2" SG_ 205 RearAxle_Min_Rq_BSM 0;
BA_ "GenSigTimeoutTime_CADM" SG_ 205 RearAxle_Min_Rq_BSM 0;
BA_ "GenSigTimeoutTime_CVPAM" SG_ 205 RearAxle_Min_Rq_BSM 0;
BA_ "GenSigTimeoutTime_ECM" SG_ 205 RearAxle_Min_Rq_BSM 0;
BA_ "GenSigTimeoutTime_EPS" SG_ 205 RearAxle_Min_Rq_BSM 0;
BA_ "GenSigTimeoutTime_ORC" SG_ 205 RearAxle_Min_Rq_BSM 0;
BA_ "GenSigTimeoutTime_BSM" SG_ 205 CRC_BRAKE_FD_6 0;
BA_ "GenSigTimeoutTime_BSM2" SG_ 205 CRC_BRAKE_FD_6 0;
BA_ "GenSigTimeoutTime_CADM" SG_ 205 CRC_BRAKE_FD_6 0;
BA_ "GenSigTimeoutTime_CVPAM" SG_ 205 CRC_BRAKE_FD_6 0;
BA_ "GenSigTimeoutTime_EPS" SG_ 205 CRC_BRAKE_FD_6 0;
BA_ "GenSigTimeoutTime_ORC" SG_ 205 CRC_BRAKE_FD_6 0;
BA_ "GenSigTimeoutTime_EVCU2" SG_ 1472 TRSC_SpeedLimit_Req 0;
BA_ "GenSigTimeoutTime_ORC" SG_ 1472 TRSC_SpeedLimit_Req 0;
BA_ "GenSigTimeoutTime_CVADAS" SG_ 1472 TRSC_SpeedLimit_Req 0;
BA_ "GenSigSendType" SG_ 1472 TRSC_SpeedLimit_Req 3;
BA_ "GenSigTimeoutTime_BSM2" SG_ 1472 TRSC_SpeedLimit_Req 0;
BA_ "GenSigTimeoutTime_CADM" SG_ 1472 TRSC_SpeedLimit_Req 0;
BA_ "GenSigTimeoutTime_CVPAM" SG_ 1472 TRSC_SpeedLimit_Req 0;
BA_ "GenSigTimeoutTime_EPS" SG_ 1472 TRSC_SpeedLimit_Req 0;
BA_ "GenSigTimeoutTime_CVADAS" SG_ 1472 THA_STAT 0;
BA_ "GenSigSendType" SG_ 1472 THA_STAT 4;
BA_ "GenSigTimeoutTime_BSM2" SG_ 1472 THA_STAT 0;
BA_ "GenSigTimeoutTime_CADM" SG_ 1472 THA_STAT 0;
BA_ "GenSigTimeoutTime_ORC" SG_ 1472 THA_STAT 0;
BA_ "GenSigStartValue" SG_ 1472 TRSC_STAT 1;
BA_ "GenSigSendType" SG_ 1472 TRSC_STAT 3;
BA_ "GenSigTimeoutTime_BSM2" SG_ 1472 TRSC_STAT 0;
BA_ "GenSigTimeoutTime_CADM" SG_ 1472 TRSC_STAT 0;
BA_ "GenSigTimeoutTime_CVPAM" SG_ 1472 TRSC_STAT 0;
BA_ "GenSigTimeoutTime_EVCU2" SG_ 1472 TRSC_STAT 0;
BA_ "GenSigTimeoutTime_ORC" SG_ 1472 TRSC_STAT 0;
BA_ "GenSigTimeoutTime_CVADAS" SG_ 1472 TRSC_STAT 0;
BA_ "GenSigStartValue" SG_ 1472 TRSC_VehicleStop_Req 3;
BA_ "GenSigSendType" SG_ 1472 TRSC_VehicleStop_Req 3;
BA_ "GenSigTimeoutTime_BSM2" SG_ 1472 TRSC_VehicleStop_Req 0;
BA_ "GenSigTimeoutTime_CADM" SG_ 1472 TRSC_VehicleStop_Req 0;
BA_ "GenSigTimeoutTime_CVPAM" SG_ 1472 TRSC_VehicleStop_Req 0;
BA_ "GenSigTimeoutTime_ECM" SG_ 1472 TRSC_VehicleStop_Req 0;
BA_ "GenSigTimeoutTime_EPS" SG_ 1472 TRSC_VehicleStop_Req 0;
BA_ "GenSigTimeoutTime_EVCU2" SG_ 1472 TRSC_VehicleStop_Req 0;
BA_ "GenSigTimeoutTime_ORC" SG_ 1472 TRSC_VehicleStop_Req 0;
BA_ "GenSigTimeoutTime_CVADAS" SG_ 1472 TRSC_VehicleStop_Req 0;
BA_ "GenSigTimeoutTime_CVADAS" SG_ 1472 THA_SpeedLimit_Req 0;
BA_ "GenSigSendType" SG_ 1472 THA_SpeedLimit_Req 4;
BA_ "GenSigTimeoutTime_BSM2" SG_ 1472 THA_SpeedLimit_Req 0;
BA_ "GenSigTimeoutTime_CADM" SG_ 1472 THA_SpeedLimit_Req 0;
BA_ "GenSigTimeoutTime_EPS" SG_ 1472 THA_SpeedLimit_Req 0;
BA_ "GenSigTimeoutTime_ORC" SG_ 1472 THA_SpeedLimit_Req 0;
BA_ "GenSigTimeoutTime_CVADAS" SG_ 1472 MessageCounter_TRSCM1 0;
BA_ "GenSigTimeoutTime_BSM2" SG_ 1472 MessageCounter_TRSCM1 0;
BA_ "GenSigTimeoutTime_CADM" SG_ 1472 MessageCounter_TRSCM1 0;
BA_ "GenSigTimeoutTime_CVPAM" SG_ 1472 MessageCounter_TRSCM1 0;
BA_ "GenSigTimeoutTime_EVCU2" SG_ 1472 MessageCounter_TRSCM1 0;
BA_ "GenSigTimeoutTime_ORC" SG_ 1472 MessageCounter_TRSCM1 0;
BA_ "GenSigStartValue" SG_ 205 DriverRequested_AxleTrq_BSM 32767;
BA_ "GenSigTimeoutTime_BSM" SG_ 205 DriverRequested_AxleTrq_BSM 0;
BA_ "GenSigTimeoutTime_BSM2" SG_ 205 DriverRequested_AxleTrq_BSM 0;
BA_ "GenSigTimeoutTime_CADM" SG_ 205 DriverRequested_AxleTrq_BSM 0;
BA_ "GenSigTimeoutTime_EPS" SG_ 205 DriverRequested_AxleTrq_BSM 0;
BA_ "GenSigTimeoutTime_ORC" SG_ 205 DriverRequested_AxleTrq_BSM 0;
BA_ "GenSigTimeoutTime_CVADAS" SG_ 1472 CRC_TRSCM1 0;
BA_ "GenSigTimeoutTime_BSM2" SG_ 1472 CRC_TRSCM1 0;
BA_ "GenSigTimeoutTime_CADM" SG_ 1472 CRC_TRSCM1 0;
BA_ "GenSigTimeoutTime_CVPAM" SG_ 1472 CRC_TRSCM1 0;
BA_ "GenSigTimeoutTime_EVCU2" SG_ 1472 CRC_TRSCM1 0;
BA_ "GenSigTimeoutTime_ORC" SG_ 1472 CRC_TRSCM1 0;
BA_ "GenSigTimeoutTime_CVADAS" SG_ 1472 THA_EPB_Req 0;
BA_ "GenSigSendType" SG_ 1472 THA_EPB_Req 4;
BA_ "GenSigTimeoutTime_BSM2" SG_ 1472 THA_EPB_Req 0;
BA_ "GenSigTimeoutTime_CADM" SG_ 1472 THA_EPB_Req 0;
BA_ "GenSigTimeoutTime_ECM" SG_ 1472 THA_EPB_Req 0;
BA_ "GenSigTimeoutTime_EPS" SG_ 1472 THA_EPB_Req 0;
BA_ "GenSigTimeoutTime_EVCU2" SG_ 1472 THA_EPB_Req 0;
BA_ "GenSigTimeoutTime_ORC" SG_ 1472 THA_EPB_Req 0;
BA_ "GenSigTimeoutTime_CVADAS" SG_ 1472 THA_Speed_Limit 0;
BA_ "GenSigSendType" SG_ 1472 THA_Speed_Limit 4;
BA_ "GenSigTimeoutTime_BSM2" SG_ 1472 THA_Speed_Limit 0;
BA_ "GenSigTimeoutTime_CADM" SG_ 1472 THA_Speed_Limit 0;
BA_ "GenSigTimeoutTime_ORC" SG_ 1472 THA_Speed_Limit 0;
BA_ "GenSigStartValue" SG_ 280 TorqueOverlaySteeringReq 1024;
BA_ "GenSigTimeoutTime_BSM" SG_ 280 TorqueOverlaySteeringReq 0;
BA_ "GenSigTimeoutTime_BSM2" SG_ 280 TorqueOverlaySteeringReq 0;
BA_ "GenSigTimeoutTime_CADM" SG_ 280 TorqueOverlaySteeringReq 0;
BA_ "GenSigTimeoutTime_CVPAM" SG_ 280 TorqueOverlaySteeringReq 0;
BA_ "GenSigTimeoutTime_ECM" SG_ 280 TorqueOverlaySteeringReq 0;
BA_ "GenSigTimeoutTime_EVCU2" SG_ 280 TorqueOverlaySteeringReq 0;
BA_ "GenSigTimeoutTime_BSM" SG_ 280 LANE_CHANGE_STATUS 0;
BA_ "GenSigTimeoutTime_BSM2" SG_ 280 LANE_CHANGE_STATUS 0;
BA_ "GenSigTimeoutTime_CADM" SG_ 280 LANE_CHANGE_STATUS 0;
BA_ "GenSigTimeoutTime_CVPAM" SG_ 280 LANE_CHANGE_STATUS 0;
BA_ "GenSigTimeoutTime_ECM" SG_ 280 LANE_CHANGE_STATUS 0;
BA_ "GenSigTimeoutTime_EPS" SG_ 280 LANE_CHANGE_STATUS 0;
BA_ "GenSigTimeoutTime_EVCU2" SG_ 280 LANE_CHANGE_STATUS 0;
BA_ "GenSigTimeoutTime_ADCAM" SG_ 280 LC_Jerk 0;
BA_ "GenSigTimeoutTime_CVADAS" SG_ 280 LC_Jerk 0;
BA_ "GenSigTimeoutTime_VDCM" SG_ 280 LC_Jerk 0;
BA_ "GenSigTimeoutTime_BSM2" SG_ 280 LC_Jerk 0;
BA_ "GenSigTimeoutTime_CADM" SG_ 280 LC_Jerk 0;
BA_ "GenSigTimeoutTime_CVPAM" SG_ 280 LC_Jerk 0;
BA_ "GenSigTimeoutTime_ECM" SG_ 280 LC_Jerk 0;
BA_ "GenSigTimeoutTime_EPS" SG_ 280 LC_Jerk 0;
BA_ "GenSigTimeoutTime_EVCU2" SG_ 280 LC_Jerk 0;
BA_ "GenSigTimeoutTime_ORC" SG_ 280 LC_Jerk 0;
BA_ "GenSigTimeoutTime_BSM" SG_ 280 CADM2_EPSSEC_FAIL 0;
BA_ "GenSigTimeoutTime_BSM2" SG_ 280 CADM2_EPSSEC_FAIL 0;
BA_ "GenSigTimeoutTime_CADM" SG_ 280 CADM2_EPSSEC_FAIL 0;
BA_ "GenSigTimeoutTime_CVPAM" SG_ 280 CADM2_EPSSEC_FAIL 0;
BA_ "GenSigTimeoutTime_ECM" SG_ 280 CADM2_EPSSEC_FAIL 0;
BA_ "GenSigTimeoutTime_EVCU2" SG_ 280 CADM2_EPSSEC_FAIL 0;
BA_ "GenSigTimeoutTime_ORC" SG_ 280 CADM2_EPSSEC_FAIL 0;
BA_ "GenSigTimeoutTime_BSM" SG_ 280 SteeringVibration_Type 0;
BA_ "GenSigTimeoutTime_BSM2" SG_ 280 SteeringVibration_Type 0;
BA_ "GenSigTimeoutTime_CADM" SG_ 280 SteeringVibration_Type 0;
BA_ "GenSigTimeoutTime_CVPAM" SG_ 280 SteeringVibration_Type 0;
BA_ "GenSigTimeoutTime_ECM" SG_ 280 SteeringVibration_Type 0;
BA_ "GenSigTimeoutTime_EVCU2" SG_ 280 SteeringVibration_Type 0;
BA_ "GenSigTimeoutTime_ORC" SG_ 280 SteeringVibration_Type 0;
BA_ "GenSigTimeoutTime_BSM" SG_ 280 SteeringVibration_Rq 0;
BA_ "GenSigTimeoutTime_BSM2" SG_ 280 SteeringVibration_Rq 0;
BA_ "GenSigTimeoutTime_CADM" SG_ 280 SteeringVibration_Rq 0;
BA_ "GenSigTimeoutTime_CVPAM" SG_ 280 SteeringVibration_Rq 0;
BA_ "GenSigTimeoutTime_ECM" SG_ 280 SteeringVibration_Rq 0;
BA_ "GenSigTimeoutTime_EVCU2" SG_ 280 SteeringVibration_Rq 0;
BA_ "GenSigTimeoutTime_ORC" SG_ 280 SteeringVibration_Rq 0;
BA_ "GenSigTimeoutTime_BSM" SG_ 280 LKA_LAT_CTRL_RequestSts 0;
BA_ "GenSigTimeoutTime_BSM2" SG_ 280 LKA_LAT_CTRL_RequestSts 0;
BA_ "GenSigTimeoutTime_CADM" SG_ 280 LKA_LAT_CTRL_RequestSts 0;
BA_ "GenSigTimeoutTime_CVPAM" SG_ 280 LKA_LAT_CTRL_RequestSts 0;
BA_ "GenSigTimeoutTime_ECM" SG_ 280 LKA_LAT_CTRL_RequestSts 0;
BA_ "GenSigTimeoutTime_EVCU2" SG_ 280 LKA_LAT_CTRL_RequestSts 0;
BA_ "GenSigTimeoutTime_ORC" SG_ 280 LKA_LAT_CTRL_RequestSts 0;
BA_ "GenSigTimeoutTime_MPAD" SG_ 280 Object_Dist 0;
BA_ "GenSigTimeoutTime_ADCAM" SG_ 280 Object_Dist 0;
BA_ "GenSigTimeoutTime_CVADAS" SG_ 280 Object_Dist 0;
BA_ "GenSigTimeoutTime_VDCM" SG_ 280 Object_Dist 0;
BA_ "GenSigTimeoutTime_MPAD" SG_ 280 MessageCounter_ADAS_FD_INFO 0;
BA_ "GenSigTimeoutTime_ADCAM" SG_ 280 MessageCounter_ADAS_FD_INFO 0;
BA_ "GenSigTimeoutTime_CVADAS" SG_ 280 MessageCounter_ADAS_FD_INFO 0;
BA_ "GenSigTimeoutTime_VDCM" SG_ 280 MessageCounter_ADAS_FD_INFO 0;
BA_ "GenSigTimeoutTime_ECM" SG_ 280 MessageCounter_ADAS_FD_INFO 0;
BA_ "GenSigTimeoutTime_MPAD" SG_ 280 ACC_DsrSpeedKPH 0;
BA_ "GenSigTimeoutTime_ADCAM" SG_ 280 ACC_DsrSpeedKPH 0;
BA_ "GenSigTimeoutTime_CVADAS" SG_ 280 ACC_DsrSpeedKPH 0;
BA_ "GenSigTimeoutTime_VDCM" SG_ 280 ACC_DsrSpeedKPH 0;
BA_ "GenSigTimeoutTime_MPAD" SG_ 280 CRC_ADAS_FD_INFO 0;
BA_ "GenSigTimeoutTime_ADCAM" SG_ 280 CRC_ADAS_FD_INFO 0;
BA_ "GenSigTimeoutTime_CVADAS" SG_ 280 CRC_ADAS_FD_INFO 0;
BA_ "GenSigTimeoutTime_VDCM" SG_ 280 CRC_ADAS_FD_INFO 0;
BA_ "GenSigTimeoutTime_ECM" SG_ 280 CRC_ADAS_FD_INFO 0;
BA_ "GenSigTimeoutTime_BSM" SG_ 280 PEB_SystemSts 0;
BA_ "GenSigTimeoutTime_BSM2" SG_ 280 PEB_SystemSts 0;
BA_ "GenSigTimeoutTime_CADM" SG_ 280 PEB_SystemSts 0;
BA_ "GenSigTimeoutTime_CVPAM" SG_ 280 PEB_SystemSts 0;
BA_ "GenSigTimeoutTime_ECM" SG_ 280 PEB_SystemSts 0;
BA_ "GenSigTimeoutTime_EPS" SG_ 280 PEB_SystemSts 0;
BA_ "GenSigTimeoutTime_EVCU2" SG_ 280 PEB_SystemSts 0;
BA_ "GenSigTimeoutTime_CADM" SG_ 280 Prefill_Req 0;
BA_ "GenSigTimeoutTime_CVPAM" SG_ 280 Prefill_Req 0;
BA_ "GenSigTimeoutTime_ECM" SG_ 280 Prefill_Req 0;
BA_ "GenSigTimeoutTime_EPS" SG_ 280 Prefill_Req 0;
BA_ "GenSigTimeoutTime_EVCU2" SG_ 280 Prefill_Req 0;
BA_ "GenSigTimeoutTime_ORC" SG_ 280 Prefill_Req 0;
BA_ "GenSigTimeoutTime_BSM" SG_ 280 LANE_CHANGE_SIDE 0;
BA_ "GenSigTimeoutTime_BSM2" SG_ 280 LANE_CHANGE_SIDE 0;
BA_ "GenSigTimeoutTime_CADM" SG_ 280 LANE_CHANGE_SIDE 0;
BA_ "GenSigTimeoutTime_CVPAM" SG_ 280 LANE_CHANGE_SIDE 0;
BA_ "GenSigTimeoutTime_ECM" SG_ 280 LANE_CHANGE_SIDE 0;
BA_ "GenSigTimeoutTime_EPS" SG_ 280 LANE_CHANGE_SIDE 0;
BA_ "GenSigTimeoutTime_EVCU2" SG_ 280 LANE_CHANGE_SIDE 0;
BA_ "GenSigTimeoutTime_BSM" SG_ 280 MRM_STATUS 0;
BA_ "GenSigTimeoutTime_BSM2" SG_ 280 MRM_STATUS 0;
BA_ "GenSigTimeoutTime_CADM" SG_ 280 MRM_STATUS 0;
BA_ "GenSigTimeoutTime_CVPAM" SG_ 280 MRM_STATUS 0;
BA_ "GenSigTimeoutTime_ECM" SG_ 280 MRM_STATUS 0;
BA_ "GenSigTimeoutTime_EPS" SG_ 280 MRM_STATUS 0;
BA_ "GenSigTimeoutTime_CADM" SG_ 280 HAS_Status 0;
BA_ "GenSigTimeoutTime_ECM" SG_ 280 HAS_Status 0;
BA_ "GenSigTimeoutTime_EVCU2" SG_ 280 HAS_Status 0;
BA_ "GenSigTimeoutTime_ORC" SG_ 280 HAS_Status 0;
BA_ "GenSigTimeoutTime_BSM" SG_ 280 ACC_StopStart 0;
BA_ "GenSigTimeoutTime_BSM2" SG_ 280 ACC_StopStart 0;
BA_ "GenSigTimeoutTime_CADM" SG_ 280 ACC_StopStart 0;
BA_ "GenSigTimeoutTime_CVPAM" SG_ 280 ACC_StopStart 0;
BA_ "GenSigTimeoutTime_EPS" SG_ 280 ACC_StopStart 0;
BA_ "GenSigTimeoutTime_EVCU2" SG_ 280 ACC_StopStart 0;
BA_ "GenSigTimeoutTime_ORC" SG_ 280 ACC_StopStart 0;
BA_ "GenSigTimeoutTime_BSM" SG_ 280 AEB_Systemsts 0;
BA_ "GenSigTimeoutTime_BSM2" SG_ 280 AEB_Systemsts 0;
BA_ "GenSigTimeoutTime_CADM" SG_ 280 AEB_Systemsts 0;
BA_ "GenSigTimeoutTime_CVPAM" SG_ 280 AEB_Systemsts 0;
BA_ "GenSigTimeoutTime_ECM" SG_ 280 AEB_Systemsts 0;
BA_ "GenSigTimeoutTime_EPS" SG_ 280 AEB_Systemsts 0;
BA_ "GenSigTimeoutTime_EVCU2" SG_ 280 AEB_Systemsts 0;
BA_ "GenSigTimeoutTime_CADM" SG_ 280 ACC_Systemsts 0;
BA_ "GenSigTimeoutTime_ECM" SG_ 280 ACC_Systemsts 0;
BA_ "GenSigTimeoutTime_EPS" SG_ 280 ACC_Systemsts 0;
BA_ "GenSigTimeoutTime_EVCU2" SG_ 280 ACC_Systemsts 0;
BA_ "GenSigTimeoutTime_BSM" SG_ 280 DDD_SystemSts 0;
BA_ "GenSigTimeoutTime_BSM2" SG_ 280 DDD_SystemSts 0;
BA_ "GenSigTimeoutTime_CADM" SG_ 280 DDD_SystemSts 0;
BA_ "GenSigTimeoutTime_CVPAM" SG_ 280 DDD_SystemSts 0;
BA_ "GenSigTimeoutTime_ECM" SG_ 280 DDD_SystemSts 0;
BA_ "GenSigTimeoutTime_EPS" SG_ 280 DDD_SystemSts 0;
BA_ "GenSigTimeoutTime_EVCU2" SG_ 280 DDD_SystemSts 0;
BA_ "GenSigTimeoutTime_CADM" SG_ 280 AEB_Type 0;
BA_ "GenSigTimeoutTime_CVPAM" SG_ 280 AEB_Type 0;
BA_ "GenSigTimeoutTime_ECM" SG_ 280 AEB_Type 0;
BA_ "GenSigTimeoutTime_EPS" SG_ 280 AEB_Type 0;
BA_ "GenSigTimeoutTime_EVCU2" SG_ 280 AEB_Type 0;
BA_ "GenSigTimeoutTime_BSM" SG_ 280 AEB_Sensitivity_Setting 0;
BA_ "GenSigTimeoutTime_BSM2" SG_ 280 AEB_Sensitivity_Setting 0;
BA_ "GenSigTimeoutTime_CADM" SG_ 280 AEB_Sensitivity_Setting 0;
BA_ "GenSigTimeoutTime_CVPAM" SG_ 280 AEB_Sensitivity_Setting 0;
BA_ "GenSigTimeoutTime_ECM" SG_ 280 AEB_Sensitivity_Setting 0;
BA_ "GenSigTimeoutTime_EPS" SG_ 280 AEB_Sensitivity_Setting 0;
BA_ "GenSigTimeoutTime_EVCU2" SG_ 280 AEB_Sensitivity_Setting 0;
BA_ "GenSigTimeoutTime_ORC" SG_ 280 AEB_Sensitivity_Setting 0;
BA_ "GenSigTimeoutTime_BSM" SG_ 280 DDD_Setting_Avail 0;
BA_ "GenSigTimeoutTime_BSM2" SG_ 280 DDD_Setting_Avail 0;
BA_ "GenSigTimeoutTime_CADM" SG_ 280 DDD_Setting_Avail 0;
BA_ "GenSigTimeoutTime_CVPAM" SG_ 280 DDD_Setting_Avail 0;
BA_ "GenSigTimeoutTime_ECM" SG_ 280 DDD_Setting_Avail 0;
BA_ "GenSigTimeoutTime_EPS" SG_ 280 DDD_Setting_Avail 0;
BA_ "GenSigTimeoutTime_EVCU2" SG_ 280 DDD_Setting_Avail 0;
BA_ "GenSigTimeoutTime_ORC" SG_ 280 DDD_Setting_Avail 0;
BA_ "GenSigTimeoutTime_BSM" SG_ 280 CADM_OpStat 0;
BA_ "GenSigTimeoutTime_BSM2" SG_ 280 CADM_OpStat 0;
BA_ "GenSigTimeoutTime_CADM" SG_ 280 CADM_OpStat 0;
BA_ "GenSigTimeoutTime_CVPAM" SG_ 280 CADM_OpStat 0;
BA_ "GenSigTimeoutTime_ECM" SG_ 280 CADM_OpStat 0;
BA_ "GenSigTimeoutTime_EPS" SG_ 280 CADM_OpStat 0;
BA_ "GenSigTimeoutTime_EVCU2" SG_ 280 CADM_OpStat 0;
BA_ "GenSigTimeoutTime_ORC" SG_ 280 CADM_OpStat 0;
BA_ "GenSigTimeoutTime_BSM" SG_ 280 HAS_OpStat_Prim 0;
BA_ "GenSigTimeoutTime_BSM2" SG_ 280 HAS_OpStat_Prim 0;
BA_ "GenSigTimeoutTime_CADM" SG_ 280 HAS_OpStat_Prim 0;
BA_ "GenSigTimeoutTime_CVPAM" SG_ 280 HAS_OpStat_Prim 0;
BA_ "GenSigTimeoutTime_ECM" SG_ 280 HAS_OpStat_Prim 0;
BA_ "GenSigTimeoutTime_EPS" SG_ 280 HAS_OpStat_Prim 0;
BA_ "GenSigTimeoutTime_EVCU2" SG_ 280 HAS_OpStat_Prim 0;
BA_ "GenSigTimeoutTime_BSM" SG_ 280 HAS_LAT_CTRL_RequestSts 0;
BA_ "GenSigTimeoutTime_BSM2" SG_ 280 HAS_LAT_CTRL_RequestSts 0;
BA_ "GenSigTimeoutTime_CADM" SG_ 280 HAS_LAT_CTRL_RequestSts 0;
BA_ "GenSigTimeoutTime_CVPAM" SG_ 280 HAS_LAT_CTRL_RequestSts 0;
BA_ "GenSigTimeoutTime_ECM" SG_ 280 HAS_LAT_CTRL_RequestSts 0;
BA_ "GenSigTimeoutTime_EVCU2" SG_ 280 HAS_LAT_CTRL_RequestSts 0;
BA_ "GenSigTimeoutTime_ORC" SG_ 280 HAS_LAT_CTRL_RequestSts 0;
BA_ "GenSigTimeoutTime_BSM" SG_ 280 ESCALATION_TYPE 0;
BA_ "GenSigTimeoutTime_BSM2" SG_ 280 ESCALATION_TYPE 0;
BA_ "GenSigTimeoutTime_CADM" SG_ 280 ESCALATION_TYPE 0;
BA_ "GenSigTimeoutTime_CVPAM" SG_ 280 ESCALATION_TYPE 0;
BA_ "GenSigTimeoutTime_ECM" SG_ 280 ESCALATION_TYPE 0;
BA_ "GenSigTimeoutTime_EPS" SG_ 280 ESCALATION_TYPE 0;
BA_ "GenSigTimeoutTime_EVCU2" SG_ 280 ESCALATION_TYPE 0;
BA_ "GenSigTimeoutTime_MPAD" SG_ 280 Intervention 0;
BA_ "GenSigTimeoutTime_ADCAM" SG_ 280 Intervention 0;
BA_ "GenSigTimeoutTime_CVADAS" SG_ 280 Intervention 0;
BA_ "GenSigTimeoutTime_VDCM" SG_ 280 Intervention 0;
BA_ "GenSigTimeoutTime_MPAD" SG_ 280 HIS_Req 0;
BA_ "GenSigTimeoutTime_ADCAM" SG_ 280 HIS_Req 0;
BA_ "GenSigTimeoutTime_CVADAS" SG_ 280 HIS_Req 0;
BA_ "GenSigTimeoutTime_VDCM" SG_ 280 HIS_Req 0;
BA_ "GenSigTimeoutTime_CADM" SG_ 280 HIS_Req 0;
BA_ "GenSigTimeoutTime_CVPAM" SG_ 280 HIS_Req 0;
BA_ "GenSigTimeoutTime_ECM" SG_ 280 HIS_Req 0;
BA_ "GenSigTimeoutTime_BSM2" SG_ 280 GrMax_Rq_ACC 0;
BA_ "GenSigTimeoutTime_CADM" SG_ 280 GrMax_Rq_ACC 0;
BA_ "GenSigTimeoutTime_CVPAM" SG_ 280 GrMax_Rq_ACC 0;
BA_ "GenSigTimeoutTime_ECM" SG_ 280 GrMax_Rq_ACC 0;
BA_ "GenSigTimeoutTime_EPS" SG_ 280 GrMax_Rq_ACC 0;
BA_ "GenSigTimeoutTime_EVCU2" SG_ 280 GrMax_Rq_ACC 0;
BA_ "GenSigTimeoutTime_ORC" SG_ 280 GrMax_Rq_ACC 0;
BA_ "GenSigTimeoutTime_BSM" SG_ 280 CIPV_Fused 0;
BA_ "GenSigTimeoutTime_BSM2" SG_ 280 CIPV_Fused 0;
BA_ "GenSigTimeoutTime_CADM" SG_ 280 CIPV_Fused 0;
BA_ "GenSigTimeoutTime_CVPAM" SG_ 280 CIPV_Fused 0;
BA_ "GenSigTimeoutTime_ECM" SG_ 280 CIPV_Fused 0;
BA_ "GenSigTimeoutTime_EPS" SG_ 280 CIPV_Fused 0;
BA_ "GenSigTimeoutTime_EVCU2" SG_ 280 CIPV_Fused 0;
BA_ "GenSigTimeoutTime_CADM" SG_ 280 Brake_Jerk_Req 0;
BA_ "GenSigTimeoutTime_CVPAM" SG_ 280 Brake_Jerk_Req 0;
BA_ "GenSigTimeoutTime_ECM" SG_ 280 Brake_Jerk_Req 0;
BA_ "GenSigTimeoutTime_EPS" SG_ 280 Brake_Jerk_Req 0;
BA_ "GenSigTimeoutTime_EVCU2" SG_ 280 Brake_Jerk_Req 0;
BA_ "GenSigTimeoutTime_ORC" SG_ 280 Brake_Jerk_Req 0;
BA_ "GenSigTimeoutTime_BSM2" SG_ 280 ACC_Drive_Cmd 0;
BA_ "GenSigTimeoutTime_CADM" SG_ 280 ACC_Drive_Cmd 0;
BA_ "GenSigTimeoutTime_CVPAM" SG_ 280 ACC_Drive_Cmd 0;
BA_ "GenSigTimeoutTime_ECM" SG_ 280 ACC_Drive_Cmd 0;
BA_ "GenSigTimeoutTime_EPS" SG_ 280 ACC_Drive_Cmd 0;
BA_ "GenSigTimeoutTime_EVCU2" SG_ 280 ACC_Drive_Cmd 0;
BA_ "GenSigTimeoutTime_ORC" SG_ 280 ACC_Drive_Cmd 0;
BA_ "GenSigTimeoutTime_EPS" SG_ 280 HIS_Req 0;
BA_ "GenSigTimeoutTime_EVCU2" SG_ 280 HIS_Req 0;
BA_ "GenSigStartValue" SG_ 280 Intervention 4095;
BA_ "GenSigTimeoutTime_CADM" SG_ 280 Intervention 0;
BA_ "GenSigTimeoutTime_CVPAM" SG_ 280 Intervention 0;
BA_ "GenSigTimeoutTime_ECM" SG_ 280 Intervention 0;
BA_ "GenSigTimeoutTime_EPS" SG_ 280 Intervention 0;
BA_ "GenSigTimeoutTime_EVCU2" SG_ 280 Intervention 0;
BA_ "GenSigTimeoutTime_CADM" SG_ 280 CRC_ADAS_FD_INFO 0;
BA_ "GenSigTimeoutTime_EVCU2" SG_ 280 CRC_ADAS_FD_INFO 0;
BA_ "GenSigTimeoutTime_ORC" SG_ 280 CRC_ADAS_FD_INFO 0;
BA_ "GenSigStartValue" SG_ 280 ACC_DsrSpeedKPH 255;
BA_ "GenSigTimeoutTime_BSM" SG_ 280 ACC_DsrSpeedKPH 0;
BA_ "GenSigTimeoutTime_BSM2" SG_ 280 ACC_DsrSpeedKPH 0;
BA_ "GenSigTimeoutTime_CADM" SG_ 280 ACC_DsrSpeedKPH 0;
BA_ "GenSigTimeoutTime_CVPAM" SG_ 280 ACC_DsrSpeedKPH 0;
BA_ "GenSigTimeoutTime_ECM" SG_ 280 ACC_DsrSpeedKPH 0;
BA_ "GenSigTimeoutTime_EPS" SG_ 280 ACC_DsrSpeedKPH 0;
BA_ "GenSigTimeoutTime_ORC" SG_ 280 ACC_DsrSpeedKPH 0;
BA_ "GenSigTimeoutTime_CADM" SG_ 280 MessageCounter_ADAS_FD_INFO 0;
BA_ "GenSigTimeoutTime_EVCU2" SG_ 280 MessageCounter_ADAS_FD_INFO 0;
BA_ "GenSigTimeoutTime_ORC" SG_ 280 MessageCounter_ADAS_FD_INFO 0;
BA_ "GenSigStartValue" SG_ 280 Object_Dist 255;
BA_ "GenSigTimeoutTime_BSM2" SG_ 280 Object_Dist 0;
BA_ "GenSigTimeoutTime_CADM" SG_ 280 Object_Dist 0;
BA_ "GenSigTimeoutTime_CVPAM" SG_ 280 Object_Dist 0;
BA_ "GenSigTimeoutTime_ECM" SG_ 280 Object_Dist 0;
BA_ "GenSigTimeoutTime_EPS" SG_ 280 Object_Dist 0;
BA_ "GenSigTimeoutTime_ADCAM" SG_ 1156 ABSFailSts_B2 0;
BA_ "GenSigTimeoutTime_CVADAS" SG_ 1156 ABSFailSts_B2 0;
BA_ "GenSigSendType" SG_ 1156 ABSFailSts_B2 4;
BA_ "GenSigTimeoutTime_BSM" SG_ 1156 ABSFailSts_B2 0;
BA_ "GenSigTimeoutTime_BSM2" SG_ 1156 ABSFailSts_B2 0;
BA_ "GenSigTimeoutTime_CVPAM" SG_ 1156 ABSFailSts_B2 0;
BA_ "GenSigTimeoutTime_ECM" SG_ 1156 ABSFailSts_B2 0;
BA_ "GenSigTimeoutTime_EPS" SG_ 1156 ABSFailSts_B2 0;
BA_ "GenSigTimeoutTime_EVCU2" SG_ 1156 ABSFailSts_B2 0;
BA_ "GenSigTimeoutTime_ORC" SG_ 1156 ABSFailSts_B2 0;
BA_ "GenSigSendType" SG_ 1156 BSM2_FaultSts 4;
BA_ "GenSigTimeoutTime_BSM" SG_ 1156 BSM2_FaultSts 0;
BA_ "GenSigTimeoutTime_BSM2" SG_ 1156 BSM2_FaultSts 0;
BA_ "GenSigTimeoutTime_CVPAM" SG_ 1156 BSM2_FaultSts 0;
BA_ "GenSigTimeoutTime_ECM" SG_ 1156 BSM2_FaultSts 0;
BA_ "GenSigTimeoutTime_EPS" SG_ 1156 BSM2_FaultSts 0;
BA_ "GenSigTimeoutTime_EVCU2" SG_ 1156 BSM2_FaultSts 0;
BA_ "GenSigTimeoutTime_ORC" SG_ 1156 BSM2_FaultSts 0;
BA_ "GenSigTimeoutTime_MPAD" SG_ 1156 CRC_BRAKE2_3 0;
BA_ "GenSigTimeoutTime_ADCAM" SG_ 1156 CRC_BRAKE2_3 0;
BA_ "GenSigTimeoutTime_CVADAS" SG_ 1156 CRC_BRAKE2_3 0;
BA_ "GenSigTimeoutTime_BSM" SG_ 1156 CRC_BRAKE2_3 0;
BA_ "GenSigTimeoutTime_BSM2" SG_ 1156 CRC_BRAKE2_3 0;
BA_ "GenSigTimeoutTime_CVPAM" SG_ 1156 CRC_BRAKE2_3 0;
BA_ "GenSigTimeoutTime_ECM" SG_ 1156 CRC_BRAKE2_3 0;
BA_ "GenSigTimeoutTime_EPS" SG_ 1156 CRC_BRAKE2_3 0;
BA_ "GenSigTimeoutTime_EVCU2" SG_ 1156 CRC_BRAKE2_3 0;
BA_ "GenSigTimeoutTime_MPAD" SG_ 1156 MessageCounter_BRAKE2_3 0;
BA_ "GenSigTimeoutTime_ADCAM" SG_ 1156 MessageCounter_BRAKE2_3 0;
BA_ "GenSigTimeoutTime_CVADAS" SG_ 1156 MessageCounter_BRAKE2_3 0;
BA_ "GenSigTimeoutTime_BSM" SG_ 1156 MessageCounter_BRAKE2_3 0;
BA_ "GenSigTimeoutTime_BSM2" SG_ 1156 MessageCounter_BRAKE2_3 0;
BA_ "GenSigTimeoutTime_CVPAM" SG_ 1156 MessageCounter_BRAKE2_3 0;
BA_ "GenSigTimeoutTime_ECM" SG_ 1156 MessageCounter_BRAKE2_3 0;
BA_ "GenSigTimeoutTime_EPS" SG_ 1156 MessageCounter_BRAKE2_3 0;
BA_ "GenSigTimeoutTime_EVCU2" SG_ 1156 MessageCounter_BRAKE2_3 0;
BA_ "GenSigTimeoutTime_ADCAM" SG_ 1156 RollsModeAct_B2 0;
BA_ "GenSigTimeoutTime_CVADAS" SG_ 1156 RollsModeAct_B2 0;
BA_ "GenSigSendType" SG_ 1156 RollsModeAct_B2 4;
BA_ "GenSigTimeoutTime_BSM" SG_ 1156 RollsModeAct_B2 0;
BA_ "GenSigTimeoutTime_BSM2" SG_ 1156 RollsModeAct_B2 0;
BA_ "GenSigTimeoutTime_CVPAM" SG_ 1156 RollsModeAct_B2 0;
BA_ "GenSigTimeoutTime_ECM" SG_ 1156 RollsModeAct_B2 0;
BA_ "GenSigTimeoutTime_EPS" SG_ 1156 RollsModeAct_B2 0;
BA_ "GenSigTimeoutTime_EVCU2" SG_ 1156 RollsModeAct_B2 0;
BA_ "GenSigTimeoutTime_ORC" SG_ 1156 RollsModeAct_B2 0;
BA_ "GenSigTimeoutTime_ADCAM" SG_ 726 CRC_CVPAM_FD_Data 0;
BA_ "GenSigTimeoutTime_CVADAS" SG_ 726 CRC_CVPAM_FD_Data 0;
BA_ "GenSigTimeoutTime_ADCAM" SG_ 726 MAC_CVPAM_FD_Data 0;
BA_ "GenSigTimeoutTime_CVADAS" SG_ 726 MAC_CVPAM_FD_Data 0;
BA_ "GenSigTimeoutTime_ADCAM" SG_ 726 MessageCounter_CVPAM_FD_Data 0;
BA_ "GenSigTimeoutTime_CVADAS" SG_ 726 MessageCounter_CVPAM_FD_Data 0;
BA_ "GenSigTimeoutTime_ADCAM" SG_ 726 PA_Front_Sensor_Det_Health 0;
BA_ "GenSigTimeoutTime_CVADAS" SG_ 726 PA_Front_Sensor_Det_Health 0;
BA_ "GenSigTimeoutTime_ADCAM" SG_ 726 PA_Obj1_Angle 0;
BA_ "GenSigTimeoutTime_CVADAS" SG_ 726 PA_Obj1_Angle 0;
BA_ "GenSigTimeoutTime_ADCAM" SG_ 726 PA_Obj1_Angle_2 0;
BA_ "GenSigTimeoutTime_CVADAS" SG_ 726 PA_Obj1_Angle_2 0;
BA_ "GenSigTimeoutTime_ADCAM" SG_ 726 PA_Obj1_Conf 0;
BA_ "GenSigTimeoutTime_CVADAS" SG_ 726 PA_Obj1_Conf 0;
BA_ "GenSigTimeoutTime_ADCAM" SG_ 726 PA_Obj1_Range 0;
BA_ "GenSigTimeoutTime_CVADAS" SG_ 726 PA_Obj1_Range 0;
BA_ "GenSigTimeoutTime_ADCAM" SG_ 726 PA_Obj1_Range_2 0;
BA_ "GenSigTimeoutTime_CVADAS" SG_ 726 PA_Obj1_Range_2 0;
BA_ "GenSigTimeoutTime_ADCAM" SG_ 726 PA_Obj1_Type 0;
BA_ "GenSigTimeoutTime_CVADAS" SG_ 726 PA_Obj1_Type 0;
BA_ "GenSigTimeoutTime_ADCAM" SG_ 726 PA_Obj2_Angle 0;
BA_ "GenSigTimeoutTime_CVADAS" SG_ 726 PA_Obj2_Angle 0;
BA_ "GenSigTimeoutTime_ADCAM" SG_ 726 PA_Obj2_Angle_2 0;
BA_ "GenSigTimeoutTime_CVADAS" SG_ 726 PA_Obj2_Angle_2 0;
BA_ "GenSigTimeoutTime_ADCAM" SG_ 726 PA_Obj2_Conf 0;
BA_ "GenSigTimeoutTime_CVADAS" SG_ 726 PA_Obj2_Conf 0;
BA_ "GenSigTimeoutTime_ADCAM" SG_ 726 PA_Obj2_Range 0;
BA_ "GenSigTimeoutTime_CVADAS" SG_ 726 PA_Obj2_Range 0;
BA_ "GenSigTimeoutTime_ADCAM" SG_ 726 PA_Obj2_Range_2 0;
BA_ "GenSigTimeoutTime_CVADAS" SG_ 726 PA_Obj2_Range_2 0;
BA_ "GenSigTimeoutTime_ADCAM" SG_ 726 PA_Obj2_Type 0;
BA_ "GenSigTimeoutTime_CVADAS" SG_ 726 PA_Obj2_Type 0;
BA_ "GenSigTimeoutTime_ADCAM" SG_ 726 PA_Obj3_Angle 0;
BA_ "GenSigTimeoutTime_CVADAS" SG_ 726 PA_Obj3_Angle 0;
BA_ "GenSigTimeoutTime_ADCAM" SG_ 726 PA_Obj3_Angle_2 0;
BA_ "GenSigTimeoutTime_CVADAS" SG_ 726 PA_Obj3_Angle_2 0;
BA_ "GenSigTimeoutTime_ADCAM" SG_ 726 PA_Obj3_Conf 0;
BA_ "GenSigTimeoutTime_CVADAS" SG_ 726 PA_Obj3_Conf 0;
BA_ "GenSigTimeoutTime_ADCAM" SG_ 726 PA_Obj3_Range 0;
BA_ "GenSigTimeoutTime_CVADAS" SG_ 726 PA_Obj3_Range 0;
BA_ "GenSigTimeoutTime_ADCAM" SG_ 726 PA_Obj3_Range_2 0;
BA_ "GenSigTimeoutTime_CVADAS" SG_ 726 PA_Obj3_Range_2 0;
BA_ "GenSigTimeoutTime_ADCAM" SG_ 726 PA_Obj3_Type 0;
BA_ "GenSigTimeoutTime_CVADAS" SG_ 726 PA_Obj3_Type 0;
BA_ "GenSigTimeoutTime_ADCAM" SG_ 726 PA_Obj4_Angle 0;
BA_ "GenSigTimeoutTime_CVADAS" SG_ 726 PA_Obj4_Angle 0;
BA_ "GenSigTimeoutTime_BSM" SG_ 726 PA_Obj4_Angle 0;
BA_ "GenSigTimeoutTime_BSM2" SG_ 726 PA_Obj4_Angle 0;
BA_ "GenSigTimeoutTime_CVPAM" SG_ 726 PA_Obj4_Angle 0;
BA_ "GenSigTimeoutTime_ECM" SG_ 726 PA_Obj4_Angle 0;
BA_ "GenSigTimeoutTime_EPS" SG_ 726 PA_Obj4_Angle 0;
BA_ "GenSigTimeoutTime_EVCU2" SG_ 726 PA_Obj4_Angle 0;
BA_ "GenSigTimeoutTime_ORC" SG_ 726 PA_Obj4_Angle 0;
BA_ "GenSigTimeoutTime_BSM2" SG_ 726 PA_Obj4_Angle_2 0;
BA_ "GenSigTimeoutTime_CVPAM" SG_ 726 PA_Obj4_Angle_2 0;
BA_ "GenSigTimeoutTime_ECM" SG_ 726 PA_Obj4_Angle_2 0;
BA_ "GenSigTimeoutTime_EPS" SG_ 726 PA_Obj4_Angle_2 0;
BA_ "GenSigTimeoutTime_EVCU2" SG_ 726 PA_Obj4_Angle_2 0;
BA_ "GenSigTimeoutTime_ORC" SG_ 726 PA_Obj4_Angle_2 0;
BA_ "GenSigTimeoutTime_ADCAM" SG_ 726 PA_Obj4_Angle_2 0;
BA_ "GenSigTimeoutTime_CVADAS" SG_ 726 PA_Obj4_Angle_2 0;
BA_ "GenSigTimeoutTime_BSM" SG_ 726 PA_Obj4_Angle_2 0;
BA_ "GenSigTimeoutTime_BSM" SG_ 726 PA_Obj4_Conf 0;
BA_ "GenSigTimeoutTime_BSM2" SG_ 726 PA_Obj4_Conf 0;
BA_ "GenSigTimeoutTime_CVPAM" SG_ 726 PA_Obj4_Conf 0;
BA_ "GenSigTimeoutTime_ECM" SG_ 726 PA_Obj4_Conf 0;
BA_ "GenSigTimeoutTime_EPS" SG_ 726 PA_Obj4_Conf 0;
BA_ "GenSigTimeoutTime_EVCU2" SG_ 726 PA_Obj4_Conf 0;
BA_ "GenSigTimeoutTime_ORC" SG_ 726 PA_Obj4_Conf 0;
BA_ "GenSigTimeoutTime_ADCAM" SG_ 726 PA_Obj4_Conf 0;
BA_ "GenSigTimeoutTime_CVADAS" SG_ 726 PA_Obj4_Conf 0;
BA_ "GenSigTimeoutTime_BSM" SG_ 726 PA_Obj4_Range 0;
BA_ "GenSigTimeoutTime_BSM2" SG_ 726 PA_Obj4_Range 0;
BA_ "GenSigTimeoutTime_CVPAM" SG_ 726 PA_Obj4_Range 0;
BA_ "GenSigTimeoutTime_ECM" SG_ 726 PA_Obj4_Range 0;
BA_ "GenSigTimeoutTime_EPS" SG_ 726 PA_Obj4_Range 0;
BA_ "GenSigTimeoutTime_EVCU2" SG_ 726 PA_Obj4_Range 0;
BA_ "GenSigTimeoutTime_ORC" SG_ 726 PA_Obj4_Range 0;
BA_ "GenSigTimeoutTime_ADCAM" SG_ 726 PA_Obj4_Range 0;
BA_ "GenSigTimeoutTime_CVADAS" SG_ 726 PA_Obj4_Range 0;
BA_ "GenSigTimeoutTime_BSM" SG_ 726 PA_Obj4_Range_2 0;
BA_ "GenSigTimeoutTime_BSM2" SG_ 726 PA_Obj4_Range_2 0;
BA_ "GenSigTimeoutTime_CVPAM" SG_ 726 PA_Obj4_Range_2 0;
BA_ "GenSigTimeoutTime_ECM" SG_ 726 PA_Obj4_Range_2 0;
BA_ "GenSigTimeoutTime_EPS" SG_ 726 PA_Obj4_Range_2 0;
BA_ "GenSigTimeoutTime_EVCU2" SG_ 726 PA_Obj4_Range_2 0;
BA_ "GenSigTimeoutTime_ORC" SG_ 726 PA_Obj4_Range_2 0;
BA_ "GenSigTimeoutTime_ADCAM" SG_ 726 PA_Obj4_Range_2 0;
BA_ "GenSigTimeoutTime_CVADAS" SG_ 726 PA_Obj4_Range_2 0;
BA_ "GenSigTimeoutTime_BSM" SG_ 726 PA_Obj4_Type 0;
BA_ "GenSigTimeoutTime_ADCAM" SG_ 726 PA_Obj4_Type 0;
BA_ "GenSigTimeoutTime_CVADAS" SG_ 726 PA_Obj4_Type 0;
BA_ "GenSigTimeoutTime_ADCAM" SG_ 726 PA_Obj5_Angle 0;
BA_ "GenSigTimeoutTime_CVADAS" SG_ 726 PA_Obj5_Angle 0;
BA_ "GenSigTimeoutTime_BSM" SG_ 726 PA_Obj5_Angle 0;
BA_ "GenSigTimeoutTime_BSM2" SG_ 726 PA_Obj5_Angle 0;
BA_ "GenSigTimeoutTime_CVPAM" SG_ 726 PA_Obj5_Angle 0;
BA_ "GenSigTimeoutTime_ECM" SG_ 726 PA_Obj5_Angle 0;
BA_ "GenSigTimeoutTime_EPS" SG_ 726 PA_Obj5_Angle 0;
BA_ "GenSigTimeoutTime_EVCU2" SG_ 726 PA_Obj5_Angle 0;
BA_ "GenSigTimeoutTime_ORC" SG_ 726 PA_Obj5_Angle 0;
BA_ "GenSigTimeoutTime_ADCAM" SG_ 726 PA_Obj5_Angle_2 0;
BA_ "GenSigTimeoutTime_CVADAS" SG_ 726 PA_Obj5_Angle_2 0;
BA_ "GenSigTimeoutTime_BSM" SG_ 726 PA_Obj5_Angle_2 0;
BA_ "GenSigTimeoutTime_BSM2" SG_ 726 PA_Obj5_Angle_2 0;
BA_ "GenSigTimeoutTime_CVPAM" SG_ 726 PA_Obj5_Angle_2 0;
BA_ "GenSigTimeoutTime_ECM" SG_ 726 PA_Obj5_Angle_2 0;
BA_ "GenSigTimeoutTime_EPS" SG_ 726 PA_Obj5_Angle_2 0;
BA_ "GenSigTimeoutTime_EVCU2" SG_ 726 PA_Obj5_Angle_2 0;
BA_ "GenSigTimeoutTime_ORC" SG_ 726 PA_Obj5_Angle_2 0;
BA_ "GenSigTimeoutTime_ADCAM" SG_ 726 PA_Obj5_Conf 0;
BA_ "GenSigTimeoutTime_CVADAS" SG_ 726 PA_Obj5_Conf 0;
BA_ "GenSigTimeoutTime_BSM" SG_ 726 PA_Obj5_Conf 0;
BA_ "GenSigTimeoutTime_BSM2" SG_ 726 PA_Obj5_Conf 0;
BA_ "GenSigTimeoutTime_CVPAM" SG_ 726 PA_Obj5_Conf 0;
BA_ "GenSigTimeoutTime_ECM" SG_ 726 PA_Obj5_Conf 0;
BA_ "GenSigTimeoutTime_EPS" SG_ 726 PA_Obj5_Conf 0;
BA_ "GenSigTimeoutTime_EVCU2" SG_ 726 PA_Obj5_Conf 0;
BA_ "GenSigTimeoutTime_ORC" SG_ 726 PA_Obj5_Conf 0;
BA_ "GenSigTimeoutTime_ADCAM" SG_ 726 PA_Obj5_Range 0;
BA_ "GenSigTimeoutTime_CVADAS" SG_ 726 PA_Obj5_Range 0;
BA_ "GenSigTimeoutTime_BSM" SG_ 726 PA_Obj5_Range 0;
BA_ "GenSigTimeoutTime_BSM2" SG_ 726 PA_Obj5_Range 0;
BA_ "GenSigTimeoutTime_CVPAM" SG_ 726 PA_Obj5_Range 0;
BA_ "GenSigTimeoutTime_ECM" SG_ 726 PA_Obj5_Range 0;
BA_ "GenSigTimeoutTime_EPS" SG_ 726 PA_Obj5_Range 0;
BA_ "GenSigTimeoutTime_EVCU2" SG_ 726 PA_Obj5_Range 0;
BA_ "GenSigTimeoutTime_ORC" SG_ 726 PA_Obj5_Range 0;
BA_ "GenSigTimeoutTime_ADCAM" SG_ 726 PA_Obj5_Range_2 0;
BA_ "GenSigTimeoutTime_CVADAS" SG_ 726 PA_Obj5_Range_2 0;
BA_ "GenSigTimeoutTime_BSM" SG_ 726 PA_Obj5_Range_2 0;
BA_ "GenSigTimeoutTime_BSM2" SG_ 726 PA_Obj5_Range_2 0;
BA_ "GenSigTimeoutTime_CVPAM" SG_ 726 PA_Obj5_Range_2 0;
BA_ "GenSigTimeoutTime_ECM" SG_ 726 PA_Obj5_Range_2 0;
BA_ "GenSigTimeoutTime_EPS" SG_ 726 PA_Obj5_Range_2 0;
BA_ "GenSigTimeoutTime_EVCU2" SG_ 726 PA_Obj5_Range_2 0;
BA_ "GenSigTimeoutTime_ORC" SG_ 726 PA_Obj5_Range_2 0;
BA_ "GenSigTimeoutTime_ADCAM" SG_ 726 PA_Obj5_Type 0;
BA_ "GenSigTimeoutTime_CVADAS" SG_ 726 PA_Obj5_Type 0;
BA_ "GenSigTimeoutTime_BSM" SG_ 726 PA_Obj5_Type 0;
BA_ "GenSigTimeoutTime_BSM2" SG_ 726 PA_Obj5_Type 0;
BA_ "GenSigTimeoutTime_CVPAM" SG_ 726 PA_Obj5_Type 0;
BA_ "GenSigTimeoutTime_ECM" SG_ 726 PA_Obj5_Type 0;
BA_ "GenSigTimeoutTime_EPS" SG_ 726 PA_Obj5_Type 0;
BA_ "GenSigTimeoutTime_EVCU2" SG_ 726 PA_Obj5_Type 0;
BA_ "GenSigTimeoutTime_ORC" SG_ 726 PA_Obj5_Type 0;
BA_ "GenSigTimeoutTime_ADCAM" SG_ 726 PA_Obj6_Angle 0;
BA_ "GenSigTimeoutTime_CVADAS" SG_ 726 PA_Obj6_Angle 0;
BA_ "GenSigTimeoutTime_ADCAM" SG_ 726 PA_Obj6_Angle_2 0;
BA_ "GenSigTimeoutTime_CVADAS" SG_ 726 PA_Obj6_Angle_2 0;
BA_ "GenSigTimeoutTime_ADCAM" SG_ 726 PA_Obj6_Type 0;
BA_ "GenSigTimeoutTime_CVADAS" SG_ 726 PA_Obj6_Type 0;
BA_ "GenSigTimeoutTime_ADCAM" SG_ 726 PA_Obj6_Conf 0;
BA_ "GenSigTimeoutTime_CVADAS" SG_ 726 PA_Obj6_Conf 0;
BA_ "GenSigTimeoutTime_ADCAM" SG_ 726 PA_Obj6_Range 0;
BA_ "GenSigTimeoutTime_CVADAS" SG_ 726 PA_Obj6_Range 0;
BA_ "GenSigTimeoutTime_ADCAM" SG_ 726 PA_Obj6_Range_2 0;
BA_ "GenSigTimeoutTime_CVADAS" SG_ 726 PA_Obj6_Range_2 0;
BA_ "GenSigTimeoutTime_ADCAM" SG_ 726 Cntr_CVPAM_FD_Data 0;
BA_ "GenSigTimeoutTime_CVADAS" SG_ 726 Cntr_CVPAM_FD_Data 0;
BA_ "GenSigTimeoutTime_ADCAM" SG_ 726 Reserved_for_functional_safety_2D6 0;
BA_ "GenSigTimeoutTime_CVADAS" SG_ 726 Reserved_for_functional_safety_2D6 0;
BA_ "GenSigTimeoutTime_BSM" SG_ 726 Reserved_for_functional_safety_2D6 0;
BA_ "GenSigTimeoutTime_BSM2" SG_ 726 Reserved_for_functional_safety_2D6 0;
BA_ "GenSigTimeoutTime_CVPAM" SG_ 726 Reserved_for_functional_safety_2D6 0;
BA_ "GenSigTimeoutTime_ECM" SG_ 726 Reserved_for_functional_safety_2D6 0;
BA_ "GenSigTimeoutTime_EPS" SG_ 726 Reserved_for_functional_safety_2D6 0;
BA_ "GenSigTimeoutTime_EVCU2" SG_ 726 Reserved_for_functional_safety_2D6 0;
BA_ "GenSigTimeoutTime_ORC" SG_ 726 Reserved_for_functional_safety_2D6 0;
BA_ "GenSigTimeoutTime_BSM" SG_ 726 Cntr_CVPAM_FD_Data 0;
BA_ "GenSigTimeoutTime_BSM2" SG_ 726 Cntr_CVPAM_FD_Data 0;
BA_ "GenSigTimeoutTime_CVPAM" SG_ 726 Cntr_CVPAM_FD_Data 0;
BA_ "GenSigTimeoutTime_ECM" SG_ 726 Cntr_CVPAM_FD_Data 0;
BA_ "GenSigTimeoutTime_EPS" SG_ 726 Cntr_CVPAM_FD_Data 0;
BA_ "GenSigTimeoutTime_EVCU2" SG_ 726 Cntr_CVPAM_FD_Data 0;
BA_ "GenSigTimeoutTime_ORC" SG_ 726 Cntr_CVPAM_FD_Data 0;
BA_ "GenSigTimeoutTime_BSM" SG_ 726 PA_Obj6_Range_2 0;
BA_ "GenSigTimeoutTime_BSM2" SG_ 726 PA_Obj6_Range_2 0;
BA_ "GenSigTimeoutTime_CVPAM" SG_ 726 PA_Obj6_Range_2 0;
BA_ "GenSigTimeoutTime_ECM" SG_ 726 PA_Obj6_Range_2 0;
BA_ "GenSigTimeoutTime_EPS" SG_ 726 PA_Obj6_Range_2 0;
BA_ "GenSigTimeoutTime_EVCU2" SG_ 726 PA_Obj6_Range_2 0;
BA_ "GenSigTimeoutTime_ORC" SG_ 726 PA_Obj6_Range_2 0;
BA_ "GenSigTimeoutTime_BSM" SG_ 726 PA_Obj6_Range 0;
BA_ "GenSigTimeoutTime_BSM2" SG_ 726 PA_Obj6_Range 0;
BA_ "GenSigTimeoutTime_CVPAM" SG_ 726 PA_Obj6_Range 0;
BA_ "GenSigTimeoutTime_ECM" SG_ 726 PA_Obj6_Range 0;
BA_ "GenSigTimeoutTime_EPS" SG_ 726 PA_Obj6_Range 0;
BA_ "GenSigTimeoutTime_EVCU2" SG_ 726 PA_Obj6_Range 0;
BA_ "GenSigTimeoutTime_ORC" SG_ 726 PA_Obj6_Range 0;
BA_ "GenSigTimeoutTime_BSM" SG_ 726 PA_Obj6_Conf 0;
BA_ "GenSigTimeoutTime_BSM2" SG_ 726 PA_Obj6_Conf 0;
BA_ "GenSigTimeoutTime_CVPAM" SG_ 726 PA_Obj6_Conf 0;
BA_ "GenSigTimeoutTime_ECM" SG_ 726 PA_Obj6_Conf 0;
BA_ "GenSigTimeoutTime_EPS" SG_ 726 PA_Obj6_Conf 0;
BA_ "GenSigTimeoutTime_EVCU2" SG_ 726 PA_Obj6_Conf 0;
BA_ "GenSigTimeoutTime_ORC" SG_ 726 PA_Obj6_Conf 0;
BA_ "GenSigTimeoutTime_BSM" SG_ 726 PA_Obj6_Angle_2 0;
BA_ "GenSigTimeoutTime_BSM2" SG_ 726 PA_Obj6_Angle_2 0;
BA_ "GenSigTimeoutTime_CVPAM" SG_ 726 PA_Obj6_Angle_2 0;
BA_ "GenSigTimeoutTime_ECM" SG_ 726 PA_Obj6_Angle_2 0;
BA_ "GenSigTimeoutTime_EPS" SG_ 726 PA_Obj6_Angle_2 0;
BA_ "GenSigTimeoutTime_EVCU2" SG_ 726 PA_Obj6_Angle_2 0;
BA_ "GenSigTimeoutTime_ORC" SG_ 726 PA_Obj6_Angle_2 0;
BA_ "GenSigTimeoutTime_BSM" SG_ 726 PA_Obj6_Angle 0;
BA_ "GenSigTimeoutTime_BSM2" SG_ 726 PA_Obj6_Angle 0;
BA_ "GenSigTimeoutTime_CVPAM" SG_ 726 PA_Obj6_Angle 0;
BA_ "GenSigTimeoutTime_ECM" SG_ 726 PA_Obj6_Angle 0;
BA_ "GenSigTimeoutTime_EPS" SG_ 726 PA_Obj6_Angle 0;
BA_ "GenSigTimeoutTime_EVCU2" SG_ 726 PA_Obj6_Angle 0;
BA_ "GenSigTimeoutTime_ORC" SG_ 726 PA_Obj6_Angle 0;
BA_ "GenSigTimeoutTime_BSM2" SG_ 726 PA_Obj4_Type 0;
BA_ "GenSigTimeoutTime_CVPAM" SG_ 726 PA_Obj4_Type 0;
BA_ "GenSigTimeoutTime_ECM" SG_ 726 PA_Obj4_Type 0;
BA_ "GenSigTimeoutTime_EPS" SG_ 726 PA_Obj4_Type 0;
BA_ "GenSigTimeoutTime_EVCU2" SG_ 726 PA_Obj4_Type 0;
BA_ "GenSigTimeoutTime_ORC" SG_ 726 PA_Obj4_Type 0;
BA_ "GenSigTimeoutTime_BSM" SG_ 726 PA_Obj3_Type 0;
BA_ "GenSigTimeoutTime_BSM2" SG_ 726 PA_Obj3_Type 0;
BA_ "GenSigTimeoutTime_CVPAM" SG_ 726 PA_Obj3_Type 0;
BA_ "GenSigTimeoutTime_ECM" SG_ 726 PA_Obj3_Type 0;
BA_ "GenSigTimeoutTime_EPS" SG_ 726 PA_Obj3_Type 0;
BA_ "GenSigTimeoutTime_EVCU2" SG_ 726 PA_Obj3_Type 0;
BA_ "GenSigTimeoutTime_ORC" SG_ 726 PA_Obj3_Type 0;
BA_ "GenSigTimeoutTime_BSM" SG_ 726 PA_Obj3_Range_2 0;
BA_ "GenSigTimeoutTime_BSM2" SG_ 726 PA_Obj3_Range_2 0;
BA_ "GenSigTimeoutTime_CVPAM" SG_ 726 PA_Obj3_Range_2 0;
BA_ "GenSigTimeoutTime_ECM" SG_ 726 PA_Obj3_Range_2 0;
BA_ "GenSigTimeoutTime_EPS" SG_ 726 PA_Obj3_Range_2 0;
BA_ "GenSigTimeoutTime_EVCU2" SG_ 726 PA_Obj3_Range_2 0;
BA_ "GenSigTimeoutTime_ORC" SG_ 726 PA_Obj3_Range_2 0;
BA_ "GenSigTimeoutTime_BSM" SG_ 726 PA_Obj3_Range 0;
BA_ "GenSigTimeoutTime_BSM2" SG_ 726 PA_Obj3_Range 0;
BA_ "GenSigTimeoutTime_CVPAM" SG_ 726 PA_Obj3_Range 0;
BA_ "GenSigTimeoutTime_ECM" SG_ 726 PA_Obj3_Range 0;
BA_ "GenSigTimeoutTime_EPS" SG_ 726 PA_Obj3_Range 0;
BA_ "GenSigTimeoutTime_EVCU2" SG_ 726 PA_Obj3_Range 0;
BA_ "GenSigTimeoutTime_ORC" SG_ 726 PA_Obj3_Range 0;
BA_ "GenSigTimeoutTime_BSM" SG_ 726 PA_Obj3_Conf 0;
BA_ "GenSigTimeoutTime_BSM2" SG_ 726 PA_Obj3_Conf 0;
BA_ "GenSigTimeoutTime_CVPAM" SG_ 726 PA_Obj3_Conf 0;
BA_ "GenSigTimeoutTime_ECM" SG_ 726 PA_Obj3_Conf 0;
BA_ "GenSigTimeoutTime_EPS" SG_ 726 PA_Obj3_Conf 0;
BA_ "GenSigTimeoutTime_EVCU2" SG_ 726 PA_Obj3_Conf 0;
BA_ "GenSigTimeoutTime_ORC" SG_ 726 PA_Obj3_Conf 0;
BA_ "GenSigTimeoutTime_BSM" SG_ 726 PA_Obj3_Angle_2 0;
BA_ "GenSigTimeoutTime_BSM2" SG_ 726 PA_Obj3_Angle_2 0;
BA_ "GenSigTimeoutTime_CVPAM" SG_ 726 PA_Obj3_Angle_2 0;
BA_ "GenSigTimeoutTime_ECM" SG_ 726 PA_Obj3_Angle_2 0;
BA_ "GenSigTimeoutTime_EPS" SG_ 726 PA_Obj3_Angle_2 0;
BA_ "GenSigTimeoutTime_EVCU2" SG_ 726 PA_Obj3_Angle_2 0;
BA_ "GenSigTimeoutTime_ORC" SG_ 726 PA_Obj3_Angle_2 0;
BA_ "GenSigTimeoutTime_BSM" SG_ 726 PA_Obj3_Angle 0;
BA_ "GenSigTimeoutTime_BSM2" SG_ 726 PA_Obj3_Angle 0;
BA_ "GenSigTimeoutTime_CVPAM" SG_ 726 PA_Obj3_Angle 0;
BA_ "GenSigTimeoutTime_ECM" SG_ 726 PA_Obj3_Angle 0;
BA_ "GenSigTimeoutTime_EPS" SG_ 726 PA_Obj3_Angle 0;
BA_ "GenSigTimeoutTime_EVCU2" SG_ 726 PA_Obj3_Angle 0;
BA_ "GenSigTimeoutTime_ORC" SG_ 726 PA_Obj3_Angle 0;
BA_ "GenSigTimeoutTime_BSM" SG_ 726 PA_Obj2_Type 0;
BA_ "GenSigTimeoutTime_BSM2" SG_ 726 PA_Obj2_Type 0;
BA_ "GenSigTimeoutTime_CVPAM" SG_ 726 PA_Obj2_Type 0;
BA_ "GenSigTimeoutTime_ECM" SG_ 726 PA_Obj2_Type 0;
BA_ "GenSigTimeoutTime_EPS" SG_ 726 PA_Obj2_Type 0;
BA_ "GenSigTimeoutTime_EVCU2" SG_ 726 PA_Obj2_Type 0;
BA_ "GenSigTimeoutTime_ORC" SG_ 726 PA_Obj2_Type 0;
BA_ "GenSigTimeoutTime_BSM" SG_ 726 PA_Obj2_Range_2 0;
BA_ "GenSigTimeoutTime_BSM2" SG_ 726 PA_Obj2_Range_2 0;
BA_ "GenSigTimeoutTime_CVPAM" SG_ 726 PA_Obj2_Range_2 0;
BA_ "GenSigTimeoutTime_ECM" SG_ 726 PA_Obj2_Range_2 0;
BA_ "GenSigTimeoutTime_EPS" SG_ 726 PA_Obj2_Range_2 0;
BA_ "GenSigTimeoutTime_EVCU2" SG_ 726 PA_Obj2_Range_2 0;
BA_ "GenSigTimeoutTime_ORC" SG_ 726 PA_Obj2_Range_2 0;
BA_ "GenSigTimeoutTime_BSM" SG_ 726 PA_Obj2_Range 0;
BA_ "GenSigTimeoutTime_BSM2" SG_ 726 PA_Obj2_Range 0;
BA_ "GenSigTimeoutTime_CVPAM" SG_ 726 PA_Obj2_Range 0;
BA_ "GenSigTimeoutTime_ECM" SG_ 726 PA_Obj2_Range 0;
BA_ "GenSigTimeoutTime_EPS" SG_ 726 PA_Obj2_Range 0;
BA_ "GenSigTimeoutTime_EVCU2" SG_ 726 PA_Obj2_Range 0;
BA_ "GenSigTimeoutTime_ORC" SG_ 726 PA_Obj2_Range 0;
BA_ "GenSigTimeoutTime_BSM" SG_ 726 PA_Obj2_Conf 0;
BA_ "GenSigTimeoutTime_BSM2" SG_ 726 PA_Obj2_Conf 0;
BA_ "GenSigTimeoutTime_CVPAM" SG_ 726 PA_Obj2_Conf 0;
BA_ "GenSigTimeoutTime_ECM" SG_ 726 PA_Obj2_Conf 0;
BA_ "GenSigTimeoutTime_EPS" SG_ 726 PA_Obj2_Conf 0;
BA_ "GenSigTimeoutTime_EVCU2" SG_ 726 PA_Obj2_Conf 0;
BA_ "GenSigTimeoutTime_ORC" SG_ 726 PA_Obj2_Conf 0;
BA_ "GenSigTimeoutTime_BSM" SG_ 726 PA_Obj2_Angle_2 0;
BA_ "GenSigTimeoutTime_BSM2" SG_ 726 PA_Obj2_Angle_2 0;
BA_ "GenSigTimeoutTime_CVPAM" SG_ 726 PA_Obj2_Angle_2 0;
BA_ "GenSigTimeoutTime_ECM" SG_ 726 PA_Obj2_Angle_2 0;
BA_ "GenSigTimeoutTime_EPS" SG_ 726 PA_Obj2_Angle_2 0;
BA_ "GenSigTimeoutTime_EVCU2" SG_ 726 PA_Obj2_Angle_2 0;
BA_ "GenSigTimeoutTime_ORC" SG_ 726 PA_Obj2_Angle_2 0;
BA_ "GenSigTimeoutTime_BSM" SG_ 726 PA_Obj2_Angle 0;
BA_ "GenSigTimeoutTime_BSM2" SG_ 726 PA_Obj2_Angle 0;
BA_ "GenSigTimeoutTime_CVPAM" SG_ 726 PA_Obj2_Angle 0;
BA_ "GenSigTimeoutTime_ECM" SG_ 726 PA_Obj2_Angle 0;
BA_ "GenSigTimeoutTime_EPS" SG_ 726 PA_Obj2_Angle 0;
BA_ "GenSigTimeoutTime_EVCU2" SG_ 726 PA_Obj2_Angle 0;
BA_ "GenSigTimeoutTime_ORC" SG_ 726 PA_Obj2_Angle 0;
BA_ "GenSigTimeoutTime_BSM" SG_ 726 PA_Obj1_Type 0;
BA_ "GenSigTimeoutTime_BSM2" SG_ 726 PA_Obj1_Type 0;
BA_ "GenSigTimeoutTime_CVPAM" SG_ 726 PA_Obj1_Type 0;
BA_ "GenSigTimeoutTime_ECM" SG_ 726 PA_Obj1_Type 0;
BA_ "GenSigTimeoutTime_EPS" SG_ 726 PA_Obj1_Type 0;
BA_ "GenSigTimeoutTime_EVCU2" SG_ 726 PA_Obj1_Type 0;
BA_ "GenSigTimeoutTime_ORC" SG_ 726 PA_Obj1_Type 0;
BA_ "GenSigTimeoutTime_BSM" SG_ 726 PA_Obj1_Range_2 0;
BA_ "GenSigTimeoutTime_BSM2" SG_ 726 PA_Obj1_Range_2 0;
BA_ "GenSigTimeoutTime_CVPAM" SG_ 726 PA_Obj1_Range_2 0;
BA_ "GenSigTimeoutTime_ECM" SG_ 726 PA_Obj1_Range_2 0;
BA_ "GenSigTimeoutTime_EPS" SG_ 726 PA_Obj1_Range_2 0;
BA_ "GenSigTimeoutTime_EVCU2" SG_ 726 PA_Obj1_Range_2 0;
BA_ "GenSigTimeoutTime_ORC" SG_ 726 PA_Obj1_Range_2 0;
BA_ "GenSigTimeoutTime_BSM" SG_ 726 PA_Obj1_Range 0;
BA_ "GenSigTimeoutTime_BSM2" SG_ 726 PA_Obj1_Range 0;
BA_ "GenSigTimeoutTime_CVPAM" SG_ 726 PA_Obj1_Range 0;
BA_ "GenSigTimeoutTime_ECM" SG_ 726 PA_Obj1_Range 0;
BA_ "GenSigTimeoutTime_EPS" SG_ 726 PA_Obj1_Range 0;
BA_ "GenSigTimeoutTime_EVCU2" SG_ 726 PA_Obj1_Range 0;
BA_ "GenSigTimeoutTime_ORC" SG_ 726 PA_Obj1_Range 0;
BA_ "GenSigTimeoutTime_BSM" SG_ 726 PA_Obj1_Conf 0;
BA_ "GenSigTimeoutTime_BSM2" SG_ 726 PA_Obj1_Conf 0;
BA_ "GenSigTimeoutTime_CVPAM" SG_ 726 PA_Obj1_Conf 0;
BA_ "GenSigTimeoutTime_ECM" SG_ 726 PA_Obj1_Conf 0;
BA_ "GenSigTimeoutTime_EPS" SG_ 726 PA_Obj1_Conf 0;
BA_ "GenSigTimeoutTime_EVCU2" SG_ 726 PA_Obj1_Conf 0;
BA_ "GenSigTimeoutTime_ORC" SG_ 726 PA_Obj1_Conf 0;
BA_ "GenSigTimeoutTime_BSM" SG_ 726 PA_Obj1_Angle_2 0;
BA_ "GenSigTimeoutTime_BSM2" SG_ 726 PA_Obj1_Angle_2 0;
BA_ "GenSigTimeoutTime_CVPAM" SG_ 726 PA_Obj1_Angle_2 0;
BA_ "GenSigTimeoutTime_ECM" SG_ 726 PA_Obj1_Angle_2 0;
BA_ "GenSigTimeoutTime_EPS" SG_ 726 PA_Obj1_Angle_2 0;
BA_ "GenSigTimeoutTime_EVCU2" SG_ 726 PA_Obj1_Angle_2 0;
BA_ "GenSigTimeoutTime_ORC" SG_ 726 PA_Obj1_Angle_2 0;
BA_ "GenSigTimeoutTime_BSM" SG_ 726 PA_Obj1_Angle 0;
BA_ "GenSigTimeoutTime_BSM2" SG_ 726 PA_Obj1_Angle 0;
BA_ "GenSigTimeoutTime_CVPAM" SG_ 726 PA_Obj1_Angle 0;
BA_ "GenSigTimeoutTime_ECM" SG_ 726 PA_Obj1_Angle 0;
BA_ "GenSigTimeoutTime_EPS" SG_ 726 PA_Obj1_Angle 0;
BA_ "GenSigTimeoutTime_EVCU2" SG_ 726 PA_Obj1_Angle 0;
BA_ "GenSigTimeoutTime_ORC" SG_ 726 PA_Obj1_Angle 0;
BA_ "GenSigTimeoutTime_BSM" SG_ 726 PA_Front_Sensor_Det_Health 0;
BA_ "GenSigTimeoutTime_BSM2" SG_ 726 PA_Front_Sensor_Det_Health 0;
BA_ "GenSigTimeoutTime_CVPAM" SG_ 726 PA_Front_Sensor_Det_Health 0;
BA_ "GenSigTimeoutTime_ECM" SG_ 726 PA_Front_Sensor_Det_Health 0;
BA_ "GenSigTimeoutTime_EPS" SG_ 726 PA_Front_Sensor_Det_Health 0;
BA_ "GenSigTimeoutTime_EVCU2" SG_ 726 PA_Front_Sensor_Det_Health 0;
BA_ "GenSigTimeoutTime_ORC" SG_ 726 PA_Front_Sensor_Det_Health 0;
BA_ "GenSigTimeoutTime_BSM" SG_ 726 MessageCounter_CVPAM_FD_Data 0;
BA_ "GenSigTimeoutTime_BSM2" SG_ 726 MessageCounter_CVPAM_FD_Data 0;
BA_ "GenSigTimeoutTime_CVPAM" SG_ 726 MessageCounter_CVPAM_FD_Data 0;
BA_ "GenSigTimeoutTime_ECM" SG_ 726 MessageCounter_CVPAM_FD_Data 0;
BA_ "GenSigTimeoutTime_EPS" SG_ 726 MessageCounter_CVPAM_FD_Data 0;
BA_ "GenSigTimeoutTime_EVCU2" SG_ 726 MessageCounter_CVPAM_FD_Data 0;
BA_ "GenSigTimeoutTime_ORC" SG_ 726 MessageCounter_CVPAM_FD_Data 0;
BA_ "GenSigTimeoutTime_BSM" SG_ 726 MAC_CVPAM_FD_Data 0;
BA_ "GenSigTimeoutTime_BSM2" SG_ 726 MAC_CVPAM_FD_Data 0;
BA_ "GenSigTimeoutTime_CVPAM" SG_ 726 MAC_CVPAM_FD_Data 0;
BA_ "GenSigTimeoutTime_ECM" SG_ 726 MAC_CVPAM_FD_Data 0;
BA_ "GenSigTimeoutTime_EPS" SG_ 726 MAC_CVPAM_FD_Data 0;
BA_ "GenSigTimeoutTime_EVCU2" SG_ 726 MAC_CVPAM_FD_Data 0;
BA_ "GenSigTimeoutTime_ORC" SG_ 726 MAC_CVPAM_FD_Data 0;
BA_ "GenSigTimeoutTime_BSM" SG_ 726 CRC_CVPAM_FD_Data 0;
BA_ "GenSigTimeoutTime_BSM2" SG_ 726 CRC_CVPAM_FD_Data 0;
BA_ "GenSigTimeoutTime_CVPAM" SG_ 726 CRC_CVPAM_FD_Data 0;
BA_ "GenSigTimeoutTime_ECM" SG_ 726 CRC_CVPAM_FD_Data 0;
BA_ "GenSigTimeoutTime_EPS" SG_ 726 CRC_CVPAM_FD_Data 0;
BA_ "GenSigTimeoutTime_EVCU2" SG_ 726 CRC_CVPAM_FD_Data 0;
BA_ "GenSigTimeoutTime_ORC" SG_ 726 CRC_CVPAM_FD_Data 0;
BA_ "GenSigStartValue" SG_ 727 PA_SideSensor_RearRight_Dist 1023;
BA_ "GenSigTimeoutTime_BSM" SG_ 727 PA_SideSensor_RearRight_Dist 0;
BA_ "GenSigTimeoutTime_BSM2" SG_ 727 PA_SideSensor_RearRight_Dist 0;
BA_ "GenSigTimeoutTime_CVPAM" SG_ 727 PA_SideSensor_RearRight_Dist 0;
BA_ "GenSigTimeoutTime_ECM" SG_ 727 PA_SideSensor_RearRight_Dist 0;
BA_ "GenSigTimeoutTime_EPS" SG_ 727 PA_SideSensor_RearRight_Dist 0;
BA_ "GenSigTimeoutTime_EVCU2" SG_ 727 PA_SideSensor_RearRight_Dist 0;
BA_ "GenSigTimeoutTime_ORC" SG_ 727 PA_SideSensor_RearRight_Dist 0;
BA_ "GenSigTimeoutTime_BSM" SG_ 727 PA_SideSensor_RearLeft_Conf 0;
BA_ "GenSigTimeoutTime_BSM2" SG_ 727 PA_SideSensor_RearLeft_Conf 0;
BA_ "GenSigTimeoutTime_CVPAM" SG_ 727 PA_SideSensor_RearLeft_Conf 0;
BA_ "GenSigTimeoutTime_ECM" SG_ 727 PA_SideSensor_RearLeft_Conf 0;
BA_ "GenSigTimeoutTime_EPS" SG_ 727 PA_SideSensor_RearLeft_Conf 0;
BA_ "GenSigTimeoutTime_EVCU2" SG_ 727 PA_SideSensor_RearLeft_Conf 0;
BA_ "GenSigTimeoutTime_ORC" SG_ 727 PA_SideSensor_RearLeft_Conf 0;
BA_ "GenSigStartValue" SG_ 727 PA_SideSensor_RearLeft_Dist 1023;
BA_ "GenSigTimeoutTime_BSM" SG_ 727 PA_SideSensor_RearLeft_Dist 0;
BA_ "GenSigTimeoutTime_BSM2" SG_ 727 PA_SideSensor_RearLeft_Dist 0;
BA_ "GenSigTimeoutTime_CVPAM" SG_ 727 PA_SideSensor_RearLeft_Dist 0;
BA_ "GenSigTimeoutTime_ECM" SG_ 727 PA_SideSensor_RearLeft_Dist 0;
BA_ "GenSigTimeoutTime_EPS" SG_ 727 PA_SideSensor_RearLeft_Dist 0;
BA_ "GenSigTimeoutTime_EVCU2" SG_ 727 PA_SideSensor_RearLeft_Dist 0;
BA_ "GenSigTimeoutTime_ORC" SG_ 727 PA_SideSensor_RearLeft_Dist 0;
BA_ "GenSigTimeoutTime_BSM" SG_ 727 PA_SideSensor_RearRight_Conf 0;
BA_ "GenSigTimeoutTime_BSM2" SG_ 727 PA_SideSensor_RearRight_Conf 0;
BA_ "GenSigTimeoutTime_CVPAM" SG_ 727 PA_SideSensor_RearRight_Conf 0;
BA_ "GenSigTimeoutTime_ECM" SG_ 727 PA_SideSensor_RearRight_Conf 0;
BA_ "GenSigTimeoutTime_EPS" SG_ 727 PA_SideSensor_RearRight_Conf 0;
BA_ "GenSigTimeoutTime_EVCU2" SG_ 727 PA_SideSensor_RearRight_Conf 0;
BA_ "GenSigTimeoutTime_ORC" SG_ 727 PA_SideSensor_RearRight_Conf 0;
BA_ "GenSigTimeoutTime_EVCU2" SG_ 727 PA_SideSensor_FrontRight_Conf 0;
BA_ "GenSigTimeoutTime_ORC" SG_ 727 PA_SideSensor_FrontRight_Conf 0;
BA_ "GenSigStartValue" SG_ 727 PA_SideSensor_FrontRight_Dist 1023;
BA_ "GenSigTimeoutTime_BSM" SG_ 727 PA_SideSensor_FrontRight_Dist 0;
BA_ "GenSigTimeoutTime_BSM2" SG_ 727 PA_SideSensor_FrontRight_Dist 0;
BA_ "GenSigTimeoutTime_CVPAM" SG_ 727 PA_SideSensor_FrontRight_Dist 0;
BA_ "GenSigTimeoutTime_ECM" SG_ 727 PA_SideSensor_FrontRight_Dist 0;
BA_ "GenSigTimeoutTime_EPS" SG_ 727 PA_SideSensor_FrontRight_Dist 0;
BA_ "GenSigTimeoutTime_EVCU2" SG_ 727 PA_SideSensor_FrontRight_Dist 0;
BA_ "GenSigTimeoutTime_ORC" SG_ 727 PA_SideSensor_FrontRight_Dist 0;
VAL_ 280 Object_Dist 255 "SNA";
VAL_ 280 ACC_DsrSpeedKPH 255 "SNA";
VAL_ 280 Intervention 4095 "SNA";
VAL_ 280 HIS_Req 0 "Not_Active" 1 "Active";
VAL_ 280 GrMax_Rq_ACC 0 "Passive" 1 "G1" 2 "G2" 3 "G3" 4 "G4" 5 "G5" 6 "G6" 7 "G7" 8 "G8" 9 "G9" 10 "G10" 11 "G11" 12 "G12" 13 "G13" 14 "G14" 15 "G15";
VAL_ 280 CIPV_Fused 0 "Not_Active" 1 "Active";
VAL_ 280 Brake_Jerk_Req 0 "Not_Active" 1 "Active";
VAL_ 280 ACC_Wheel_Torque_Enabled 0 "Not Enabled" 1 "Enabled";
VAL_ 280 ACC_Engine_Torque_Enabled 0 "Not_Enabled" 1 "Enabled";
VAL_ 280 ACC_Drive_Cmd 0 "Not_Enabled" 1 "Enabled";
VAL_ 280 Prefill_Req 0 "No_Prefill_Requested" 1 "Prefill_Requested";
VAL_ 280 PEB_SystemSts 0 "OFF" 1 "ON";
VAL_ 280 MRM_STATUS 0 "Not_Active" 1 "MRM_in_Process" 2 "Vehicle_Secure_Request" 3 "Vehicle_Securement_Complete" 4 "Canceled" 7 "SNA";
VAL_ 280 LANE_CHANGE_SIDE 0 "NO_CHNG" 1 "RIGHT" 2 "LEFT";
VAL_ 280 HAS_Status 0 "Disabled" 1 "Enabled" 2 "Engaged" 3 "Faulted";
VAL_ 280 HAS_OpStat_Prim 0 "Inactive" 1 "FullService" 2 "FailOperational" 3 "FailDegraded" 4 "Emergency" 5 "No_Function";
VAL_ 280 HAS_LAT_CTRL_RequestSts 0 "Idle" 1 "Faulted" 2 "HAS_Request";
VAL_ 280 ESCALATION_TYPE 0 "None" 1 "Driver_Inattention" 2 "Low_Urgency" 3 "Med_Urgency" 4 "High_Urgency";
VAL_ 280 DDD_SystemSts 0 "OFF" 1 "ON";
VAL_ 280 DDD_Setting_Avail 0 "Available" 1 "Not_Available";
VAL_ 280 CADM_OpStat 0 "Inactive" 1 "FullService" 2 "FailOperational" 3 "FailDegraded" 4 "Emergency" 5 "No_Function";
VAL_ 280 AEB_Type 0 "NONE" 1 "ACC" 2 "CMS" 3 "CMS_XTD" 4 "ABA" 5 "LSCM" 6 "PEB" 7 "ICA_L" 8 "ICA_R" 9 "HAS_MRM" 10 "RRCC" 11 "L3" 15 "SNA";
VAL_ 280 AEB_Systemsts 0 "FCW_Off" 1 "FCW_On_Only_Warning" 2 "FCW_On_Full";
VAL_ 280 AEB_Sensitivity_Setting 0 "NEAR" 1 "MEDIUM" 2 "FAR";
VAL_ 280 ACC_Wheel_Torque 65535 "SNA";
VAL_ 280 ACC_Systemsts 0 "OFF" 1 "ACC_Enabled" 2 "ACC_Engaged" 3 "ACC_Engaged_BrakeOnly" 4 "ACC_Cancel" 5 "NCC_Enabled" 6 "NCC_Engaged" 7 "NCC_Cancel" 8 "HAS_BSoC" 9 "RRCC_Enabled_No_Set_Speed" 10 "RRCC_Enabled_With_Set_Speed" 11 "RRCC_Engaged" 12 "L3_Engaged" 13 "L3_Disengaged" 15 "SNA";
VAL_ 280 ACC_StopStart 0 "DEFAULT" 1 "AutoStop_Allowed" 2 "AutoStart_Allowed" 3 "SNA";
VAL_ 727 PA_SideSensor_RearRight_Dist 1023 "SNA";
VAL_ 727 PA_SideSensor_RearRight_Conf 0 "N/A" 1 "LOW" 2 "MED" 3 "HI";
VAL_ 727 PA_SideSensor_RearLeft_Dist 1023 "SNA";
VAL_ 727 PA_SideSensor_RearLeft_Conf 0 "N/A" 1 "LOW" 2 "MED" 3 "HI";
VAL_ 727 PA_SideSensor_FrontRight_Dist 1023 "SNA";
VAL_ 727 PA_SideSensor_FrontRight_Conf 0 "N/A" 1 "LOW" 2 "MED" 3 "HI";
VAL_ 727 PA_SideSensor_FrontLeft_Dist 1023 "SNA";
VAL_ 727 PA_SideSensor_FrontLeft_Conf 0 "N/A" 1 "LOW" 2 "MED" 3 "HI";
VAL_ 727 PA_Right_Sensor_Det_Health 0 "Active" 1 "Not_Active_blocked" 2 "Not_Active_failure" 3 "SNA";
VAL_ 727 PA_Line_RM_Style 0 "None" 1 "Solid" 2 "Dashed" 3 "Double" 4 "Road_Edge" 5 "Botts_Dot" 6 "Barrier" 7 "Other";
VAL_ 727 PA_Line_RM_Color 0 "None" 1 "White" 2 "Yellow" 3 "Orange" 4 "Other";
VAL_ 727 PA_Line_LM_Style 0 "None" 1 "Solid" 2 "Dashed" 3 "Double" 4 "Road_Edge" 5 "Botts_Dot" 6 "Barrier" 7 "Other";
VAL_ 727 PA_Line_LM_Color 0 "None" 1 "White" 2 "Yellow" 3 "Orange" 4 "Other";
VAL_ 727 PA_Left_Sensor_Det_Health 0 "Active" 1 "Not_Active_blocked" 2 "Not_Active_failure" 3 "SNA";
VAL_ 727 PA_Lane_Dection_Health 0 "Active" 1 "Not_Active_blocked" 2 "Not_Active_failure" 3 "SNA";
VAL_ 726 PA_Obj6_Type 0 "None" 1 "Point" 2 "Straight_0_Corner" 3 "Straight_1_Corner" 4 "Straight_2_Corner";
VAL_ 726 PA_Obj6_Conf 0 "N/A" 1 "LOW" 2 "MED" 3 "HI";
VAL_ 726 PA_Obj5_Type 0 "None" 1 "Point" 2 "Straight_0_Corner" 3 "Straight_1_Corner" 4 "Straight_2_Corner";
VAL_ 726 PA_Obj5_Conf 0 "N/A" 1 "LOW" 2 "MED" 3 "HI";
VAL_ 726 PA_Obj4_Type 0 "None" 1 "Point" 2 "Straight_0_Corner" 3 "Straight_1_Corner" 4 "Straight_2_Corner";
VAL_ 726 PA_Obj4_Conf 0 "N/A" 1 "LOW" 2 "MED" 3 "HI";
VAL_ 726 PA_Obj3_Type 0 "None" 1 "Point" 2 "Straight_0_Corner" 3 "Straight_1_Corner" 4 "Straight_2_Corner";
VAL_ 726 PA_Obj3_Conf 0 "N/A" 1 "LOW" 2 "MED" 3 "HI";
VAL_ 726 PA_Obj2_Type 0 "None" 1 "Point" 2 "Straight_0_Corner" 3 "Straight_1_Corner" 4 "Straight_2_Corner";
VAL_ 726 PA_Obj2_Conf 0 "N/A" 1 "LOW" 2 "MED" 3 "HI";
VAL_ 726 PA_Obj1_Type 0 "None" 1 "Point" 2 "Straight_0_Corner" 3 "Straight_1_Corner" 4 "Straight_2_Corner";
VAL_ 726 PA_Obj1_Conf 0 "N/A" 1 "LOW" 2 "MED" 3 "HI";
VAL_ 726 PA_Front_Sensor_Det_Health 0 "Active" 1 "Not_Active_blocked" 2 "Not_Active_failure" 3 "SNA";
VAL_ 1156 RollsModeAct_B2 0 "No Fault" 1 "Fault";
VAL_ 1156 BSM2_FaultSts 0 "Not_active" 1 "Active";
VAL_ 1156 ABSFailSts_B2 0 "Fail_Not_Present" 1 "Fail_Present";
VAL_ 280 SteeringVibration_Type 0 "TYPE_0" 1 "TYPE_1" 2 "TYPE_2" 3 "TYPE_3" 4 "TYPE_4" 5 "TYPE_5" 6 "TYPE_6" 7 "TYPE_7" 8 "TYPE_8" 9 "TYPE_9" 10 "TYPE_10" 11 "TYPE_11" 15 "SNA";
VAL_ 280 SteeringVibration_Rq 0 "NOT_REQUESTED" 1 "REQUESTED";
VAL_ 280 LKA_LAT_CTRL_RequestSts 0 "Idle" 1 "Faulted" 2 "LKA_Request";
VAL_ 280 LANE_CHANGE_STATUS 0 "NO_CHNG" 1 "PEND" 2 "EARLY1" 3 "EARLY2" 4 "LATE" 5 "ABORTING" 6 "ABORTED" 7 "COMPL" 8 "LOCKOUT" 9 "CANCELLING" 10 "CANCELLED" 11 "Lane_Change_Avail_Indication" 12 "Msg_12" 13 "Msg_13" 14 "Msg_14" 15 "SNA";
VAL_ 280 LC_Jerk 0 "Not_Active" 1 "Active";
VAL_ 280 CADM2_EPSSEC_FAIL 0 "False" 1 "True";
VAL_ 1472 TRSC_VehicleStop_Req 0 "False" 1 "True" 3 "SNA";
VAL_ 1472 TRSC_STAT 0 "Standby" 1 "Calibrating" 2 "PreActive" 3 "Active" 4 "OFF" 7 "SNA";
VAL_ 1472 TRSC_SpeedLimit_Req 0 "Not_Limiting" 1 "SPD_4" 2 "SPD_5" 3 "SPD_6" 4 "SPD_7" 5 "SPD_8" 6 "SPD_9" 7 "SPD_10" 15 "SNA";
VAL_ 1472 THA_STAT 0 "Initial" 1 "Idle" 2 "Enabled" 3 "Engaged" 4 "Complete" 5 "Faulted " 7 "SNA";
VAL_ 205 RearAxle_Min_Rq_BSM 0 "Not_Active" 1 "Active";
VAL_ 205 RearAxle_Max_Rq_BSM 0 "Not_Active" 1 "Active";
VAL_ 205 FrontAxle_Min_Rq_BSM 0 "Not_Active" 1 "Active";
VAL_ 205 FrontAxle_Max_Rq_BSM 0 "Not_Active" 1 "Active";
VAL_ 205 TotalAxle_Min_Rq_BSM 0 "Not_Active" 1 "Active";
VAL_ 205 TotalAxle_Max_Rq_BSM 0 "Not_Active" 1 "Active";
VAL_ 205 DrvrIntd_TotalBrk_AxleTorq 32767 "SNA";
VAL_ 205 DriverReq_AxleTrq_Enabled_BSM 0 "No_Req" 1 "ACC_NCC" 2 "SSC" 3 "PPPA" 4 "RRCC" 15 "SNA";
VAL_ 205 Cmnd_TotBrkFrict_AxleTorq 32767 "SNA";
VAL_ 204 Rear_Axle_Regen_Capacity 16383 "SNA";
VAL_ 204 Rear_Axle_Est_Regen_Torq 16383 "SNA";
VAL_ 204 Front_Axle_Regen_Capacity 16383 "SNA";
VAL_ 204 Front_Axle_Est_Regen_Torq 16383 "SNA";
VAL_ 292 BPCM_HV_Trac_Main_Contac_Sts 0 "Open" 1 "Closed" 3 "Error_Stuck_Open" 4 "Error_Stuck_Closed" 7 "SNA";
VAL_ 292 BPCM_HV_Trac_Bus_Sts 0 "Open" 1 "Closed" 2 "Precharging" 3 "Precharging_Failed" 4 "Precharging_Inhibited" 7 "SNA";
VAL_ 1472 THA_SpeedLimit_Req 0 "No_Request" 1 "Requested" 3 "SNA";
VAL_ 1472 THA_Speed_Limit 0 "No_Request" 1 "kph_1" 2 "kph_2" 3 "kph_3" 4 "kph_4" 5 "kph_5" 6 "kph_6" 7 "kph_7" 8 "kph_8" 9 "kph_9" 10 "kph_10" 31 "SNA";
VAL_ 1472 THA_EPB_Req 0 "No_Request" 1 "EPB_Requested" 3 "SNA";
VAL_ 205 TotalAxle_Rq_BSM 65535 "SNA";
VAL_ 205 DriverRequested_AxleTrq_BSM 65535 "SNA";
VAL_ 204 Total_AxleTorque_Min 65535 "SNA";
VAL_ 204 Total_AxleTorque_Max 65535 "SNA";
VAL_ 204 Axle_TorqueStatic_D_TTC 65535 "SNA";
VAL_ 204 Axle_Torque_DrvReqMod 65535 "SNA";
VAL_ 292 BPCM_HV_SOC 1023 "SNA";
VAL_ 292 BPCM_HV_InternalVoltage 16383 "SNA";
VAL_ 205 RearAxle_Rq_BSM 65535 "SNA";
VAL_ 205 FrontAxle_Rq_BSM 65535 "SNA";
VAL_ 204 Rear_AxleTorque_Min 65535 "SNA";
VAL_ 204 Rear_AxleTorque_Max 65535 "SNA";
VAL_ 204 Front_AxleTorque_Min 65535 "SNA";
VAL_ 204 Front_AxleTorque_Max 65535 "SNA";
VAL_ 280 ESASystemSts 0 "Not_Enabled" 1 "Pending" 2 "Pre_Active" 3 "Active" 4 "Locked" 5 "Temporarily_Not_Avail" 6 "Permanently_Not_Available" 7 "SNA";
VAL_ 280 ESA_LAT_CTRL_RequestSts 0 "No_Request" 1 "ESA_Request" 2 "Faulted" 3 "SNA";
VAL_ 280 ESA_LaneClear_Status 0 "NONE" 1 "Left_Clear" 2 "Right_Clear" 3 "Both_Clear" 4 "Neither-Clear" 5 "Undetermined" 7 "SNA";
VAL_ 280 ESA_FailSts 0 "False" 1 "True";
VAL_ 1472 TRSC_SteeringTorqueReq 0 "False" 1 "True" 3 "SNA";
VAL_ 1472 TRSC_SteeringDamping 255 "SNA";
VAL_ 727 PA_Line_RM_Heading_Conf 0 "None" 1 "Low" 2 "Medium" 3 "High";
VAL_ 727 PA_Line_RM_Distance_Conf 0 "None" 1 "Low" 2 "Medium" 3 "High";
VAL_ 727 PA_Line_LM_Heading_Conf 0 "None" 1 "Low" 2 "Medium" 3 "High";
VAL_ 727 PA_Line_LM_Distance_Conf 0 "None" 1 "Low" 2 "Medium" 3 "High";
VAL_ 1472 THA_SteeringTorqueReq 0 "False" 1 "True" 3 "SNA";
VAL_ 2654486701 CBV_bit0_RepeatMessageRequestBit_1E3840AD 0 "Repeat_Msg_State_not_requested" 1 "Repeat_Msg_State_requested";
VAL_ 2654486701 CBV_bit3_NMCoordinatorBit_1E3840AD 0 "Synch_shutdown_not_requested" 1 "Synch_shutdown_requested";
VAL_ 2654486701 CBV_bit4_ActiveWakeupBit_1E3840AD 0 "PassiveWakeup" 1 "ActiveWakeup";
VAL_ 2654486701 CBV_bit6_PartialNtwInfBit_1E3840AD 0 "Partial_Network_info_contained" 1 "No_Partial_Network_info_contained";
VAL_ 2654486689 CBV_bit0_RepeatMessageRequestBit_1E3840A1 0 "Repeat_Msg_State_not_requested" 1 "Repeat_Msg_State_requested";
VAL_ 2654486689 CBV_bit3_NMCoordinatorBit_1E3840A1 0 "Synch_shutdown_not_requested" 1 "Synch_shutdown_requested";
VAL_ 2654486689 CBV_bit4_ActiveWakeupBit_1E3840A1 0 "PassiveWakeup" 1 "ActiveWakeup";
VAL_ 2654486689 CBV_bit6_PartialNtwInfBit_1E3840A1 0 "Partial_Network_info_contained" 1 "No_Partial_Network_info_contained";
VAL_ 2654486554 CBV_bit0_RepeatMessageRequestBit_1E38401A 0 "Repeat Message State not requested" 1 "Repeat Message State requested";
VAL_ 2654486554 CBV_bit3_NMCoordinatorBit_1E38401A 0 "Start of synchronized shutdown is not requested by main coordinator" 1 "Start of synchronized shutdown is requested by main coordinator";
VAL_ 2654486554 CBV_bit4_ActiveWakeupBit_1E38401A 0 "PassiveWakeup" 1 "ActiveWakeup";
VAL_ 2654486554 CBV_bit6_PartialNtwInfBit_1E38401A 0 "NM PDU contains no Partial Network request information" 1 "NM PDU contains Partial Network request information";
SIG_GROUP_ 727 CVPAM_FD_Data2_Pkt 1 : PA_SideSensor_RearRight_Dist PA_SideSensor_RearRight_Conf PA_SideSensor_RearLeft_Dist PA_SideSensor_RearLeft_Conf PA_SideSensor_FrontRight_Dist PA_SideSensor_FrontRight_Conf PA_SideSensor_FrontLeft_Dist PA_SideSensor_FrontLeft_Conf PA_Right_Sensor_Det_Health PA_Line_RM_Style PA_Line_RM_Heading PA_Line_RM_Color PA_Line_LM_Style PA_Line_LM_Heading PA_Line_LM_Color PA_Left_Sensor_Det_Health PA_Lane_Dection_Health MessageCounter_CVPAM_FD_Data2 MAC_CVPAM_FD_Data2 CRC_CVPAM_FD_Data2 Cntr_CVPAM_FD_Data2 Reserved_for_Functional_Safety_ PA_Line_RM_Heading_Conf PA_Line_RM_Distance_Conf PA_Line_RM_Distance PA_Line_LM_Heading_Conf PA_Line_LM_Distance_Conf PA_Line_LM_Distance;
SIG_GROUP_ 726 CVPAM_FD_Data_Pkt 1 : PA_Obj6_Type PA_Obj6_Range_2 PA_Obj6_Range PA_Obj6_Conf PA_Obj6_Angle_2 PA_Obj6_Angle PA_Obj5_Type PA_Obj5_Range_2 PA_Obj5_Range PA_Obj5_Conf PA_Obj5_Angle_2 PA_Obj5_Angle PA_Obj4_Type PA_Obj4_Range_2 PA_Obj4_Range PA_Obj4_Conf PA_Obj4_Angle_2 PA_Obj4_Angle PA_Obj3_Type PA_Obj3_Range_2 PA_Obj3_Range PA_Obj3_Conf PA_Obj3_Angle_2 PA_Obj3_Angle PA_Obj2_Type PA_Obj2_Range_2 PA_Obj2_Range PA_Obj2_Conf PA_Obj2_Angle_2 PA_Obj2_Angle PA_Obj1_Type PA_Obj1_Range_2 PA_Obj1_Range PA_Obj1_Conf PA_Obj1_Angle_2 PA_Obj1_Angle PA_Front_Sensor_Det_Health MessageCounter_CVPAM_FD_Data MAC_CVPAM_FD_Data CRC_CVPAM_FD_Data Cntr_CVPAM_FD_Data Reserved_for_functional_safety_2D6;
SIG_GROUP_ 1156 BRAKE2_FD_3_Pkt 1 : RollsModeAct_B2 MessageCounter_BRAKE2_3 CRC_BRAKE2_3 BSM2_FaultSts ABSFailSts_B2;
SIG_GROUP_ 280 ADAS_FD_INFO_Pkt 1 : Object_Dist MessageCounter_ADAS_FD_INFO CRC_ADAS_FD_INFO ACC_DsrSpeedKPH Intervention HIS_Req GrMax_Rq_ACC CIPV_Fused Brake_Jerk_Req ACC_Wheel_Torque_Enabled ACC_Engine_Torque_Enabled ACC_Drive_Cmd Prefill_Req PEB_SystemSts MRM_STATUS LANE_CHANGE_SIDE HAS_Status HAS_OpStat_Prim HAS_LAT_CTRL_RequestSts ESCALATION_TYPE DDD_SystemSts DDD_Setting_Avail CADM_OpStat AEB_Type AEB_Systemsts AEB_Sensitivity_Setting ACC_Wheel_Torque ACC_Systemsts ACC_StopStart SteeringVibration_Type SteeringVibration_Rq LKA_LAT_CTRL_RequestSts LANE_CHANGE_STATUS LC_Jerk CADM2_EPSSEC_FAIL TorqueOverlaySteeringReq ESASystemSts ESA_TorqueOverlaySteeringReq ESA_LAT_CTRL_RequestSts ESA_LaneClear_Status ESA_FailSts;
SIG_GROUP_ 1472 TRSCM_FD_1_Pkt 1 : TRSC_VehicleStop_Req TRSC_STAT TRSC_SpeedLimit_Req THA_STAT THA_SpeedLimit_Req THA_Speed_Limit THA_EPB_Req MessageCounter_TRSCM1 CRC_TRSCM1 TRSC_SteeringTorqueReq TRSC_SteeringTorqueInfo TRSC_SteeringDamping THA_SteeringTorqueReq THA_SteeringTorqueInfo THA_SteeringDamping;
SIG_GROUP_ 205 BRAKE_FD_6_Pkt 1 : CRC_BRAKE_FD_6 MessageCounter_BRAKE_FD_6 RearAxle_Min_Rq_BSM RearAxle_Max_Rq_BSM FrontAxle_Min_Rq_BSM FrontAxle_Max_Rq_BSM TotalAxle_Min_Rq_BSM TotalAxle_Max_Rq_BSM DrvrIntd_TotalBrk_AxleTorq DriverReq_AxleTrq_Enabled_BSM Cmnd_TotBrkFrict_AxleTorq TotalAxle_Rq_BSM DriverRequested_AxleTrq_BSM RearAxle_Rq_BSM FrontAxle_Rq_BSM;
SIG_GROUP_ 204 AXLE_TORQUE_FD_1_Pkt 1 : MessageCounter_AXLE_TORQUE_FD_1 CRC_AXLE_TORQUE_FD_1 Rear_Axle_Regen_Capacity Rear_Axle_Est_Regen_Torq Front_Axle_Regen_Capacity Front_Axle_Est_Regen_Torq Total_AxleTorque_Min Total_AxleTorque_Max Axle_TorqueStatic_D_TTC Axle_Torque_DrvReqMod Rear_AxleTorque_Min Rear_AxleTorque_Max Front_AxleTorque_Min Front_AxleTorque_Max;
SIG_GROUP_ 292 BATTERY_HV_STATUS1_Pkt 1 : MessageCounter_BATT_HV_STATUS1 CRC_BATT_HV_STATUS1 BPCM_HV_Trac_Main_Contac_Sts BPCM_HV_Trac_Bus_Sts BPCM_HV_SOC BPCM_HV_InternalVoltage;
